VERSION ""

NS_ :

BS_:

BU_: WPC2 RLPSU DPSU APSU PSB SHVU_RR vHS_B2 FCS EMCU SLB ARS RCM CGW_CCU vDummy_HS_B ATS RLHV SGU PFSU ALBCU DSAU SWRC SHVU_FR RCS RRPSU BLTN_CAM SCM DLBCU OHCL RWPC RRHV WPC HOD ASAU

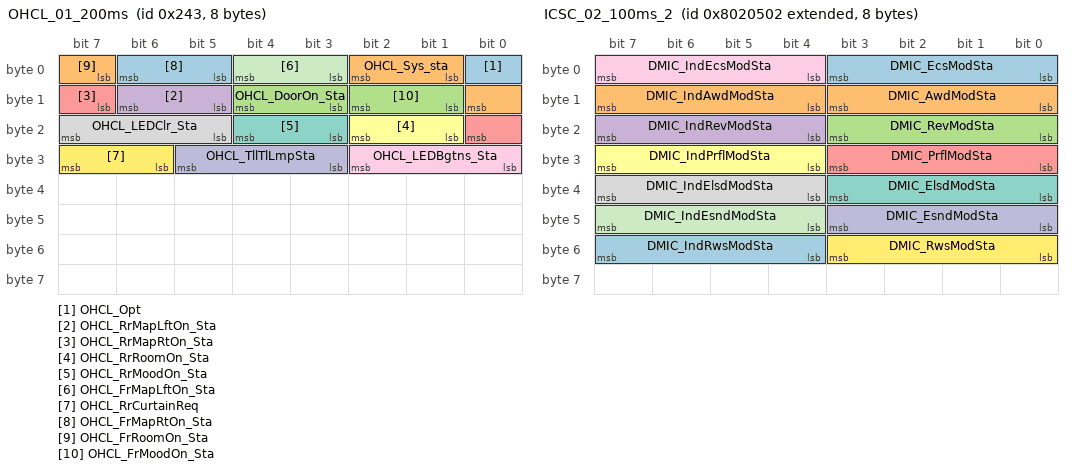
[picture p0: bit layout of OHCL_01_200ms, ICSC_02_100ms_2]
BO_ 579 OHCL_01_200ms: 8 OHCL
 SG_ OHCL_Opt : 0|1@1+ (1,0) [0|0] ""  ATS
 SG_ OHCL_Sys_sta : 1|2@1+ (1,0) [0|0] ""  ATS
 SG_ OHCL_DoorOn_Sta : 11|2@1+ (1,0) [0|0] ""  ATS
 SG_ OHCL_RrMapLftOn_Sta : 13|2@1+ (1,0) [0|0] ""  ATS
 SG_ OHCL_RrMapRtOn_Sta : 15|2@1+ (1,0) [0|0] ""  ATS
 SG_ OHCL_RrRoomOn_Sta : 17|2@1+ (1,0) [0|0] ""  ATS
 SG_ OHCL_RrMoodOn_Sta : 19|2@1+ (1,0) [0|0] ""  ATS
 SG_ OHCL_LEDClr_Sta : 21|3@1+ (1,0) [0|0] ""  ATS
 SG_ OHCL_LEDBgtns_Sta : 24|3@1+ (1,0) [0|0] ""  ATS
 SG_ OHCL_TllTlLmpSta : 27|3@1+ (1,0) [0|0] ""  CGW_CCU
 SG_ OHCL_FrMapLftOn_Sta : 3|2@1+ (1,0) [0|0] ""  ATS
 SG_ OHCL_RrCurtainReq : 30|2@1+ (1,0) [0|0] ""  Vector__XXX
 SG_ OHCL_FrMapRtOn_Sta : 5|2@1+ (1,0) [0|0] ""  ATS
 SG_ OHCL_FrRoomOn_Sta : 7|2@1+ (1,0) [0|0] ""  ATS
 SG_ OHCL_FrMoodOn_Sta : 9|2@1+ (1,0) [0|0] ""  ATS

BO_ 2281833730 ICSC_02_100ms_2: 8 CGW_CCU
 SG_ DMIC_EcsModSta : 0|4@1+ (1,0) [0|0] ""  Vector__XXX
 SG_ DMIC_IndAwdModSta : 12|4@1+ (1,0) [0|0] ""  Vector__XXX
 SG_ DMIC_RevModSta : 16|4@1+ (1,0) [0|0] ""  Vector__XXX
 SG_ DMIC_IndRevModSta : 20|4@1+ (1,0) [0|0] ""  Vector__XXX
 SG_ DMIC_PrflModSta : 24|4@1+ (1,0) [0|0] ""  Vector__XXX
 SG_ DMIC_IndPrflModSta : 28|4@1+ (1,0) [0|0] ""  Vector__XXX
 SG_ DMIC_ElsdModSta : 32|4@1+ (1,0) [0|0] ""  Vector__XXX
 SG_ DMIC_IndElsdModSta : 36|4@1+ (1,0) [0|0] ""  Vector__XXX
 SG_ DMIC_IndEcsModSta : 4|4@1+ (1,0) [0|0] ""  Vector__XXX
 SG_ DMIC_EsndModSta : 40|4@1+ (1,0) [0|0] ""  Vector__XXX
 SG_ DMIC_IndEsndModSta : 44|4@1+ (1,0) [0|0] ""  Vector__XXX
 SG_ DMIC_RwsModSta : 48|4@1+ (1,0) [0|0] ""  Vector__XXX
 SG_ DMIC_IndRwsModSta : 52|4@1+ (1,0) [0|0] ""  Vector__XXX
 SG_ DMIC_AwdModSta : 8|4@1+ (1,0) [0|0] ""  Vector__XXX

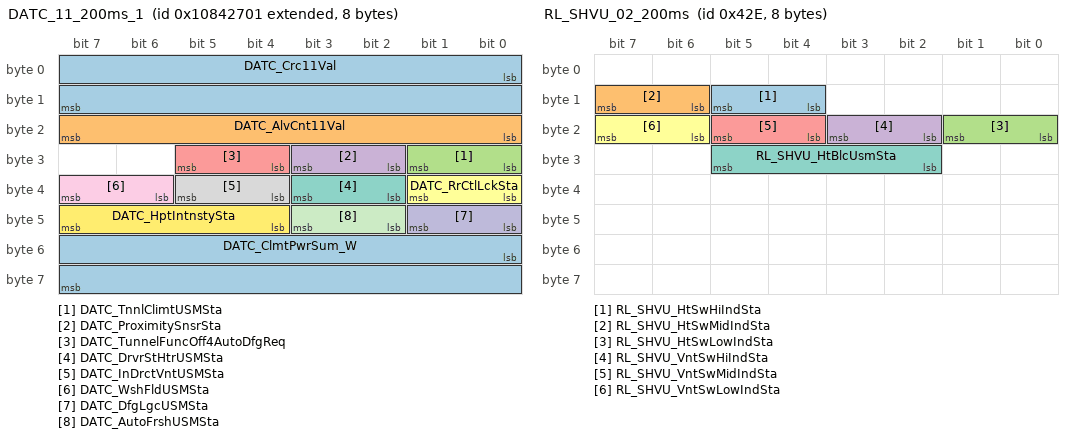
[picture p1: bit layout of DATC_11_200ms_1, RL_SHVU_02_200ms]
BO_ 2424579841 DATC_11_200ms_1: 8 CGW_CCU
 SG_ DATC_Crc11Val : 0|16@1+ (1,0) [0|0] ""  Vector__XXX
 SG_ DATC_AlvCnt11Val : 16|8@1+ (1,0) [0|0] ""  Vector__XXX
 SG_ DATC_TnnlClimtUSMSta : 24|2@1+ (1,0) [0|0] ""  Vector__XXX
 SG_ DATC_ProximitySnsrSta : 26|2@1+ (1,0) [0|0] ""  Vector__XXX
 SG_ DATC_TunnelFuncOff4AutoDfgReq : 28|2@1+ (1,0) [0|0] ""  Vector__XXX
 SG_ DATC_RrCtlLckSta : 32|2@1+ (1,0) [0|0] ""  ATS
 SG_ DATC_DrvrStHtrUSMSta : 34|2@1+ (1,0) [0|0] ""  APSU,DPSU
 SG_ DATC_InDrctVntUSMSta : 36|2@1+ (1,0) [0|0] ""  Vector__XXX
 SG_ DATC_WshFldUSMSta : 38|2@1+ (1,0) [0|0] ""  Vector__XXX
 SG_ DATC_DfgLgcUSMSta : 40|2@1+ (1,0) [0|0] ""  Vector__XXX
 SG_ DATC_AutoFrshUSMSta : 42|2@1+ (1,0) [0|0] ""  Vector__XXX
 SG_ DATC_HptIntnstySta : 44|4@1+ (1,0) [0|0] ""  Vector__XXX
 SG_ DATC_ClmtPwrSum_W : 48|16@1+ (1,0) [0|0] "Wh"  Vector__XXX

BO_ 1070 RL_SHVU_02_200ms: 8 SHVU_RR
 SG_ RL_SHVU_HtSwHiIndSta : 12|2@1+ (1,0) [0|0] ""  ATS,CGW_CCU
 SG_ RL_SHVU_HtSwMidIndSta : 14|2@1+ (1,0) [0|0] ""  ATS,CGW_CCU
 SG_ RL_SHVU_HtSwLowIndSta : 16|2@1+ (1,0) [0|0] ""  ATS,CGW_CCU
 SG_ RL_SHVU_VntSwHiIndSta : 18|2@1+ (1,0) [0|0] ""  ATS,CGW_CCU
 SG_ RL_SHVU_VntSwMidIndSta : 20|2@1+ (1,0) [0|0] ""  ATS,CGW_CCU
 SG_ RL_SHVU_VntSwLowIndSta : 22|2@1+ (1,0) [0|0] ""  ATS,CGW_CCU
 SG_ RL_SHVU_HtBlcUsmSta : 26|4@1+ (1,0) [0|0] ""  ATS,CGW_CCU,CGW_CCU

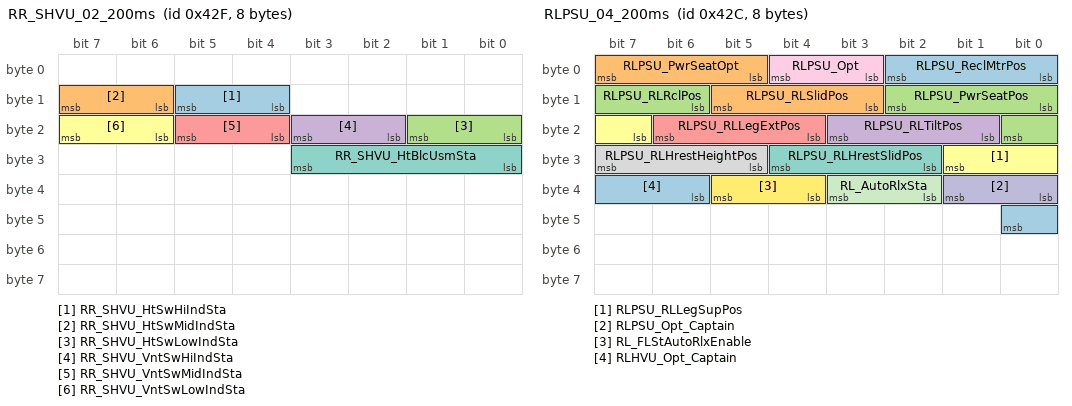
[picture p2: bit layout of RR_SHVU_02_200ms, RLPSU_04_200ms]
BO_ 1071 RR_SHVU_02_200ms: 8 RRPSU
 SG_ RR_SHVU_HtSwHiIndSta : 12|2@1+ (1,0) [0|0] ""  ATS,CGW_CCU
 SG_ RR_SHVU_HtSwMidIndSta : 14|2@1+ (1,0) [0|0] ""  ATS,CGW_CCU
 SG_ RR_SHVU_HtSwLowIndSta : 16|2@1+ (1,0) [0|0] ""  ATS,CGW_CCU
 SG_ RR_SHVU_VntSwHiIndSta : 18|2@1+ (1,0) [0|0] ""  ATS,CGW_CCU
 SG_ RR_SHVU_VntSwMidIndSta : 20|2@1+ (1,0) [0|0] ""  ATS,CGW_CCU
 SG_ RR_SHVU_VntSwLowIndSta : 22|2@1+ (1,0) [0|0] ""  ATS,CGW_CCU
 SG_ RR_SHVU_HtBlcUsmSta : 24|4@1+ (1,0) [0|0] ""  ATS,CGW_CCU,CGW_CCU

BO_ 1068 RLPSU_04_200ms: 8 RRPSU
 SG_ RLPSU_ReclMtrPos : 0|3@1+ (1,0) [0|0] ""  PFSU,CGW_CCU
 SG_ RLPSU_RLSlidPos : 11|3@1+ (1,0) [0|0] ""  CGW_CCU
 SG_ RLPSU_RLRclPos : 14|3@1+ (1,0) [0|0] ""  CGW_CCU
 SG_ RLPSU_RLTiltPos : 17|3@1+ (1,0) [0|0] ""  CGW_CCU
 SG_ RLPSU_RLLegExtPos : 20|3@1+ (1,0) [0|0] ""  CGW_CCU
 SG_ RLPSU_RLLegSupPos : 23|3@1+ (1,0) [0|0] ""  CGW_CCU
 SG_ RLPSU_RLHrestSlidPos : 26|3@1+ (1,0) [0|0] ""  CGW_CCU
 SG_ RLPSU_RLHrestHeightPos : 29|3@1+ (1,0) [0|0] ""  CGW_CCU
 SG_ RLPSU_Opt : 3|2@1+ (1,0) [0|0] ""  CGW_CCU
 SG_ RLPSU_Opt_Captain : 32|2@1+ (1,0) [0|0] ""  CGW_CCU
 SG_ RL_AutoRlxSta : 34|2@1+ (1,0) [0|0] ""  APSU,DPSU
 SG_ RL_FLStAutoRlxEnable : 36|2@1+ (1,0) [0|0] ""  APSU,DPSU
 SG_ RLHVU_Opt_Captain : 38|3@1+ (1,0) [0|0] ""  CGW_CCU
 SG_ RLPSU_PwrSeatOpt : 5|3@1+ (1,0) [0|0] ""  CGW_CCU
 SG_ RLPSU_PwrSeatPos : 8|3@1+ (1,0) [0|0] ""  CGW_CCU

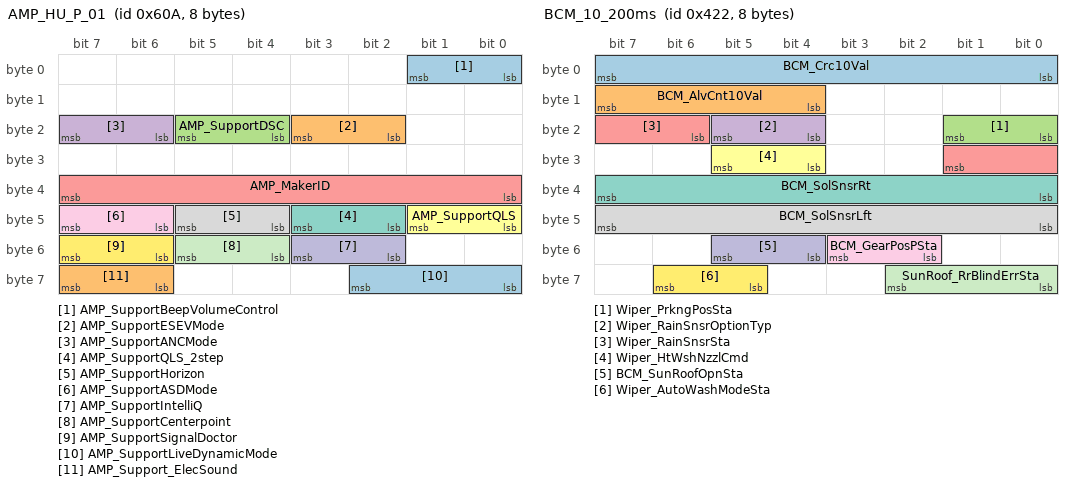
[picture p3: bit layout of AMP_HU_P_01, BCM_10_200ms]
BO_ 1546 AMP_HU_P_01: 8 CGW_CCU
 SG_ AMP_SupportBeepVolumeControl : 0|2@1+ (1,0) [0|0] ""  ATS
 SG_ AMP_SupportESEVMode : 18|2@1+ (1,0) [0|0] ""  Vector__XXX
 SG_ AMP_SupportDSC : 20|2@1+ (1,0) [0|0] ""  Vector__XXX
 SG_ AMP_SupportANCMode : 22|2@1+ (1,0) [0|0] ""  Vector__XXX
 SG_ AMP_MakerID : 32|8@1+ (1,0) [0|0] ""  Vector__XXX
 SG_ AMP_SupportQLS : 40|2@1+ (1,0) [0|0] ""  Vector__XXX
 SG_ AMP_SupportQLS_2step : 42|2@1+ (1,0) [0|0] ""  Vector__XXX
 SG_ AMP_SupportHorizon : 44|2@1+ (1,0) [0|0] ""  Vector__XXX
 SG_ AMP_SupportASDMode : 46|2@1+ (1,0) [0|0] ""  Vector__XXX
 SG_ AMP_SupportIntelliQ : 50|2@1+ (1,0) [0|0] ""  Vector__XXX
 SG_ AMP_SupportCenterpoint : 52|2@1+ (1,0) [0|0] ""  Vector__XXX
 SG_ AMP_SupportSignalDoctor : 54|2@1+ (1,0) [0|0] ""  Vector__XXX
 SG_ AMP_SupportLiveDynamicMode : 56|3@1+ (1,0) [0|0] ""  Vector__XXX
 SG_ AMP_Support_ElecSound : 62|2@1+ (1,0) [0|0] ""  Vector__XXX

BO_ 1069 RRPSU_04_200ms: 8 RRHV
 SG_ RRPSU_ReclMtrPos : 0|3@1+ (1,0) [0|0] ""  PFSU,CGW_CCU
 SG_ RRPSU_PwrSeatOpt : 11|3@1+ (1,0) [0|0] ""  CGW_CCU
 SG_ RRPSU_PwrSeatPos : 14|3@1+ (1,0) [0|0] ""  CGW_CCU
 SG_ RRPSU_RRSlidPos : 17|3@1+ (1,0) [0|0] ""  CGW_CCU
 SG_ RRPSU_RRRclPos : 20|3@1+ (1,0) [0|0] ""  CGW_CCU
 SG_ RRPSU_RRTiltPos : 23|3@1+ (1,0) [0|0] ""  CGW_CCU
 SG_ RRPSU_RRLegExtPos : 26|3@1+ (1,0) [0|0] ""  CGW_CCU
 SG_ RRPSU_RRLegSupPos : 29|3@1+ (1,0) [0|0] ""  CGW_CCU
 SG_ RRPSU_RRStEsyAcsUSMSta : 3|3@1+ (1,0) [0|0] ""  CGW_CCU
 SG_ RRPSU_RRHrestSlidPos : 32|3@1+ (1,0) [0|0] ""  CGW_CCU
 SG_ RRPSU_RRHrestHeightPos : 35|3@1+ (1,0) [0|0] ""  CGW_CCU
 SG_ RRPSU_Opt_Captain : 38|2@1+ (1,0) [0|0] ""  CGW_CCU
 SG_ RR_AutoRlxSta : 40|2@1+ (1,0) [0|0] ""  APSU,DPSU
 SG_ RR_FRStAutoRlxEnable : 42|2@1+ (1,0) [0|0] ""  APSU,DPSU
 SG_ RRHVU_Opt_Captain : 44|3@1+ (1,0) [0|0] ""  CGW_CCU
 SG_ RRPSU_RLStEsyAcsUSMSta : 6|3@1+ (1,0) [0|0] ""  CGW_CCU
 SG_ RRPSU_Opt : 9|2@1+ (1,0) [0|0] ""  CGW_CCU

BO_ 1058 BCM_10_200ms: 8 CGW_CCU
 SG_ BCM_Crc10Val : 0|8@1+ (1,0) [0|0] ""  Vector__XXX
 SG_ BCM_AlvCnt10Val : 12|4@1+ (1,0) [0|0] ""  Vector__XXX
 SG_ Wiper_PrkngPosSta : 16|2@1+ (1,0) [0|0] ""  Vector__XXX
 SG_ Wiper_RainSnsrOptionTyp : 20|2@1+ (1,0) [0|0] ""  Vector__XXX
 SG_ Wiper_RainSnsrSta : 22|4@1+ (1,0) [0|0] ""  Vector__XXX
 SG_ Wiper_HtWshNzzlCmd : 28|2@1+ (1,0) [0|0] ""  Vector__XXX
 SG_ BCM_SolSnsrRt : 32|8@1+ (4.72441,0) [0|0] "W/m2"  Vector__XXX
 SG_ BCM_SolSnsrLft : 40|8@1+ (4.72441,0) [0|0] "W/m2"  Vector__XXX
 SG_ BCM_GearPosPSta : 50|2@1+ (1,0) [0|0] ""  SCM,APSU,RLHV,RRHV,DPSU,PFSU,RRPSU,RLPSU,ATS
 SG_ BCM_SunRoofOpnSta : 52|2@1+ (1,0) [0|0] ""  Vector__XXX
 SG_ SunRoof_RrBlindErrSta : 56|3@1+ (1,0) [0|0] ""  Vector__XXX
 SG_ Wiper_AutoWashModeSta : 61|2@1+ (1,0) [0|0] ""  Vector__XXX

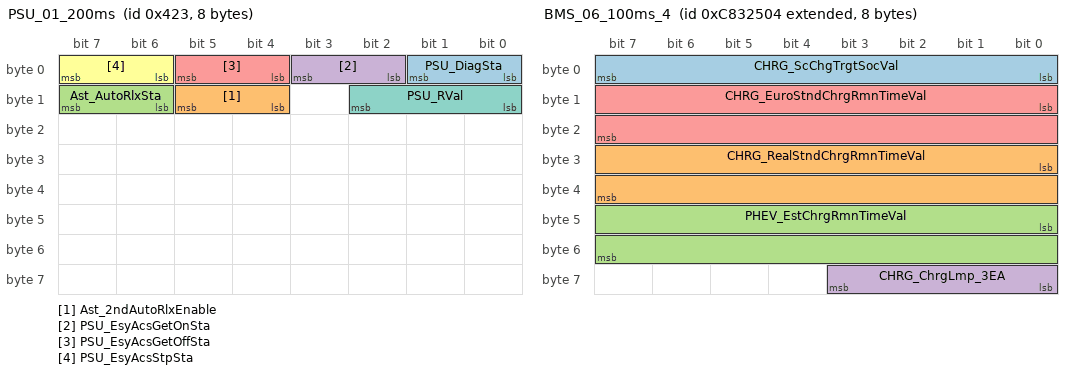
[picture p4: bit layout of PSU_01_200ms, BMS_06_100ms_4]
BO_ 1059 PSU_01_200ms: 8 APSU
 SG_ PSU_DiagSta : 0|2@1+ (1,0) [0|0] ""  Vector__XXX
 SG_ Ast_2ndAutoRlxEnable : 12|2@1+ (1,0) [0|0] ""  RLPSU,RRPSU
 SG_ Ast_AutoRlxSta : 14|2@1+ (1,0) [0|0] ""  RLPSU,RRPSU
 SG_ PSU_EsyAcsGetOnSta : 2|2@1+ (1,0) [0|0] ""  SLB
 SG_ PSU_EsyAcsGetOffSta : 4|2@1+ (1,0) [0|0] ""  SLB
 SG_ PSU_EsyAcsStpSta : 6|2@1+ (1,0) [0|0] ""  SLB
 SG_ PSU_RVal : 8|3@1+ (1,0) [0|0] ""  Vector__XXX

BO_ 2357404932 BMS_06_100ms_4: 8 CGW_CCU
 SG_ CHRG_ScChgTrgtSocVal : 0|8@1+ (0.5,0) [0|0] "%"  Vector__XXX
 SG_ CHRG_RealStndChrgRmnTimeVal : 24|16@1+ (1,0) [0|0] "minute"  Vector__XXX
 SG_ PHEV_EstChrgRmnTimeVal : 40|16@1+ (1,0) [0|0] "min"  Vector__XXX
 SG_ CHRG_ChrgLmp_3EA : 56|4@1+ (1,0) [0|0] "minute"  Vector__XXX
 SG_ CHRG_EuroStndChrgRmnTimeVal : 8|16@1+ (1,0) [0|0] "minute"  Vector__XXX

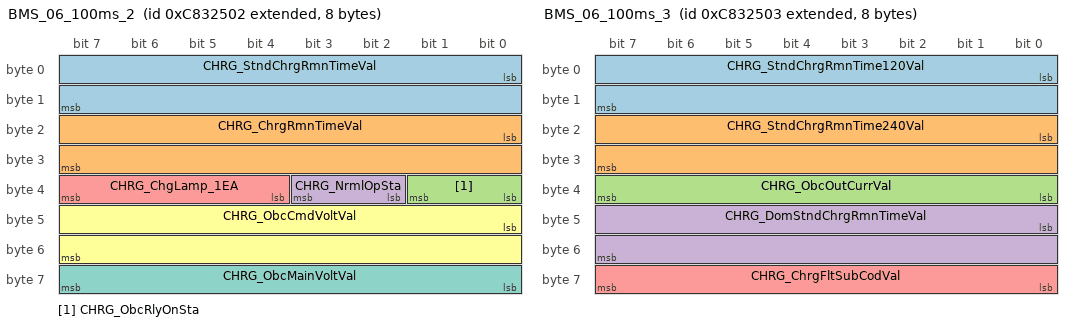
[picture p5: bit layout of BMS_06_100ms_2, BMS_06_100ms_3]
BO_ 2357404930 BMS_06_100ms_2: 8 CGW_CCU
 SG_ CHRG_StndChrgRmnTimeVal : 0|16@1+ (1,0) [0|0] "minute"  Vector__XXX
 SG_ CHRG_ChrgRmnTimeVal : 16|16@1+ (1,0) [0|0] "min"  Vector__XXX
 SG_ CHRG_ObcRlyOnSta : 32|2@1+ (1,0) [0|0] ""  Vector__XXX
 SG_ CHRG_NrmlOpSta : 34|2@1+ (1,0) [0|0] ""  Vector__XXX
 SG_ CHRG_ChgLamp_1EA : 36|4@1+ (1,0) [0|0] ""  Vector__XXX
 SG_ CHRG_ObcCmdVoltVal : 40|16@1+ (0.1,0) [0|0] "V"  Vector__XXX
 SG_ CHRG_ObcMainVoltVal : 56|8@1+ (2,0) [0|0] "V"  Vector__XXX

BO_ 2357404931 BMS_06_100ms_3: 8 CGW_CCU
 SG_ CHRG_StndChrgRmnTime120Val : 0|16@1+ (1,0) [0|0] "minute"  Vector__XXX
 SG_ CHRG_StndChrgRmnTime240Val : 16|16@1+ (1,0) [0|0] "minute"  Vector__XXX
 SG_ CHRG_ObcOutCurrVal : 32|8@1+ (0.1,0) [0|0] "A"  Vector__XXX
 SG_ CHRG_DomStndChrgRmnTimeVal : 40|16@1+ (1,0) [0|0] "minute"  Vector__XXX
 SG_ CHRG_ChrgFltSubCodVal : 56|8@1+ (1,0) [0|0] ""  Vector__XXX

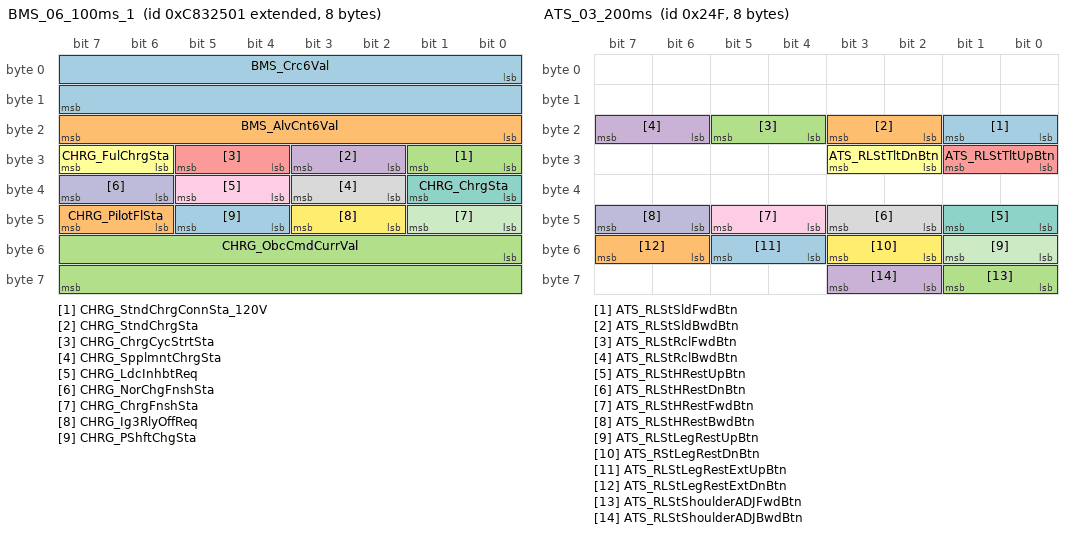
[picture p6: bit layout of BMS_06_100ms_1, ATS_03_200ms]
BO_ 2357404929 BMS_06_100ms_1: 8 CGW_CCU
 SG_ BMS_Crc6Val : 0|16@1+ (1,0) [0|0] ""  Vector__XXX
 SG_ BMS_AlvCnt6Val : 16|8@1+ (1,0) [0|0] ""  Vector__XXX
 SG_ CHRG_StndChrgConnSta_120V : 24|2@1+ (1,0) [0|0] "flag"  Vector__XXX
 SG_ CHRG_StndChrgSta : 26|2@1+ (1,0) [0|0] ""  Vector__XXX
 SG_ CHRG_ChrgCycStrtSta : 28|2@1+ (1,0) [0|0] ""  Vector__XXX
 SG_ CHRG_FulChrgSta : 30|2@1+ (1,0) [0|0] ""  Vector__XXX
 SG_ CHRG_ChrgSta : 32|2@1+ (1,0) [0|0] ""  SWRC
 SG_ CHRG_SpplmntChrgSta : 34|2@1+ (1,0) [0|0] ""  Vector__XXX
 SG_ CHRG_LdcInhbtReq : 36|2@1+ (1,0) [0|0] ""  Vector__XXX
 SG_ CHRG_NorChgFnshSta : 38|2@1+ (1,0) [0|0] ""  Vector__XXX
 SG_ CHRG_ChrgFnshSta : 40|2@1+ (1,0) [0|0] ""  Vector__XXX
 SG_ CHRG_Ig3RlyOffReq : 42|2@1+ (1,0) [0|0] ""  Vector__XXX
 SG_ CHRG_PShftChgSta : 44|2@1+ (1,0) [0|0] "flag"  Vector__XXX
 SG_ CHRG_PilotFlSta : 46|2@1+ (1,0) [0|0] "flag"  Vector__XXX
 SG_ CHRG_ObcCmdCurrVal : 48|16@1+ (0.1,0) [0|0] "A"  Vector__XXX

BO_ 591 ATS_03_200ms: 8 ATS
 SG_ ATS_RLStSldFwdBtn : 16|2@1+ (1,0) [0|0] ""  Vector__XXX
 SG_ ATS_RLStSldBwdBtn : 18|2@1+ (1,0) [0|0] ""  Vector__XXX
 SG_ ATS_RLStRclFwdBtn : 20|2@1+ (1,0) [0|0] ""  Vector__XXX
 SG_ ATS_RLStRclBwdBtn : 22|2@1+ (1,0) [0|0] ""  Vector__XXX
 SG_ ATS_RLStTltUpBtn : 24|2@1+ (1,0) [0|0] ""  Vector__XXX
 SG_ ATS_RLStTltDnBtn : 26|2@1+ (1,0) [0|0] ""  Vector__XXX
 SG_ ATS_RLStHRestUpBtn : 40|2@1+ (1,0) [0|0] ""  Vector__XXX
 SG_ ATS_RLStHRestDnBtn : 42|2@1+ (1,0) [0|0] ""  Vector__XXX
 SG_ ATS_RLStHRestFwdBtn : 44|2@1+ (1,0) [0|0] ""  Vector__XXX
 SG_ ATS_RLStHRestBwdBtn : 46|2@1+ (1,0) [0|0] ""  Vector__XXX
 SG_ ATS_RLStLegRestUpBtn : 48|2@1+ (1,0) [0|0] ""  Vector__XXX
 SG_ ATS_RStLegRestDnBtn : 50|2@1+ (1,0) [0|0] ""  Vector__XXX
 SG_ ATS_RLStLegRestExtUpBtn : 52|2@1+ (1,0) [0|0] ""  Vector__XXX
 SG_ ATS_RLStLegRestExtDnBtn : 54|2@1+ (1,0) [0|0] ""  Vector__XXX
 SG_ ATS_RLStShoulderADJFwdBtn : 56|2@1+ (1,0) [0|0] ""  Vector__XXX
 SG_ ATS_RLStShoulderADJBwdBtn : 58|2@1+ (1,0) [0|0] ""  Vector__XXX

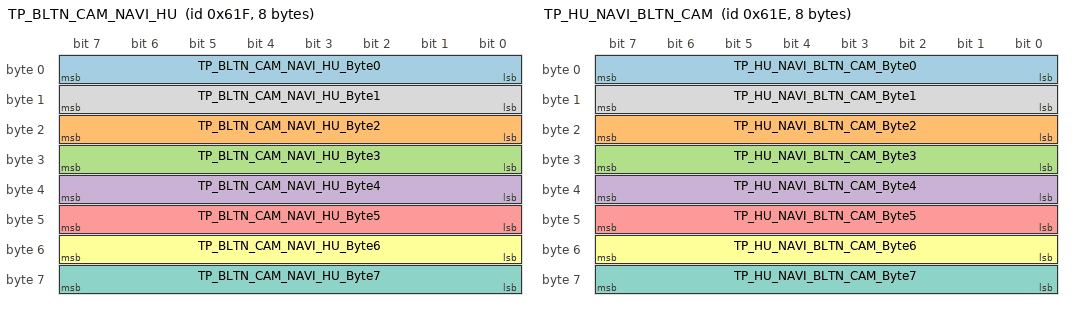
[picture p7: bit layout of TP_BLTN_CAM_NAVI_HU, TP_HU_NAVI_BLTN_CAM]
BO_ 1567 TP_BLTN_CAM_NAVI_HU: 8 BLTN_CAM
 SG_ TP_BLTN_CAM_NAVI_HU_Byte0 : 0|8@1+ (1,0) [0|0] ""  CGW_CCU
 SG_ TP_BLTN_CAM_NAVI_HU_Byte2 : 16|8@1+ (1,0) [0|0] ""  CGW_CCU
 SG_ TP_BLTN_CAM_NAVI_HU_Byte3 : 24|8@1+ (1,0) [0|0] ""  CGW_CCU
 SG_ TP_BLTN_CAM_NAVI_HU_Byte4 : 32|8@1+ (1,0) [0|0] ""  CGW_CCU
 SG_ TP_BLTN_CAM_NAVI_HU_Byte5 : 40|8@1+ (1,0) [0|0] ""  CGW_CCU
 SG_ TP_BLTN_CAM_NAVI_HU_Byte6 : 48|8@1+ (1,0) [0|0] ""  CGW_CCU
 SG_ TP_BLTN_CAM_NAVI_HU_Byte7 : 56|8@1+ (1,0) [0|0] ""  CGW_CCU
 SG_ TP_BLTN_CAM_NAVI_HU_Byte1 : 8|8@1+ (1,0) [0|0] ""  CGW_CCU

BO_ 1566 TP_HU_NAVI_BLTN_CAM: 8 CGW_CCU
 SG_ TP_HU_NAVI_BLTN_CAM_Byte0 : 0|8@1+ (1,0) [0|0] ""  BLTN_CAM
 SG_ TP_HU_NAVI_BLTN_CAM_Byte2 : 16|8@1+ (1,0) [0|0] ""  BLTN_CAM
 SG_ TP_HU_NAVI_BLTN_CAM_Byte3 : 24|8@1+ (1,0) [0|0] ""  BLTN_CAM
 SG_ TP_HU_NAVI_BLTN_CAM_Byte4 : 32|8@1+ (1,0) [0|0] ""  BLTN_CAM
 SG_ TP_HU_NAVI_BLTN_CAM_Byte5 : 40|8@1+ (1,0) [0|0] ""  BLTN_CAM
 SG_ TP_HU_NAVI_BLTN_CAM_Byte6 : 48|8@1+ (1,0) [0|0] ""  BLTN_CAM
 SG_ TP_HU_NAVI_BLTN_CAM_Byte7 : 56|8@1+ (1,0) [0|0] ""  BLTN_CAM
 SG_ TP_HU_NAVI_BLTN_CAM_Byte1 : 8|8@1+ (1,0) [0|0] ""  BLTN_CAM

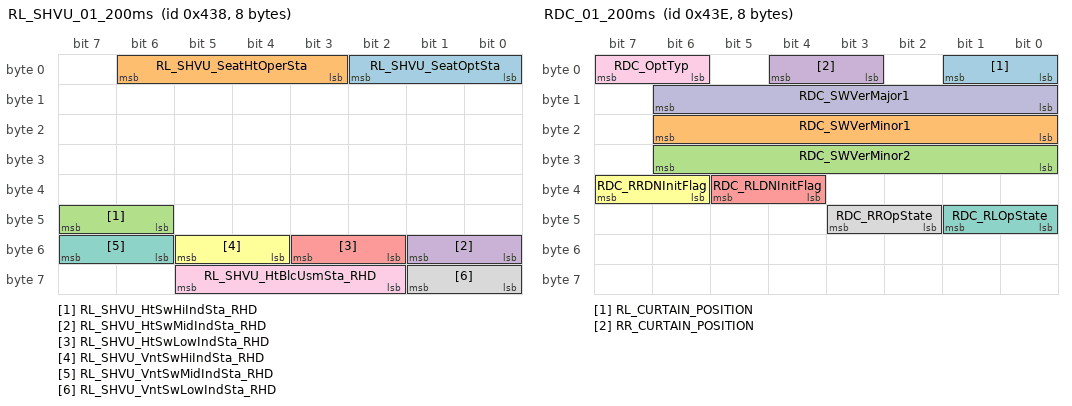
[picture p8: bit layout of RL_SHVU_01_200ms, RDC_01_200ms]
BO_ 1080 RL_SHVU_01_200ms: 8 SHVU_FR
 SG_ RL_SHVU_SeatOptSta : 0|3@1+ (1,0) [0|0] ""  ATS,CGW_CCU
 SG_ RL_SHVU_SeatHtOperSta : 3|4@1+ (1,0) [0|0] ""  ATS,CGW_CCU
 SG_ RL_SHVU_HtSwHiIndSta_RHD : 46|2@1+ (1,0) [0|0] ""  ATS,CGW_CCU,CGW_CCU
 SG_ RL_SHVU_HtSwMidIndSta_RHD : 48|2@1+ (1,0) [0|0] ""  ATS,CGW_CCU
 SG_ RL_SHVU_HtSwLowIndSta_RHD : 50|2@1+ (1,0) [0|0] ""  ATS,CGW_CCU
 SG_ RL_SHVU_VntSwHiIndSta_RHD : 52|2@1+ (1,0) [0|0] ""  ATS,CGW_CCU
 SG_ RL_SHVU_VntSwMidIndSta_RHD : 54|2@1+ (1,0) [0|0] ""  ATS,CGW_CCU
 SG_ RL_SHVU_VntSwLowIndSta_RHD : 56|2@1+ (1,0) [0|0] ""  ATS,CGW_CCU
 SG_ RL_SHVU_HtBlcUsmSta_RHD : 58|4@1+ (1,0) [0|0] ""  ATS,CGW_CCU

BO_ 1086 RDC_01_200ms: 8 CGW_CCU
 SG_ RL_CURTAIN_POSITION : 0|2@1+ (1,0) [0|0] ""  ATS
 SG_ RDC_SWVerMinor1 : 16|7@1+ (1,0) [0|0] ""  Vector__XXX
 SG_ RDC_SWVerMinor2 : 24|7@1+ (1,0) [0|0] ""  Vector__XXX
 SG_ RR_CURTAIN_POSITION : 3|2@1+ (1,0) [0|0] ""  ATS
 SG_ RDC_RLDNInitFlag : 36|2@1+ (1,0) [0|0] ""  Vector__XXX
 SG_ RDC_RRDNInitFlag : 38|2@1+ (1,0) [0|0] ""  Vector__XXX
 SG_ RDC_RLOpState : 40|2@1+ (1,0) [0|0] ""  Vector__XXX
 SG_ RDC_RROpState : 42|2@1+ (1,0) [0|0] ""  Vector__XXX
 SG_ RDC_OptTyp : 6|2@1+ (1,0) [0|0] ""  ATS
 SG_ RDC_SWVerMajor1 : 8|7@1+ (1,0) [0|0] ""  Vector__XXX

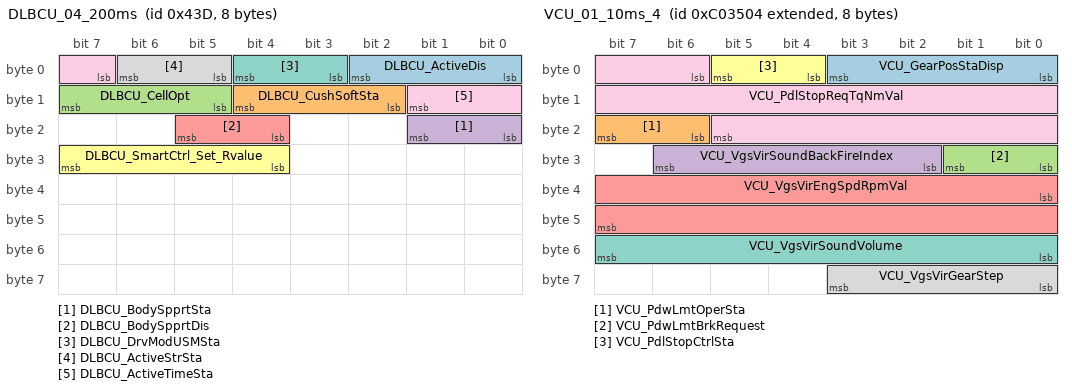
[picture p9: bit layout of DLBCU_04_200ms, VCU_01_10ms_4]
BO_ 1085 DLBCU_04_200ms: 8 DLBCU
 SG_ DLBCU_ActiveDis : 0|3@1+ (1,0) [0|0] ""  CGW_CCU
 SG_ DLBCU_CushSoftSta : 10|3@1+ (1,0) [0|0] ""  CGW_CCU
 SG_ DLBCU_CellOpt : 13|3@1+ (1,0) [0|0] ""  Vector__XXX
 SG_ DLBCU_BodySpprtSta : 16|2@1+ (1,0) [0|0] ""  CGW_CCU
 SG_ DLBCU_BodySpprtDis : 20|2@1+ (1,0) [0|0] ""  CGW_CCU
 SG_ DLBCU_SmartCtrl_Set_Rvalue : 28|4@1+ (1,0) [0|0] ""  CGW_CCU
 SG_ DLBCU_DrvModUSMSta : 3|2@1+ (1,0) [0|0] ""  CGW_CCU
 SG_ DLBCU_ActiveStrSta : 5|2@1+ (1,0) [0|0] ""  CGW_CCU
 SG_ DLBCU_ActiveTimeSta : 7|3@1+ (1,0) [0|0] ""  CGW_CCU

BO_ 2160080132 VCU_01_10ms_4: 8 CGW_CCU
 SG_ VCU_GearPosStaDisp : 0|4@1+ (1,0) [0|0] ""  SWRC,BLTN_CAM
 SG_ VCU_PdwLmtOperSta : 22|2@1+ (1,0) [0|0] ""  Vector__XXX
 SG_ VCU_PdwLmtBrkRequest : 24|2@1+ (1,0) [0|0] ""  Vector__XXX
 SG_ VCU_VgsVirSoundBackFireIndex : 26|5@1+ (1,0) [0|0] ""  Vector__XXX
 SG_ VCU_VgsVirEngSpdRpmVal : 32|16@1- (1,0) [0|0] ""  Vector__XXX
 SG_ VCU_PdlStopCtrlSta : 4|2@1+ (1,0) [0|0] ""  Vector__XXX
 SG_ VCU_VgsVirSoundVolume : 48|8@1+ (0.392156863,0) [0|0] ""  Vector__XXX
 SG_ VCU_VgsVirGearStep : 56|4@1+ (1,0) [0|0] ""  Vector__XXX
 SG_ VCU_PdlStopReqTqNmVal : 6|16@1+ (1,0) [0|0] ""  Vector__XXX

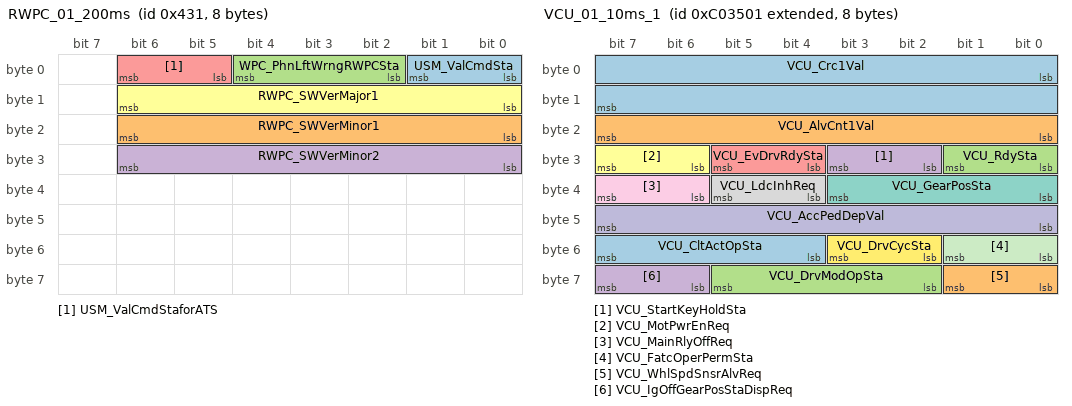
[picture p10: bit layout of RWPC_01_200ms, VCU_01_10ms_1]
BO_ 1073 RWPC_01_200ms: 8 RWPC
 SG_ USM_ValCmdSta : 0|2@1+ (1,0) [0|0] ""  ATS,CGW_CCU
 SG_ RWPC_SWVerMinor1 : 16|7@1+ (1,0) [0|0] ""  CGW_CCU
 SG_ WPC_PhnLftWrngRWPCSta : 2|3@1+ (1,0) [0|0] ""  ATS,CGW_CCU
 SG_ RWPC_SWVerMinor2 : 24|7@1+ (1,0) [0|0] ""  CGW_CCU
 SG_ USM_ValCmdStaforATS : 5|2@1+ (1,0) [0|0] ""  ATS
 SG_ RWPC_SWVerMajor1 : 8|7@1+ (1,0) [0|0] ""  CGW_CCU

BO_ 2160080129 VCU_01_10ms_1: 8 CGW_CCU
 SG_ VCU_Crc1Val : 0|16@1+ (1,0) [0|0] ""  Vector__XXX
 SG_ VCU_AlvCnt1Val : 16|8@1+ (1,0) [0|0] ""  Vector__XXX
 SG_ VCU_RdySta : 24|2@1+ (1,0) [0|3] ""  Vector__XXX
 SG_ VCU_StartKeyHoldSta : 26|2@1+ (1,0) [0|3] ""  Vector__XXX
 SG_ VCU_EvDrvRdySta : 28|2@1+ (1,0) [0|3] ""  WPC,RWPC,SWRC,APSU,RLHV,RRHV,SHVU_FR,SHVU_RR,DPSU,DLBCU,PFSU,RRPSU,RLPSU,HOD,RCM,BLTN_CAM,WPC2
 SG_ VCU_MotPwrEnReq : 30|2@1+ (1,0) [0|3] ""  Vector__XXX
 SG_ VCU_GearPosSta : 32|4@1+ (1,0) [0|15] ""  SWRC,APSU,DPSU,PFSU,RRPSU,RLPSU,BLTN_CAM,WPC2
 SG_ VCU_LdcInhReq : 36|2@1+ (1,0) [0|3] ""  Vector__XXX
 SG_ VCU_MainRlyOffReq : 38|2@1+ (1,0) [0|3] ""  Vector__XXX
 SG_ VCU_AccPedDepVal : 40|8@1+ (0.3921568627,0) [0|100] "%"  BLTN_CAM
 SG_ VCU_FatcOperPermSta : 48|2@1+ (1,0) [0|3] ""  Vector__XXX
 SG_ VCU_DrvCycSta : 50|2@1+ (1,0) [0|3] ""  Vector__XXX
 SG_ VCU_CltActOpSta : 52|4@1+ (1,0) [0|15] ""  Vector__XXX
 SG_ VCU_WhlSpdSnsrAlvReq : 56|2@1+ (1,0) [0|0] "flag"  Vector__XXX
 SG_ VCU_DrvModOpSta : 58|4@1+ (1,0) [0|0] ""  Vector__XXX
 SG_ VCU_IgOffGearPosStaDispReq : 62|2@1+ (1,0) [0|0] "flag"  Vector__XXX

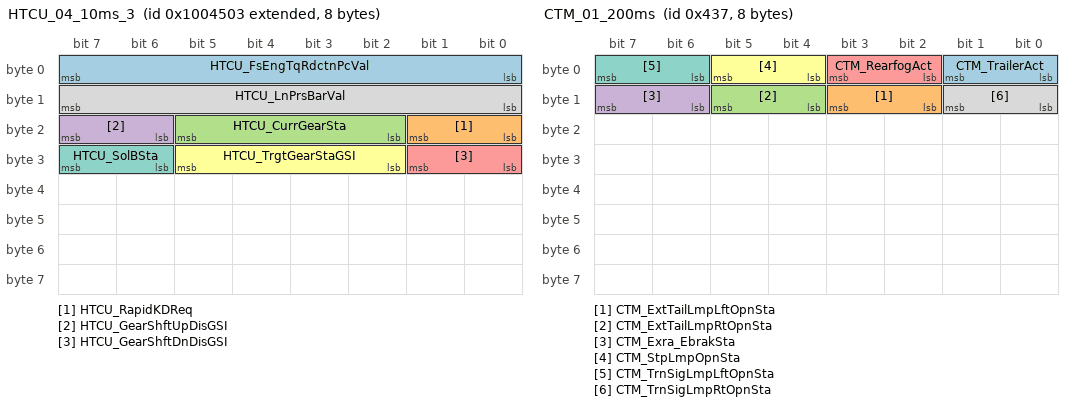
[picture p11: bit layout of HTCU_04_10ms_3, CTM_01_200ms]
BO_ 2164278531 HTCU_04_10ms_3: 8 CGW_CCU
 SG_ HTCU_FsEngTqRdctnPcVal : 0|8@1+ (0.390625,0) [0|0] "%"  Vector__XXX
 SG_ HTCU_RapidKDReq : 16|2@1+ (1,0) [0|0] ""  Vector__XXX
 SG_ HTCU_CurrGearSta : 18|4@1+ (1,0) [0|0] ""  Vector__XXX
 SG_ HTCU_GearShftUpDisGSI : 22|2@1+ (1,0) [0|0] ""  Vector__XXX
 SG_ HTCU_GearShftDnDisGSI : 24|2@1+ (1,0) [0|0] ""  Vector__XXX
 SG_ HTCU_TrgtGearStaGSI : 26|4@1+ (1,0) [0|0] ""  Vector__XXX
 SG_ HTCU_SolBSta : 30|2@1+ (1,0) [0|0] ""  Vector__XXX
 SG_ HTCU_LnPrsBarVal : 8|8@1+ (0.1,0) [0|0] "Bar"  Vector__XXX

BO_ 1079 CTM_01_200ms: 8 CGW_CCU
 SG_ CTM_TrailerAct : 0|2@1+ (1,0) [0|0] ""  BLTN_CAM
 SG_ CTM_ExtTailLmpLftOpnSta : 10|2@1+ (1,0) [0|0] ""  Vector__XXX
 SG_ CTM_ExtTailLmpRtOpnSta : 12|2@1+ (1,0) [0|0] ""  Vector__XXX
 SG_ CTM_Exra_EbrakSta : 14|2@1+ (1,0) [0|0] ""  Vector__XXX
 SG_ CTM_RearfogAct : 2|2@1+ (1,0) [0|0] ""  Vector__XXX
 SG_ CTM_StpLmpOpnSta : 4|2@1+ (1,0) [0|0] ""  Vector__XXX
 SG_ CTM_TrnSigLmpLftOpnSta : 6|2@1+ (1,0) [0|0] ""  Vector__XXX
 SG_ CTM_TrnSigLmpRtOpnSta : 8|2@1+ (1,0) [0|0] ""  Vector__XXX

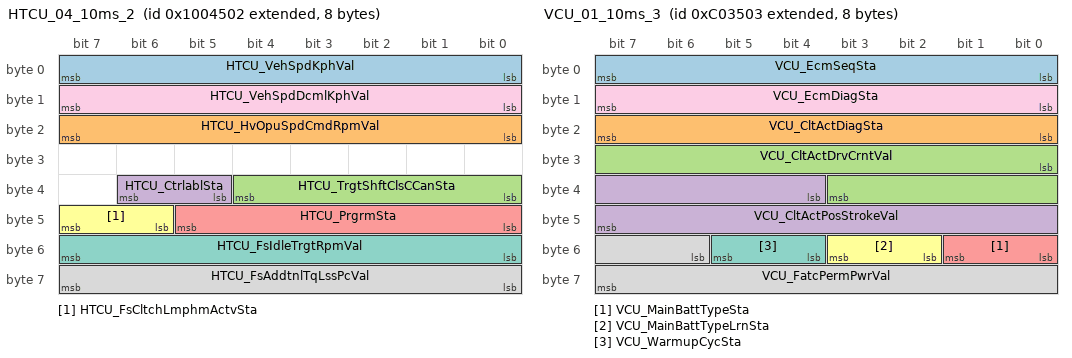
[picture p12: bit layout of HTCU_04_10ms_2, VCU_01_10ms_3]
BO_ 2164278530 HTCU_04_10ms_2: 8 CGW_CCU
 SG_ HTCU_VehSpdKphVal : 0|8@1+ (1,0) [0|0] "kph"  Vector__XXX
 SG_ HTCU_HvOpuSpdCmdRpmVal : 16|8@1+ (20,0) [0|0] "rpm"  Vector__XXX
 SG_ HTCU_TrgtShftClsCCanSta : 32|5@1+ (1,0) [0|0] ""  Vector__XXX
 SG_ HTCU_CtrlablSta : 37|2@1+ (1,0) [0|0] ""  Vector__XXX
 SG_ HTCU_PrgrmSta : 40|6@1+ (1,0) [0|0] ""  Vector__XXX
 SG_ HTCU_FsCltchLmphmActvSta : 46|2@1+ (1,0) [0|0] ""  Vector__XXX
 SG_ HTCU_FsIdleTrgtRpmVal : 48|8@1+ (10,0) [0|0] "rpm"  Vector__XXX
 SG_ HTCU_FsAddtnlTqLssPcVal : 56|8@1+ (0.390625,0) [0|0] "%"  Vector__XXX
 SG_ HTCU_VehSpdDcmlKphVal : 8|8@1+ (0.0078125,0) [0|0] "kph"  Vector__XXX

BO_ 2160080131 VCU_01_10ms_3: 8 CGW_CCU
 SG_ VCU_EcmSeqSta : 0|8@1+ (1,0) [0|255] ""  Vector__XXX
 SG_ VCU_CltActDiagSta : 16|8@1+ (1,0) [0|255] ""  Vector__XXX
 SG_ VCU_CltActDrvCrntVal : 24|12@1- (0.025,0) [-51.2|51.175] "A"  Vector__XXX
 SG_ VCU_CltActPosStrokeVal : 36|12@1- (0.0125,0) [-25.6|25.5875] "mm"  Vector__XXX
 SG_ VCU_MainBattTypeSta : 48|2@1+ (1,0) [0|3] ""  Vector__XXX
 SG_ VCU_MainBattTypeLrnSta : 50|2@1+ (1,0) [0|3] ""  Vector__XXX
 SG_ VCU_WarmupCycSta : 52|2@1+ (1,0) [0|3] ""  Vector__XXX
 SG_ VCU_FatcPermPwrVal : 54|10@1+ (20,0) [0|12700] "W"  Vector__XXX
 SG_ VCU_EcmDiagSta : 8|8@1+ (1,0) [0|255] ""  Vector__XXX

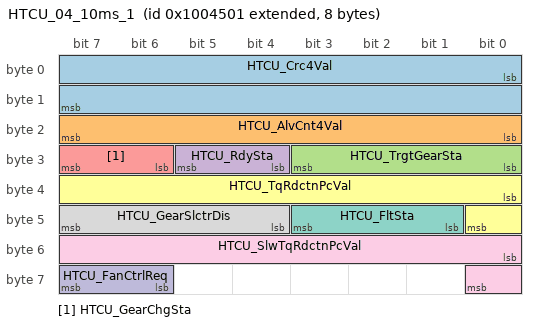
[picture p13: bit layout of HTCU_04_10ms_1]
BO_ 2164278529 HTCU_04_10ms_1: 8 CGW_CCU
 SG_ HTCU_Crc4Val : 0|16@1+ (1,0) [0|0] ""  Vector__XXX
 SG_ HTCU_AlvCnt4Val : 16|8@1+ (1,0) [0|0] ""  Vector__XXX
 SG_ HTCU_TrgtGearSta : 24|4@1+ (1,0) [0|0] ""  Vector__XXX
 SG_ HTCU_RdySta : 28|2@1+ (1,0) [0|0] ""  Vector__XXX
 SG_ HTCU_GearChgSta : 30|2@1+ (1,0) [0|0] ""  Vector__XXX
 SG_ HTCU_TqRdctnPcVal : 32|9@1+ (0.390625,0) [0|0] "%"  Vector__XXX
 SG_ HTCU_FltSta : 41|3@1+ (1,0) [0|0] ""  Vector__XXX
 SG_ HTCU_GearSlctrDis : 44|4@1+ (1,0) [0|0] ""  SWRC,BLTN_CAM
 SG_ HTCU_SlwTqRdctnPcVal : 48|9@1+ (0.390625,0) [0|0] "%"  Vector__XXX
 SG_ HTCU_FanCtrlReq : 62|2@1+ (1,0) [0|0] ""  Vector__XXX

BO_TX_BU_ 1070 : SHVU_RR,RLHV,RLPSU,SHVU_FR;
BO_TX_BU_ 1071 : RRPSU,SHVU_FR,SHVU_RR,RRHV;
BO_TX_BU_ 1068 : RRPSU,RLPSU,RLHV;
BO_TX_BU_ 1069 : RRHV,RRPSU;
BO_TX_BU_ 1080 : SHVU_FR,SHVU_RR,RLHV,RLPSU;
CM_ BO_ 1546 "[P] Periodic";
CM_ SG_ 1546 AMP_SupportBeepVolumeControl "Information for AMPsupport configurable Beep1
send 500msec after Booting up";
CM_ SG_ 1546 AMP_SupportESEVMode "Information for AMP support ESEV(Engine Sound by Engine Vibration).";
CM_ SG_ 1546 AMP_SupportDSC "Does amp support Dynamic Speed Compensation mode?";
CM_ SG_ 1546 AMP_SupportANCMode "Does AMP support ANC?";
CM_ SG_ 1546 AMP_MakerID "Information for AMP Maker
For model afrer 2014, use 0x01~0x03 only.
* Use Only 0x01~0x03 values after 2014 *";
CM_ SG_ 1546 AMP_SupportQLS "Information for amp support Quantum Logic Surround mode
Harman AMP Only";
CM_ SG_ 1546 AMP_SupportQLS_2step "Information for amp support 2 Step Quantum Logic Surround mode Harman AMP Only";
CM_ SG_ 1546 AMP_SupportHorizon "Information for amp support Meridian Horizon mode Meridian AMP Only";
CM_ SG_ 1546 AMP_SupportASDMode "Information for  AMP support ASD (Active Sound Design, Virtual Engine Sound)";
CM_ SG_ 1546 AMP_SupportIntelliQ "Does amp support Meridian Intelli-Q mode?";
CM_ SG_ 1546 AMP_SupportCenterpoint "Does amp support CenterPoint mode?";
CM_ SG_ 1546 AMP_SupportSignalDoctor "Information for amp support SignalDoctor(=Clarifi)
Harman AMP Only";
CM_ SG_ 1546 AMP_SupportLiveDynamicMode "Information for amp
 Support
 LiveDynamic mode";
CM_ SG_ 1546 AMP_Support_ElecSound "inform to H/U & CLU whether amp support premium electric sound or not";
CM_ BO_ 591 "[PE] Periodic and On Event";
CM_ SG_ 591 ATS_RLStSldFwdBtn "Rear Left Power Seat Slide Forward Touch Button";
CM_ SG_ 591 ATS_RLStSldBwdBtn "Rear Left Power Seat Slide Backward Touch Button";
CM_ SG_ 591 ATS_RLStRclFwdBtn "Rear Left Power Seat Recline Forward Touch Button";
CM_ SG_ 591 ATS_RLStRclBwdBtn "Rear Left Power Seat Recline Backward Touch Button";
CM_ SG_ 591 ATS_RLStTltUpBtn "Rear Left Power Seat Tilt Up Touch Button";
CM_ SG_ 591 ATS_RLStTltDnBtn "Rear Left Power Seat Tilt Down Touch Button";
CM_ SG_ 591 ATS_RLStHRestUpBtn "Rear Left Power Seat Head Rest Up Touch Button";
CM_ SG_ 591 ATS_RLStHRestDnBtn "Rear Left Power Seat Head Rest Down Touch Button";
CM_ SG_ 591 ATS_RLStHRestFwdBtn "Rear Left Power Seat Head Rest Forward Touch Button";
CM_ SG_ 591 ATS_RLStHRestBwdBtn "Rear Left Power Seat Head Rest Backward Touch Button";
CM_ SG_ 591 ATS_RLStLegRestUpBtn "Rear Left Power Seat Leg Rest Up Touch Button";
CM_ SG_ 591 ATS_RStLegRestDnBtn "Rear Left Power Seat Leg Rest Down Touch Button";
CM_ SG_ 591 ATS_RLStLegRestExtUpBtn "Rear Left Power Seat Leg Rest Ext. Up Touch Button";
CM_ SG_ 591 ATS_RLStLegRestExtDnBtn "Rear Left Power Seat Leg Rest Ext. Down Touch Button";
CM_ SG_ 591 ATS_RLStShoulderADJFwdBtn "Rear Left Power Seat Shoulder Adjuster Forward Touch Button";
CM_ SG_ 591 ATS_RLStShoulderADJBwdBtn "Rear Left Power Seat Shoulder Adjuster Backward Touch Button";
CM_ BO_ 1058 "[PE] Periodic and On Event";
CM_ SG_ 1058 BCM_Crc10Val "BCM_CyclicRedundancyCheck10Value";
CM_ SG_ 1058 BCM_AlvCnt10Val "BCM_AliveCounter10Value";
CM_ SG_ 1058 Wiper_PrkngPosSta "Wiper_ParkingPositionStatus ##2G##BCM - BCMmsg22 - C_WiperParkPosition";
CM_ SG_ 1058 Wiper_RainSnsrOptionTyp "Wiper_RainSensorOptionType ##2G##BCM - BCMmsg24 - C_RainSnsOption";
CM_ SG_ 1058 Wiper_RainSnsrSta "Wiper_RainSensorStatus ##2G##BCM - BCMmsg24 - C_RainSnsState";
CM_ SG_ 1058 BCM_SolSnsrRt "BCM_SolarSensorRightOutputVoltageValue ##2G##BCM - BCMmsg24 - C_PhotosensorRH";
CM_ SG_ 1058 BCM_SolSnsrLft "BCM_SolarSensorLeftOutputVoltageValue ##2G##BCM - BCMmsg24 - C_PhotosensorLH";
CM_ SG_ 1058 BCM_GearPosPSta "BCM_GearPositionPStatus ##2G##BCM - BCMmsg17 - C_PpositiOn";
CM_ SG_ 1058 BCM_SunRoofOpnSta "BCM_SunRoofOpenStatus ##2G##BCM - BCMmsg20 - C_SunRoofOpenState";
CM_ SG_ 1058 Wiper_AutoWashModeSta "Auto Wash Mode Wiper State";
CM_ BO_ 2357404929 "[P] Periodic";
CM_ SG_ 2357404929 BMS_Crc6Val "BMS_CyclicRedundancyCheck6Value";
CM_ SG_ 2357404929 BMS_AlvCnt6Val "BMS_AliveCounter6Value";
CM_ SG_ 2357404929 CHRG_StndChrgConnSta_120V "CHRG_StandardChargeConnectStatus";
CM_ SG_ 2357404929 CHRG_StndChrgSta "CHRG_StandardChargeStatus";
CM_ SG_ 2357404929 CHRG_ChrgCycStrtSta "CHRG_ChargingCycleStartStatus";
CM_ SG_ 2357404929 CHRG_FulChrgSta "CHRG_FullyChargeStatus";
CM_ SG_ 2357404929 CHRG_ChrgSta "CHRG_ChargeStatus";
CM_ SG_ 2357404929 CHRG_SpplmntChrgSta "CHRG_SupplementaryChargeStatus";
CM_ SG_ 2357404929 CHRG_LdcInhbtReq "CHRG_LdcInhibitRequest";
CM_ SG_ 2357404929 CHRG_NorChgFnshSta "CHRG_ChargeNormalFinishConditionStatus";
CM_ SG_ 2357404929 CHRG_ChrgFnshSta "CHRG_ChargeFinishStatus";
CM_ SG_ 2357404929 CHRG_Ig3RlyOffReq "CHRG_Ig3RelayOffRequest";
CM_ SG_ 2357404929 CHRG_PShftChgSta "CHRG_PShiftChangeStatus";
CM_ SG_ 2357404929 CHRG_PilotFlSta "CHRG_PilotlineFailStatus";
CM_ SG_ 2357404929 CHRG_ObcCmdCurrVal "CHRG_ObcCommandCurrentValue";
CM_ BO_ 2357404930 "[P] Periodic";
CM_ SG_ 2357404930 CHRG_StndChrgRmnTimeVal "CHRG_StandardChargeRemainedTimeValue";
CM_ SG_ 2357404930 CHRG_ChrgRmnTimeVal "CHRG_ChargeRemainedTimeValue";
CM_ SG_ 2357404930 CHRG_ObcRlyOnSta "CHRG_ObcRelayOnStatus";
CM_ SG_ 2357404930 CHRG_NrmlOpSta "CHRG_NormalOperationStatus";
CM_ SG_ 2357404930 CHRG_ChgLamp_1EA "CHRG_ChargeLampRequest (1EA Lamp)";
CM_ SG_ 2357404930 CHRG_ObcCmdVoltVal "CHRG_ObcCommandVoltageValue";
CM_ SG_ 2357404930 CHRG_ObcMainVoltVal "CHRG_ObcMainVoltageValue";
CM_ BO_ 2357404931 "[P] Periodic";
CM_ SG_ 2357404931 CHRG_StndChrgRmnTime120Val "CHRG_StandardChargeRemainedTime120Value";
CM_ SG_ 2357404931 CHRG_StndChrgRmnTime240Val "CHRG_StandardChargeRemainedTime240Value";
CM_ SG_ 2357404931 CHRG_ObcOutCurrVal "CHRG_ObcOutputCurrentValue";
CM_ SG_ 2357404931 CHRG_DomStndChrgRmnTimeVal "CHRG_DomesticStandardChargeRemainedTime";
CM_ SG_ 2357404931 CHRG_ChrgFltSubCodVal "CHRG_ChargeFaultSubCodeValue";
CM_ BO_ 2357404932 "[P] Periodic";
CM_ SG_ 2357404932 CHRG_ScChgTrgtSocVal "CHRG_TargetStateOfScChargeValue";
CM_ SG_ 2357404932 CHRG_RealStndChrgRmnTimeVal "CHRG_RealStandardChargeRemainedTime";
CM_ SG_ 2357404932 PHEV_EstChrgRmnTimeVal "PHEV_EstimatedChargeRemainedTimeValue";
CM_ SG_ 2357404932 CHRG_ChrgLmp_3EA "CHRG_Charge Lamp(3EA Lamp)";
CM_ SG_ 2357404932 CHRG_EuroStndChrgRmnTimeVal "CHRG_EuroStandardChargeRemainedTime";
CM_ BO_ 1079 "[PE] Periodic and On Event";
CM_ SG_ 1079 CTM_TrailerAct "This signal is used for control the Trailer Act function.";
CM_ SG_ 1079 CTM_ExtTailLmpLftOpnSta "Trailer Exterior Tail Lamp Left OpenStatus";
CM_ SG_ 1079 CTM_ExtTailLmpRtOpnSta "Trailer Exterior Tail Lamp Right OpenStatus";
CM_ SG_ 1079 CTM_Exra_EbrakSta "Trailer Exterior Ebrake Out OnOffStatus";
CM_ SG_ 1079 CTM_RearfogAct "This signal is used for display the rear fog lamp mounted on the trailer.";
CM_ SG_ 1079 CTM_StpLmpOpnSta "Trailer Stop Lamp OpenStatus";
CM_ SG_ 1079 CTM_TrnSigLmpLftOpnSta "Trailer T/SIG Lamp Left OpenStatus";
CM_ SG_ 1079 CTM_TrnSigLmpRtOpnSta "Trailer T/SIG Lamp Right OpenStatus";
CM_ BO_ 2424579841 "[PE] Periodic and On Event";
CM_ SG_ 2424579841 DATC_Crc11Val "DATC_CyclicRedundancyCheck11Value";
CM_ SG_ 2424579841 DATC_AlvCnt11Val "DATC_AliveCounter11Value";
CM_ SG_ 2424579841 DATC_TnnlClimtUSMSta "DATC_TunnelCLimateUSMState";
CM_ SG_ 2424579841 DATC_ProximitySnsrSta "DATC_ProximitySensorStatus";
CM_ SG_ 2424579841 DATC_TunnelFuncOff4AutoDfgReq "DATC_TunnelFunctionOffForAutoDefogRequest";
CM_ SG_ 2424579841 DATC_RrCtlLckSta "Datc_RearClimateControlLockStatus";
CM_ SG_ 2424579841 DATC_DrvrStHtrUSMSta "DATC_DriverSeatHeaterUSMStatus";
CM_ SG_ 2424579841 DATC_InDrctVntUSMSta "DATC_InDirectVent_USM_State";
CM_ SG_ 2424579841 DATC_WshFldUSMSta "DATC_WasherFulidUSMState";
CM_ SG_ 2424579841 DATC_DfgLgcUSMSta "DefLogic USM State";
CM_ SG_ 2424579841 DATC_AutoFrshUSMSta "Auto Fresh USM State";
CM_ SG_ 2424579841 DATC_HptIntnstySta "Haptic Intensity State";
CM_ SG_ 2424579841 DATC_ClmtPwrSum_W "accumulated energy consumption while driving(200ms)";
CM_ BO_ 1085 "[PE] Periodic and On Event";
CM_ SG_ 1085 DLBCU_ActiveDis "DLBCU_ActiveModeDisplay";
CM_ SG_ 1085 DLBCU_CushSoftSta "DLBCU_CushionSoftnessStatus";
CM_ SG_ 1085 DLBCU_CellOpt "DLBCU_CellOption Status";
CM_ SG_ 1085 DLBCU_BodySpprtSta "Seat Body Support Function USM R Value";
CM_ SG_ 1085 DLBCU_BodySpprtDis "Seat body Support Function Display Request";
CM_ SG_ 1085 DLBCU_SmartCtrl_Set_Rvalue "ÁÖÇà Áß Çã¸® º¸È£ ±â´É USM µ¿ÀÛ ¼³Á¤ °ª (R Value)";
CM_ SG_ 1085 DLBCU_DrvModUSMSta "DLBCU_DriveModeStatus";
CM_ SG_ 1085 DLBCU_ActiveStrSta "DLBCU_ActiveStrengthStatus";
CM_ SG_ 1085 DLBCU_ActiveTimeSta "DLBCU_ActiveTimeStatus";
CM_ BO_ 2164278529 "[P] Periodic";
CM_ SG_ 2164278529 HTCU_Crc4Val "HTCU_CyclicRedundancyCheck4Value";
CM_ SG_ 2164278529 HTCU_AlvCnt4Val "HTCU_AliveCounter4Value";
CM_ SG_ 2164278529 HTCU_TrgtGearSta "HTCU_TargetGearStatus";
CM_ SG_ 2164278529 HTCU_RdySta "HTCU_ReadyStatus";
CM_ SG_ 2164278529 HTCU_GearChgSta "HTCU_GearChangeStatus";
CM_ SG_ 2164278529 HTCU_TqRdctnPcVal "HTCU_TorqueReductionPcValue";
CM_ SG_ 2164278529 HTCU_FltSta "HTCU_FaultStatus";
CM_ SG_ 2164278529 HTCU_GearSlctrDis "HTCU_GearSelectDisplay";
CM_ SG_ 2164278529 HTCU_SlwTqRdctnPcVal "HTCU_SlowTorqueReductionPcValue";
CM_ SG_ 2164278529 HTCU_FanCtrlReq "Fan control request by OPU";
CM_ BO_ 2164278530 "[P] Periodic";
CM_ SG_ 2164278530 HTCU_VehSpdKphVal "HTCU_VehicleSpeedKphValue";
CM_ SG_ 2164278530 HTCU_HvOpuSpdCmdRpmVal "HTCU_HvOpuSpeedCommandRpmValue";
CM_ SG_ 2164278530 HTCU_TrgtShftClsCCanSta "HTCU_TargetShiftClassCCanStatus";
CM_ SG_ 2164278530 HTCU_PrgrmSta "HTCU_ProgramStatus";
CM_ SG_ 2164278530 HTCU_FsCltchLmphmActvSta "HTCU_FsClutchLimphomeActivationStatus";
CM_ SG_ 2164278530 HTCU_FsIdleTrgtRpmVal "HTCU_FsIdleTargetRpmValue";
CM_ SG_ 2164278530 HTCU_FsAddtnlTqLssPcVal "HTCU_FsAdditionalTorqueLossPcValue";
CM_ SG_ 2164278530 HTCU_VehSpdDcmlKphVal "HTCU_VehicleSpeedDecimalKphValue";
CM_ BO_ 2164278531 "[P] Periodic";
CM_ SG_ 2164278531 HTCU_FsEngTqRdctnPcVal "HTCU_FsEngineTorqueReductionPcValue";
CM_ SG_ 2164278531 HTCU_RapidKDReq "HTCU_RapidKDRequest";
CM_ SG_ 2164278531 HTCU_CurrGearSta "HTCU_CurrentGearStatus";
CM_ SG_ 2164278531 HTCU_GearShftUpDisGSI "HTCU_GearShiftUpDisplayGSI";
CM_ SG_ 2164278531 HTCU_GearShftDnDisGSI "HTCU_GearShiftDownDisplayGSI";
CM_ SG_ 2164278531 HTCU_TrgtGearStaGSI "HTCU_TargetGearStatusGSI";
CM_ SG_ 2164278531 HTCU_SolBSta "HTCU_SolenoidBStatus";
CM_ SG_ 2164278531 HTCU_LnPrsBarVal "HTCU_LinePressureBarValue";
CM_ BO_ 2281833730 "[P] Periodic";
CM_ SG_ 2281833730 DMIC_EcsModSta "DMIC_EcsModeStatus ##2G##ICSC - IVSS11 - MODE_ECS";
CM_ SG_ 2281833730 DMIC_IndAwdModSta "DMIC_IndividualAwdModeStatus ##2G##ICSC - IVSS11 - MODE_4WD_IND";
CM_ SG_ 2281833730 DMIC_RevModSta "DMIC_RevModeStatus ##2G##ICSC - IVSS11 - MODE_REV";
CM_ SG_ 2281833730 DMIC_IndRevModSta "DMIC_IndividualRevModeStatus ##2G##ICSC - IVSS11 - MODE_REV_IND";
CM_ SG_ 2281833730 DMIC_PrflModSta "DMIC_PrflModeStatus ##2G##ICSC - IVSS11 - MODE_PRFL";
CM_ SG_ 2281833730 DMIC_IndPrflModSta "DMIC_IndividualPrflModeStatus ##2G##ICSC - IVSS11 - MODE_PRFL_IND";
CM_ SG_ 2281833730 DMIC_ElsdModSta "DMIC_ElsdModeStatus ##2G##ICSC - IVSS11 - MODE_ELSD";
CM_ SG_ 2281833730 DMIC_IndElsdModSta "DMIC_IndividualElsdModeStatus ##2G##ICSC - IVSS11 - MODE_ELSD_IND";
CM_ SG_ 2281833730 DMIC_IndEcsModSta "DMIC_IndividualEcsModeStatus ##2G##ICSC - IVSS11 - MODE_ECS_IND";
CM_ SG_ 2281833730 DMIC_EsndModSta "DMIC_EsndModeStatus ##2G##ICSC - IVSS11 - MODE_ESND";
CM_ SG_ 2281833730 DMIC_IndEsndModSta "DMIC_IndividualEsndModeStatus ##2G##ICSC - IVSS11 - MODE_ESND_IND";
CM_ SG_ 2281833730 DMIC_RwsModSta "DMIC_RwsModeStatus";
CM_ SG_ 2281833730 DMIC_IndRwsModSta "DMIC_IndividualRwsModeStatus";
CM_ SG_ 2281833730 DMIC_AwdModSta "DMIC_AwdModeStatus ##2G##ICSC - IVSS11 - MODE_4WD";
CM_ BO_ 579 "[PE] Periodic and On Event";
CM_ SG_ 579 OHCL_Opt "OHCL option state";
CM_ SG_ 579 OHCL_Sys_sta "OHCL Status";
CM_ SG_ 579 OHCL_DoorOn_Sta "Door lamp switch On/Off status";
CM_ SG_ 579 OHCL_RrMapLftOn_Sta "Rear left map lamp On/Off status";
CM_ SG_ 579 OHCL_RrMapRtOn_Sta "Rear right map lamp On/Off status";
CM_ SG_ 579 OHCL_RrRoomOn_Sta "Rear room lamp On/Off status";
CM_ SG_ 579 OHCL_RrMoodOn_Sta "Rear mood lamp On/Off status";
CM_ SG_ 579 OHCL_LEDClr_Sta "Interior lamps lighting color status";
CM_ SG_ 579 OHCL_LEDBgtns_Sta "Interior lamps brightness status";
CM_ SG_ 579 OHCL_TllTlLmpSta "PAB tell tale lamp status";
CM_ SG_ 579 OHCL_FrMapLftOn_Sta "Front left map lamp On/Off status";
CM_ SG_ 579 OHCL_RrCurtainReq "Rear Curtain Switch On/Off Signal";
CM_ SG_ 579 OHCL_FrMapRtOn_Sta "Front right map lamp On/Off status";
CM_ SG_ 579 OHCL_FrRoomOn_Sta "Front room lamp On/Off status";
CM_ SG_ 579 OHCL_FrMoodOn_Sta "Front mood lamp On/Off status";
CM_ BO_ 1059 "[PE] Periodic and On Event";
CM_ SG_ 1059 PSU_DiagSta "PSU_DiagnosticStatus";
CM_ SG_ 1059 PSU_EsyAcsGetOnSta "PSU_EasyAccessGetOnStatus";
CM_ SG_ 1059 PSU_EsyAcsGetOffSta "PSU_EasyAccessGetOffStatus";
CM_ SG_ 1059 PSU_EsyAcsStpSta "PSU_EasyAccessStopStatus";
CM_ SG_ 1059 PSU_RVal "PSU_RValue";
CM_ BO_ 1086 "[PE] Periodic and On Event";
CM_ SG_ 1086 RL_CURTAIN_POSITION "Rear Left Curtain Status Position Output";
CM_ SG_ 1086 RDC_SWVerMinor1 "Second Word(ASCII) in RDC S/W Ver";
CM_ SG_ 1086 RDC_SWVerMinor2 "Third Word(ASCII) in RDC S/W Ver";
CM_ SG_ 1086 RR_CURTAIN_POSITION "Rear Right Curtain Status Position Output";
CM_ SG_ 1086 RDC_RLDNInitFlag "Rear Left Door Curtain Down Initialized Finish Flag";
CM_ SG_ 1086 RDC_RRDNInitFlag "Rear Right Door Curtain Down Initialized Finish Flag";
CM_ SG_ 1086 RDC_RLOpState "Rear Left Door Curtain Operating State Feedback";
CM_ SG_ 1086 RDC_RROpState "Rear Right Door Curtain Operating State Feedback";
CM_ SG_ 1086 RDC_OptTyp "OPTION FLAG for RDC";
CM_ SG_ 1086 RDC_SWVerMajor1 "First Word(ASCII) in RDC S/W Ver";
CM_ BO_ 1068 "[PE] Periodic and On Event";
CM_ SG_ 1068 RLPSU_ReclMtrPos "RLPSU Recline Motor Position";
CM_ SG_ 1068 RLPSU_RLSlidPos "2nd Left Seat Slide Position Information for button activatation / unactivation";
CM_ SG_ 1068 RLPSU_RLRclPos "2nd Left Seat Back Reclining Position Information for button activatation / unactivation";
CM_ SG_ 1068 RLPSU_RLTiltPos "2nd Left Seat Cushion Tilt Position Information for button activatation / unactivation";
CM_ SG_ 1068 RLPSU_RLLegExtPos "2nd Left Seat Legsupport Extension Position Information for button activatation / unactivation";
CM_ SG_ 1068 RLPSU_RLLegSupPos "2nd Left Seat Legrest Support Position Information for button activatation / unactivation";
CM_ SG_ 1068 RLPSU_RLHrestSlidPos "2nd Left Seat Head Rest Slide Position Information for button activatation / unactivation";
CM_ SG_ 1068 RLPSU_RLHrestHeightPos "2nd Left Seat HeadRest Height Position Information for button activatation / unactivation";
CM_ SG_ 1068 RLPSU_Opt "PWR_HVU Option";
CM_ SG_ 1068 RLPSU_Opt_Captain "PWR_HVU Option_Captain";
CM_ SG_ 1068 RLHVU_Opt_Captain "MNL_HVU Option_Captain";
CM_ SG_ 1068 RLPSU_PwrSeatOpt "Option Info for 2nd Left Recline Seat";
CM_ SG_ 1068 RLPSU_PwrSeatPos "2nd Left Seat Back Position for button activatation / unactivation";
CM_ BO_ 1080 "[PE] Periodic and On Event";
CM_ SG_ 1080 RL_SHVU_SeatOptSta "Rear LH Seat Heater/Vent option info";
CM_ SG_ 1080 RL_SHVU_SeatHtOperSta "Rear LH Seat Heater/Vent current operation state";
CM_ SG_ 1080 RL_SHVU_HtSwHiIndSta_RHD "Rear Left_Seat Heater Switch High Indicator Status";
CM_ SG_ 1080 RL_SHVU_HtSwMidIndSta_RHD "Rear Left_Seat Heater Switch Mid Indicator Status";
CM_ SG_ 1080 RL_SHVU_HtSwLowIndSta_RHD "Rear Left_Seat Heater Switch Low Indicator Status";
CM_ SG_ 1080 RL_SHVU_VntSwHiIndSta_RHD "Rear Left Seat Vent Switch High Indicator Status";
CM_ SG_ 1080 RL_SHVU_VntSwMidIndSta_RHD "Rear Left Seat Vent Switch Mid Indicator Status";
CM_ SG_ 1080 RL_SHVU_VntSwLowIndSta_RHD "Rear Left Seat Vent Switch Low Indicator Status";
CM_ SG_ 1080 RL_SHVU_HtBlcUsmSta_RHD "RL Seat Heater Balance Status(RHD)";
CM_ BO_ 1070 "[PE] Periodic and On Event";
CM_ SG_ 1070 RL_SHVU_HtSwHiIndSta "Rear Left_Seat Heater Switch High Indicator Status";
CM_ SG_ 1070 RL_SHVU_HtSwMidIndSta "Rear Left_Seat Heater Switch Mid Indicator Status";
CM_ SG_ 1070 RL_SHVU_HtSwLowIndSta "Rear Left_Seat Heater Switch Low Indicator Status";
CM_ SG_ 1070 RL_SHVU_VntSwHiIndSta "Rear Left Seat Vent Switch High Indicator Status";
CM_ SG_ 1070 RL_SHVU_VntSwMidIndSta "Rear Left Seat Vent Switch Mid Indicator Status";
CM_ SG_ 1070 RL_SHVU_VntSwLowIndSta "Rear Left Seat Vent Switch Low Indicator Status";
CM_ SG_ 1070 RL_SHVU_HtBlcUsmSta "RL Seat Heater Balance Status";
CM_ BO_ 1069 "[PE] Periodic and On Event";
CM_ SG_ 1069 RRPSU_ReclMtrPos "RRPSU Recline Motor Position";
CM_ SG_ 1069 RRPSU_PwrSeatOpt "Option Info for 2nd Right Recline Seat";
CM_ SG_ 1069 RRPSU_PwrSeatPos "2nd Right Seat Back Position for button activatation / unactivation";
CM_ SG_ 1069 RRPSU_RRSlidPos "2nd Right Seat Slide Position Information For Button Activation / Deactivation";
CM_ SG_ 1069 RRPSU_RRRclPos "2nd Right Seat Recline Position Information For Button Activation / Deactivation";
CM_ SG_ 1069 RRPSU_RRTiltPos "2nd Right Seat Cushion Tilt Position Information For Button Activation / Deactivation";
CM_ SG_ 1069 RRPSU_RRLegExtPos "2nd Right Seat Legextension (Front / Rear) Position Information For Button Activation / Deactivation";
CM_ SG_ 1069 RRPSU_RRLegSupPos "2nd Right Seat Leg Extension (Upper/Lower) Position Information For Button Activation / Deactivation";
CM_ SG_ 1069 RRPSU_RRStEsyAcsUSMSta "Rear RH Seat EasyAccess USM";
CM_ SG_ 1069 RRPSU_RRHrestSlidPos "2nd Right Seat HeadRest Slide Position Information For Button Activation / Deactivation";
CM_ SG_ 1069 RRPSU_RRHrestHeightPos "2nd Right Seat Headrest Height Position Information For Button Activation / Deactivation";
CM_ SG_ 1069 RRPSU_Opt_Captain "PWR_HVU Option_Captain";
CM_ SG_ 1069 RRHVU_Opt_Captain "MNL_HVU Option_Captain";
CM_ SG_ 1069 RRPSU_RLStEsyAcsUSMSta "Rear LH Seat EasyAccess USM Setting";
CM_ SG_ 1069 RRPSU_Opt "PWR_HVU Option";
CM_ BO_ 1071 "[PE] Periodic and On Event";
CM_ SG_ 1071 RR_SHVU_HtSwHiIndSta "Rear Right_Seat Heater Switch High Indicator Status";
CM_ SG_ 1071 RR_SHVU_HtSwMidIndSta "Rear Left_Seat Heater Switch Mid Indicator Status";
CM_ SG_ 1071 RR_SHVU_HtSwLowIndSta "Rear Right_Seat Heater Switch Low Indicator Status";
CM_ SG_ 1071 RR_SHVU_VntSwHiIndSta "Rear Right Seat Vent Switch High Indicator Status";
CM_ SG_ 1071 RR_SHVU_VntSwMidIndSta "Rear Right Seat Vent Switch Mid Indicator Status";
CM_ SG_ 1071 RR_SHVU_VntSwLowIndSta "Rear Right Seat Vent Switch Low Indicator Status";
CM_ SG_ 1071 RR_SHVU_HtBlcUsmSta "RR Seat Heater Balance Status";
CM_ BO_ 1073 "[PE] Periodic and On Event";
CM_ SG_ 1073 USM_ValCmdSta "USM_ValueCommandStatus";
CM_ SG_ 1073 RWPC_SWVerMinor1 "Second Word(ASCII) in RWPC S/W Ver";
CM_ SG_ 1073 WPC_PhnLftWrngRWPCSta "WPC_PhoneLeftWaringRWPCStatus";
CM_ SG_ 1073 RWPC_SWVerMinor2 "Third Word(ASCII) in RWPC S/W Ver";
CM_ SG_ 1073 USM_ValCmdStaforATS "USM_ValueCommandStatus";
CM_ SG_ 1073 RWPC_SWVerMajor1 "First Word(ASCII) in RWPC S/W Ver";
CM_ BO_ 1567 "[TP] Transport Protocol";
CM_ BO_ 1566 "[TP] Transport Protocol";
CM_ BO_ 2160080129 "[P] Periodic";
CM_ SG_ 2160080129 VCU_Crc1Val "VCU_CyclicRedundancyCheck1Value";
CM_ SG_ 2160080129 VCU_AlvCnt1Val "VCU_AliveCounter1Value";
CM_ SG_ 2160080129 VCU_RdySta "VCU_ReadyStatus ##2G##VCU - VCU1 - CF_Vcu_Rdy";
CM_ SG_ 2160080129 VCU_StartKeyHoldSta "VCU_StartKeyHoldStatus ##2G##VCU - VCU1 - CF_Vcu_Key_ST";
CM_ SG_ 2160080129 VCU_EvDrvRdySta "VCU_EvDriveReadyStatus ##2G##VCU - VCU1 - CF_Vcu_EvRdy";
CM_ SG_ 2160080129 VCU_MotPwrEnReq "VCU_MotorPowerEnableRequest ##2G##VCU - VCU3 - CF_Vcu_MotPwrEna";
CM_ SG_ 2160080129 VCU_GearPosSta "VCU_GearPositionStatus ##2G##VCU - VCU1 - CF_Vcu_GarSelDisp";
CM_ SG_ 2160080129 VCU_LdcInhReq "VCU_LdcInhibitRequest ##2G##VCU - VCU5 - CF_Vcu_LdcInh";
CM_ SG_ 2160080129 VCU_MainRlyOffReq "VCU_MainRelayCutOffRequest ##2G##VCU - VCU1 - CF_Vcu_RelayOffReq";
CM_ SG_ 2160080129 VCU_AccPedDepVal "VCU_AcceleratorPedalDepthValue ##2G##VCU - VCU1 - CR_Vcu_AccPedDep_Pc";
CM_ SG_ 2160080129 VCU_FatcOperPermSta "VCU_FatcOperatingPermissionStatus ##2G##VCU - VCU20 - CF_Vcu_ClimateOperPerm";
CM_ SG_ 2160080129 VCU_DrvCycSta "VCU_DrivingCycleStatus ##2G##VCU - VCU1 - CF_Vcu_Veh_DC";
CM_ SG_ 2160080129 VCU_CltActOpSta "VCU_ClutchActuatorOperatingStatus";
CM_ SG_ 2160080129 VCU_WhlSpdSnsrAlvReq "VCU_WheelSpeedSensorAliveRequest";
CM_ SG_ 2160080129 VCU_DrvModOpSta "VCU's operating drive mode according to CLU and DMIC signals";
CM_ SG_ 2160080129 VCU_IgOffGearPosStaDispReq "VCU_IgOffGearPositionStatusDispayRequest";
CM_ BO_ 2160080131 "[P] Periodic";
CM_ SG_ 2160080131 VCU_EcmSeqSta "VCU_EcmSequenceStatus ##2G##VCU - VCU1 - CF_Vcu_IGONStatus";
CM_ SG_ 2160080131 VCU_CltActDiagSta "VCU_ClutchActuatorDiagnosisStatus";
CM_ SG_ 2160080131 VCU_CltActDrvCrntVal "VCU_ClutchActuatorDriveCurrentValue";
CM_ SG_ 2160080131 VCU_CltActPosStrokeVal "VCU_ClutchActuatorPositionStrokeValue";
CM_ SG_ 2160080131 VCU_MainBattTypeSta "VCU_MainBatteryTypeStatus ##2G##VCU - VCU18 - CF_Vcu_MainBattType";
CM_ SG_ 2160080131 VCU_MainBattTypeLrnSta "VCU_MainBatteryTypeLearnStatus ##2G##VCU - VCU18 - CF_Vcu_MainBattTypeLrnSts";
CM_ SG_ 2160080131 VCU_WarmupCycSta "VCU_WarmupCycleStatus ##2G##VCU - VCU1 - CF_Vcu_WarmupCyc";
CM_ SG_ 2160080131 VCU_FatcPermPwrVal "VCU_FatcPermissionPowerValue ##2G##VCU - VCU5 - CR_Vcu_ClimatePerm_W";
CM_ SG_ 2160080131 VCU_EcmDiagSta "VCU_EcmDiagnosisStatus";
CM_ BO_ 2160080132 "[P] Periodic";
CM_ SG_ 2160080132 VCU_GearPosStaDisp "VCU_GearPositionStatusDisp";
CM_ SG_ 2160080132 VCU_PdwLmtOperSta "Status of PDW Torque Limit";
CM_ SG_ 2160080132 VCU_PdwLmtBrkRequest "Request brake torque for PDW Torque Limit";
CM_ SG_ 2160080132 VCU_VgsVirSoundBackFireIndex "Virtual sound back fire noise index for VGS mode";
CM_ SG_ 2160080132 VCU_VgsVirEngSpdRpmVal "Virtual engine speed for VGS mode";
CM_ SG_ 2160080132 VCU_PdlStopCtrlSta "Cooperative control state of VCU for stop assist control with IEB";
CM_ SG_ 2160080132 VCU_VgsVirSoundVolume "Virtual engine sound volume for VGS mode[%]";
CM_ SG_ 2160080132 VCU_VgsVirGearStep "Shift gear when entering VGS mode";
CM_ SG_ 2160080132 VCU_PdlStopReqTqNmVal "Requested brake torque for cooperative stop assist control";
BA_DEF_ BO_ "DiagState" ENUM "No","Yes" ;
BA_DEF_ BO_ "DiagResponse" ENUM "No","Yes" ;
BA_DEF_ BO_ "DiagRequest" ENUM "No","Yes" ;
BA_DEF_ BO_ "TpMessage" ENUM "No","Yes" ;
BA_DEF_ BO_ "UsrMsgIDSforwardDeviation" INT 0 100 ;
BA_DEF_ BO_ "UsrMsgIDSbackwardDeviation" INT 50 1000 ;
BA_DEF_ BO_ "GenMsgCycleTime" INT 0 2000 ;
BA_DEF_ BO_ "GenMsgStartDelayTime" INT 0 2000 ;
BA_DEF_ BO_ "GenMsgSendType" ENUM "Cyclic","NoMsgSendType" ;
BA_DEF_ BO_ "GenMsgCycleTimeFast" INT 0 500 ;
BA_DEF_ BO_ "GenMsgDelayTime" INT 0 20 ;
BA_DEF_ BO_ "GenMsgILSupport" ENUM "No","Yes" ;
BA_DEF_ BO_ "GenMsgNrOfRepetition" INT 0 3 ;
BA_DEF_ BO_ "NmMessage" ENUM "No","Yes" ;
BA_DEF_ BO_ "NWM-Botschaft" ENUM "No","Yes" ;
BA_DEF_ BO_ "TpTxIndex" INT 0 255 ;
BA_DEF_ BO_ "VFrameFormat" ENUM "StandardCAN","ExtendedCAN","reserved","reserved","reserved","reserved","reserved","reserved","reserved","reserved","reserved","reserved","reserved","reserved","StandardCAN_FD","ExtendedCAN_FD" ;
BA_DEF_ SG_ "UserSigValidity" ENUM "B+","ACC","IG","IG1","IG2","IG3","IG1 or IG2","IG1 or IG3","Undef" ;
BA_DEF_ SG_ "TimeoutValue" STRING ;
BA_DEF_ SG_ "UsrSigPurpose" ENUM "Undef","FN","DIAG","DIAG(Req)","DIAG(Res)","DIAG(Phy)","DEV","CCP(Req)","CCP(Res)","NM","TP" ;
BA_DEF_ SG_ "GenSigStartValue" INT 0 1215752192 ;
BA_DEF_ SG_ "NetworkRequest" ENUM "Yes","No" ;
BA_DEF_ SG_ "NetworkRequestHoldingTime" INT 0 65535 ;
BA_DEF_ SG_ "Description" STRING ;
BA_DEF_ SG_ "Version" STRING ;
BA_DEF_ SG_ "GenSigEnvVarType" ENUM "Int","Float","Undef" ;
BA_DEF_ SG_ "GenSigSendType" ENUM "Cyclic","OnWrite","OnWriteWithRepetition","OnChange","OnChangeWithRepetition","IfActive","IfActiveWithRepetition","NoSigSendType","OnChangeAndIfActive","OnChangeAndIfActiveWithRepetition" ;
BA_DEF_ SG_ "GwSigLatencyTime" INT 0 65536 ;
BA_DEF_ SG_ "GwSigMissingSourceType" ENUM "Undef","OldValue","DefaultValue","InitialValue" ;
BA_DEF_ SG_ "NWM-WakeupAllowed" ENUM "<n.a.>" ;
BA_DEF_ SG_ "RoutingFactor" INT 1 1215752192 ;
BA_DEF_REL_ BU_SG_REL_ "GenSigTimeoutTime" INT 0 7000 ;
BA_DEF_DEF_ "DiagState" "No" ;
BA_DEF_DEF_ "DiagResponse" "No" ;
BA_DEF_DEF_ "DiagRequest" "No" ;
BA_DEF_DEF_ "TpMessage" "No" ;
BA_DEF_DEF_ "UsrMsgIDSforwardDeviation" 10 ;
BA_DEF_DEF_ "UsrMsgIDSbackwardDeviation" 100 ;
BA_DEF_DEF_ "GenMsgCycleTime" 200 ;
BA_DEF_DEF_ "GenMsgStartDelayTime" 0 ;
BA_DEF_DEF_ "GenMsgSendType" "NoMsgSendType" ;
BA_DEF_DEF_ "GenMsgCycleTimeFast" 40 ;
BA_DEF_DEF_ "GenMsgDelayTime" 20 ;
BA_DEF_DEF_ "GenMsgILSupport" "Yes" ;
BA_DEF_DEF_ "GenMsgNrOfRepetition" 3 ;
BA_DEF_DEF_ "NmMessage" "No" ;
BA_DEF_DEF_ "NWM-Botschaft" "No" ;
BA_DEF_DEF_ "TpTxIndex" 0 ;
BA_DEF_DEF_ "VFrameFormat" "StandardCAN" ;
BA_DEF_DEF_ "UserSigValidity" "IG" ;
BA_DEF_DEF_ "TimeoutValue" "" ;
BA_DEF_DEF_ "UsrSigPurpose" "FN" ;
BA_DEF_DEF_ "GenSigStartValue" 0 ;
BA_DEF_DEF_ "NetworkRequest" "No" ;
BA_DEF_DEF_ "NetworkRequestHoldingTime" 0 ;
BA_DEF_DEF_ "Description" "" ;
BA_DEF_DEF_ "Version" "" ;
BA_DEF_DEF_ "GenSigEnvVarType" "Undef" ;
BA_DEF_DEF_ "GenSigSendType" "NoSigSendType" ;
BA_DEF_DEF_ "GwSigLatencyTime" 40 ;
BA_DEF_DEF_ "GwSigMissingSourceType" "Undef" ;
BA_DEF_DEF_ "NWM-WakeupAllowed" "<n.a.>" ;
BA_DEF_DEF_ "RoutingFactor" 1 ;
BA_DEF_DEF_REL_ "GenSigTimeoutTime" 500 ;
BA_ "GenMsgSendType" BO_ 1546 0;
BA_ "GenMsgCycleTimeFast" BO_ 1546 0;
BA_ "GenMsgNrOfRepetition" BO_ 1546 0;
BA_ "Description" SG_ 1546 AMP_SupportBeepVolumeControl "18.02.01_";
BA_ "GenSigStartValue" SG_ 1546 AMP_SupportBeepVolumeControl 3;
BA_ "UserSigValidity" SG_ 1546 AMP_SupportBeepVolumeControl 1;
BA_REL_ "GenSigTimeoutTime" BU_SG_REL_ ATS SG_ 1546 AMP_SupportBeepVolumeControl 1500;
BA_ "Version" SG_ 1546 AMP_SupportBeepVolumeControl "18.12.06";
BA_ "Description" SG_ 1546 AMP_SupportESEVMode "Dose amp support CenterPoint mode?";
BA_ "GenSigStartValue" SG_ 1546 AMP_SupportESEVMode 3;
BA_ "UserSigValidity" SG_ 1546 AMP_SupportESEVMode 1;
BA_ "NetworkRequest" SG_ 1546 AMP_SupportESEVMode 0;
BA_ "Version" SG_ 1546 AMP_SupportESEVMode "20.03.06";
BA_ "Description" SG_ 1546 AMP_SupportDSC "18.04.00_Does amp support Dynamic Speed Compensation mode?";
BA_ "GenSigStartValue" SG_ 1546 AMP_SupportDSC 3;
BA_ "UserSigValidity" SG_ 1546 AMP_SupportDSC 1;
BA_ "Version" SG_ 1546 AMP_SupportDSC "18.12.06";
BA_ "Description" SG_ 1546 AMP_SupportANCMode "18.03.08_";
BA_ "GenSigStartValue" SG_ 1546 AMP_SupportANCMode 3;
BA_ "UserSigValidity" SG_ 1546 AMP_SupportANCMode 1;
BA_ "Version" SG_ 1546 AMP_SupportANCMode "18.12.06";
BA_ "GenSigStartValue" SG_ 1546 AMP_MakerID 255;
BA_ "UserSigValidity" SG_ 1546 AMP_MakerID 1;
BA_ "Version" SG_ 1546 AMP_MakerID "19.12.00";
BA_ "Description" SG_ 1546 AMP_SupportQLS "16.03.03_";
BA_ "GenSigStartValue" SG_ 1546 AMP_SupportQLS 3;
BA_ "UserSigValidity" SG_ 1546 AMP_SupportQLS 1;
BA_ "Version" SG_ 1546 AMP_SupportQLS "18.12.06";
BA_ "Description" SG_ 1546 AMP_SupportQLS_2step "Information for 2 Step QLS mode (Harman AMP only)";
BA_ "GenSigStartValue" SG_ 1546 AMP_SupportQLS_2step 3;
BA_ "UserSigValidity" SG_ 1546 AMP_SupportQLS_2step 1;
BA_ "Version" SG_ 1546 AMP_SupportQLS_2step "21.09.10";
BA_ "GenSigStartValue" SG_ 1546 AMP_SupportHorizon 3;
BA_ "UserSigValidity" SG_ 1546 AMP_SupportHorizon 1;
BA_ "NetworkRequest" SG_ 1546 AMP_SupportHorizon 0;
BA_ "Version" SG_ 1546 AMP_SupportHorizon "20.05.00";
BA_ "Description" SG_ 1546 AMP_SupportASDMode "16.03.03_";
BA_ "GenSigStartValue" SG_ 1546 AMP_SupportASDMode 3;
BA_ "UserSigValidity" SG_ 1546 AMP_SupportASDMode 1;
BA_ "Version" SG_ 1546 AMP_SupportASDMode "18.12.06";
BA_ "GenSigStartValue" SG_ 1546 AMP_SupportIntelliQ 3;
BA_ "UserSigValidity" SG_ 1546 AMP_SupportIntelliQ 1;
BA_ "NetworkRequest" SG_ 1546 AMP_SupportIntelliQ 0;
BA_ "Version" SG_ 1546 AMP_SupportIntelliQ "20.05.00";
BA_ "Description" SG_ 1546 AMP_SupportCenterpoint "18.04.00_Does amp support CenterPoint mode?";
BA_ "GenSigStartValue" SG_ 1546 AMP_SupportCenterpoint 3;
BA_ "UserSigValidity" SG_ 1546 AMP_SupportCenterpoint 1;
BA_ "Version" SG_ 1546 AMP_SupportCenterpoint "18.12.06";
BA_ "Description" SG_ 1546 AMP_SupportSignalDoctor "16.03.03_";
BA_ "GenSigStartValue" SG_ 1546 AMP_SupportSignalDoctor 3;
BA_ "UserSigValidity" SG_ 1546 AMP_SupportSignalDoctor 1;
BA_ "Version" SG_ 1546 AMP_SupportSignalDoctor "18.12.06";
BA_ "Description" SG_ 1546 AMP_SupportLiveDynamicMode "16.03.04_";
BA_ "GenSigStartValue" SG_ 1546 AMP_SupportLiveDynamicMode 7;
BA_ "UserSigValidity" SG_ 1546 AMP_SupportLiveDynamicMode 1;
BA_ "Version" SG_ 1546 AMP_SupportLiveDynamicMode "18.12.06";
BA_ "Description" SG_ 1546 AMP_Support_ElecSound "16.07.03_";
BA_ "GenSigStartValue" SG_ 1546 AMP_Support_ElecSound 3;
BA_ "UserSigValidity" SG_ 1546 AMP_Support_ElecSound 1;
BA_ "NetworkRequest" SG_ 1546 AMP_Support_ElecSound 0;
BA_ "Version" SG_ 1546 AMP_Support_ElecSound "18.12.06";
BA_ "GenMsgSendType" BO_ 591 0;
BA_ "Description" SG_ 591 ATS_RLStSldFwdBtn "ÈÄ¼® LH ½½¶óÀÌµù Àü¹æ ÀÌµ¿";
BA_ "GenSigSendType" SG_ 591 ATS_RLStSldFwdBtn 4;
BA_ "UserSigValidity" SG_ 591 ATS_RLStSldFwdBtn 3;
BA_ "NetworkRequest" SG_ 591 ATS_RLStSldFwdBtn 0;
BA_ "NetworkRequestHoldingTime" SG_ 591 ATS_RLStSldFwdBtn 5000;
BA_ "Version" SG_ 591 ATS_RLStSldFwdBtn "19.09.02";
BA_ "Description" SG_ 591 ATS_RLStSldBwdBtn "ÈÄ¼® LH ½½¶óÀÌµù ÈÄ¹æ ÀÌµ¿";
BA_ "GenSigSendType" SG_ 591 ATS_RLStSldBwdBtn 4;
BA_ "UserSigValidity" SG_ 591 ATS_RLStSldBwdBtn 3;
BA_ "NetworkRequest" SG_ 591 ATS_RLStSldBwdBtn 0;
BA_ "NetworkRequestHoldingTime" SG_ 591 ATS_RLStSldBwdBtn 5000;
BA_ "Version" SG_ 591 ATS_RLStSldBwdBtn "19.09.02";
BA_ "Description" SG_ 591 ATS_RLStRclFwdBtn "ÈÄ¼® LH ¸®Å¬¶óÀÌ´× Àü¹æ ÀÌµ¿";
BA_ "GenSigSendType" SG_ 591 ATS_RLStRclFwdBtn 4;
BA_ "UserSigValidity" SG_ 591 ATS_RLStRclFwdBtn 3;
BA_ "NetworkRequest" SG_ 591 ATS_RLStRclFwdBtn 0;
BA_ "NetworkRequestHoldingTime" SG_ 591 ATS_RLStRclFwdBtn 5000;
BA_ "Version" SG_ 591 ATS_RLStRclFwdBtn "19.09.02";
BA_ "Description" SG_ 591 ATS_RLStRclBwdBtn "ÈÄ¼® LH ¸®Å¬¶óÀÌ´× ÈÄ¹æ ÀÌµ¿";
BA_ "GenSigSendType" SG_ 591 ATS_RLStRclBwdBtn 4;
BA_ "UserSigValidity" SG_ 591 ATS_RLStRclBwdBtn 3;
BA_ "NetworkRequest" SG_ 591 ATS_RLStRclBwdBtn 0;
BA_ "NetworkRequestHoldingTime" SG_ 591 ATS_RLStRclBwdBtn 5000;
BA_ "Version" SG_ 591 ATS_RLStRclBwdBtn "19.09.02";
BA_ "Description" SG_ 591 ATS_RLStTltUpBtn "ÈÄ¼® LH Æ¿Æ® ¾÷ ÀÌµ¿";
BA_ "GenSigSendType" SG_ 591 ATS_RLStTltUpBtn 4;
BA_ "UserSigValidity" SG_ 591 ATS_RLStTltUpBtn 3;
BA_ "NetworkRequest" SG_ 591 ATS_RLStTltUpBtn 0;
BA_ "NetworkRequestHoldingTime" SG_ 591 ATS_RLStTltUpBtn 5000;
BA_ "Version" SG_ 591 ATS_RLStTltUpBtn "19.09.02";
BA_ "Description" SG_ 591 ATS_RLStTltDnBtn "ÈÄ¼® LH Æ¿Æ® ´Ù¿î ÀÌµ¿";
BA_ "GenSigSendType" SG_ 591 ATS_RLStTltDnBtn 4;
BA_ "UserSigValidity" SG_ 591 ATS_RLStTltDnBtn 3;
BA_ "NetworkRequest" SG_ 591 ATS_RLStTltDnBtn 0;
BA_ "NetworkRequestHoldingTime" SG_ 591 ATS_RLStTltDnBtn 5000;
BA_ "Version" SG_ 591 ATS_RLStTltDnBtn "19.09.02";
BA_ "Description" SG_ 591 ATS_RLStHRestUpBtn "ÈÄ¼® LH Çìµå·¹½ºÆ® ¾÷ ÀÌµ¿";
BA_ "GenSigSendType" SG_ 591 ATS_RLStHRestUpBtn 4;
BA_ "UserSigValidity" SG_ 591 ATS_RLStHRestUpBtn 3;
BA_ "NetworkRequest" SG_ 591 ATS_RLStHRestUpBtn 0;
BA_ "NetworkRequestHoldingTime" SG_ 591 ATS_RLStHRestUpBtn 5000;
BA_ "Version" SG_ 591 ATS_RLStHRestUpBtn "19.09.02";
BA_ "Description" SG_ 591 ATS_RLStHRestDnBtn "ÈÄ¼® LH Çìµå·¹½ºÆ® ´Ù¿î ÀÌµ¿";
BA_ "GenSigSendType" SG_ 591 ATS_RLStHRestDnBtn 4;
BA_ "UserSigValidity" SG_ 591 ATS_RLStHRestDnBtn 3;
BA_ "NetworkRequest" SG_ 591 ATS_RLStHRestDnBtn 0;
BA_ "NetworkRequestHoldingTime" SG_ 591 ATS_RLStHRestDnBtn 5000;
BA_ "Version" SG_ 591 ATS_RLStHRestDnBtn "19.09.02";
BA_ "Description" SG_ 591 ATS_RLStHRestFwdBtn "ÈÄ¼® LH Çìµå·¹½ºÆ® Àü¹æ ÀÌµ¿";
BA_ "GenSigSendType" SG_ 591 ATS_RLStHRestFwdBtn 4;
BA_ "UserSigValidity" SG_ 591 ATS_RLStHRestFwdBtn 3;
BA_ "NetworkRequest" SG_ 591 ATS_RLStHRestFwdBtn 0;
BA_ "NetworkRequestHoldingTime" SG_ 591 ATS_RLStHRestFwdBtn 5000;
BA_ "Version" SG_ 591 ATS_RLStHRestFwdBtn "19.09.02";
BA_ "Description" SG_ 591 ATS_RLStHRestBwdBtn "ÈÄ¼® LH Çìµå·¹½ºÆ® ÈÄ¹æ ÀÌµ¿";
BA_ "GenSigSendType" SG_ 591 ATS_RLStHRestBwdBtn 4;
BA_ "UserSigValidity" SG_ 591 ATS_RLStHRestBwdBtn 3;
BA_ "NetworkRequest" SG_ 591 ATS_RLStHRestBwdBtn 0;
BA_ "NetworkRequestHoldingTime" SG_ 591 ATS_RLStHRestBwdBtn 5000;
BA_ "Version" SG_ 591 ATS_RLStHRestBwdBtn "19.09.02";
BA_ "Description" SG_ 591 ATS_RLStLegRestUpBtn "ÈÄ¼® LH ·¹±×·¹½ºÆ® UP";
BA_ "GenSigSendType" SG_ 591 ATS_RLStLegRestUpBtn 4;
BA_ "UserSigValidity" SG_ 591 ATS_RLStLegRestUpBtn 3;
BA_ "NetworkRequest" SG_ 591 ATS_RLStLegRestUpBtn 0;
BA_ "NetworkRequestHoldingTime" SG_ 591 ATS_RLStLegRestUpBtn 5000;
BA_ "Version" SG_ 591 ATS_RLStLegRestUpBtn "19.11.09";
BA_ "Description" SG_ 591 ATS_RStLegRestDnBtn "ÈÄ¼® LH ·¹±×·¹½ºÆ® DOWN";
BA_ "GenSigSendType" SG_ 591 ATS_RStLegRestDnBtn 4;
BA_ "UserSigValidity" SG_ 591 ATS_RStLegRestDnBtn 3;
BA_ "NetworkRequest" SG_ 591 ATS_RStLegRestDnBtn 0;
BA_ "NetworkRequestHoldingTime" SG_ 591 ATS_RStLegRestDnBtn 5000;
BA_ "Version" SG_ 591 ATS_RStLegRestDnBtn "19.11.09";
BA_ "Description" SG_ 591 ATS_RLStLegRestExtUpBtn "ÈÄ¼® LH ·¹±×·¹½ºÆ® EXT";
BA_ "GenSigSendType" SG_ 591 ATS_RLStLegRestExtUpBtn 4;
BA_ "UserSigValidity" SG_ 591 ATS_RLStLegRestExtUpBtn 3;
BA_ "NetworkRequest" SG_ 591 ATS_RLStLegRestExtUpBtn 0;
BA_ "NetworkRequestHoldingTime" SG_ 591 ATS_RLStLegRestExtUpBtn 5000;
BA_ "Version" SG_ 591 ATS_RLStLegRestExtUpBtn "19.11.09";
BA_ "Description" SG_ 591 ATS_RLStLegRestExtDnBtn "ÈÄ¼® LH ·¹±×·¹½ºÆ® EXT BWD";
BA_ "GenSigSendType" SG_ 591 ATS_RLStLegRestExtDnBtn 4;
BA_ "UserSigValidity" SG_ 591 ATS_RLStLegRestExtDnBtn 3;
BA_ "NetworkRequest" SG_ 591 ATS_RLStLegRestExtDnBtn 0;
BA_ "NetworkRequestHoldingTime" SG_ 591 ATS_RLStLegRestExtDnBtn 5000;
BA_ "Version" SG_ 591 ATS_RLStLegRestExtDnBtn "19.11.09";
BA_ "Description" SG_ 591 ATS_RLStShoulderADJFwdBtn "ÈÄ¼® LH ¼ñ´õ¾îÁ®½ºÅÍ FWD";
BA_ "GenSigSendType" SG_ 591 ATS_RLStShoulderADJFwdBtn 4;
BA_ "UserSigValidity" SG_ 591 ATS_RLStShoulderADJFwdBtn 3;
BA_ "NetworkRequest" SG_ 591 ATS_RLStShoulderADJFwdBtn 0;
BA_ "NetworkRequestHoldingTime" SG_ 591 ATS_RLStShoulderADJFwdBtn 5000;
BA_ "Version" SG_ 591 ATS_RLStShoulderADJFwdBtn "20.03.02";
BA_ "Description" SG_ 591 ATS_RLStShoulderADJBwdBtn "ÈÄ¼® LH ¼ñ´õ¾îÁ®½ºÅÍ BWD";
BA_ "GenSigSendType" SG_ 591 ATS_RLStShoulderADJBwdBtn 4;
BA_ "UserSigValidity" SG_ 591 ATS_RLStShoulderADJBwdBtn 3;
BA_ "NetworkRequest" SG_ 591 ATS_RLStShoulderADJBwdBtn 0;
BA_ "NetworkRequestHoldingTime" SG_ 591 ATS_RLStShoulderADJBwdBtn 5000;
BA_ "Version" SG_ 591 ATS_RLStShoulderADJBwdBtn "20.03.02";
BA_ "GenMsgSendType" BO_ 1058 0;
BA_ "Description" SG_ 1058 BCM_Crc10Val "The data area for CRC calculation is based on the data length (DLC) of the message DB.

The CRC shall be calculated over the entire data block (excluding the CRC bytes) including the user data, alive counter and Data ID 

 

- CRC Polynomial (0x1D) , Initial Value : 0x00, XOR value : 0xFF, Data ID Mode : Both, Data ID : Message ID + 0xF800 

- The initial value is for CRC calculation and the message should be sent with the calculated result value. 

The mathematical expression to 8 bit CRC polynomial is given here. G(x) = x8 + x4 + x3 + x2 + 1";
BA_ "GenSigSendType" SG_ 1058 BCM_Crc10Val 4;
BA_ "GenSigStartValue" SG_ 1058 BCM_Crc10Val 255;
BA_ "UserSigValidity" SG_ 1058 BCM_Crc10Val 0;
BA_ "Version" SG_ 1058 BCM_Crc10Val "18.11.08";
BA_ "Description" SG_ 1058 BCM_AlvCnt10Val "For the first transmission request for a data element the counter shall be initialized with 0 and shall be incremented by 1

for every subsequent send request. When the counter reaches the maximum value(0xE), then it shall restart with 0 for the next send request";
BA_ "GenSigSendType" SG_ 1058 BCM_AlvCnt10Val 4;
BA_ "UserSigValidity" SG_ 1058 BCM_AlvCnt10Val 0;
BA_ "Version" SG_ 1058 BCM_AlvCnt10Val "18.11.08";
BA_ "GenSigSendType" SG_ 1058 Wiper_PrkngPosSta 4;
BA_ "UserSigValidity" SG_ 1058 Wiper_PrkngPosSta 0;
BA_ "NetworkRequest" SG_ 1058 Wiper_PrkngPosSta 0;
BA_ "NetworkRequestHoldingTime" SG_ 1058 Wiper_PrkngPosSta 5000;
BA_ "Version" SG_ 1058 Wiper_PrkngPosSta "17.12.00";
BA_ "Description" SG_ 1058 Wiper_RainSnsrOptionTyp "Rain Sensor Option Information";
BA_ "GenSigSendType" SG_ 1058 Wiper_RainSnsrOptionTyp 4;
BA_ "UserSigValidity" SG_ 1058 Wiper_RainSnsrOptionTyp 0;
BA_ "NetworkRequest" SG_ 1058 Wiper_RainSnsrOptionTyp 0;
BA_ "NetworkRequestHoldingTime" SG_ 1058 Wiper_RainSnsrOptionTyp 5000;
BA_ "Version" SG_ 1058 Wiper_RainSnsrOptionTyp "17.12.00";
BA_ "Description" SG_ 1058 Wiper_RainSnsrSta "This signal represents the status of Rain Sensor signal state. 

- '20. 8/3 : Changed value table (0x5, 0x6 : Fault2/3 ¡æ Reserved)";
BA_ "GenSigSendType" SG_ 1058 Wiper_RainSnsrSta 4;
BA_ "UserSigValidity" SG_ 1058 Wiper_RainSnsrSta 0;
BA_ "NetworkRequest" SG_ 1058 Wiper_RainSnsrSta 0;
BA_ "NetworkRequestHoldingTime" SG_ 1058 Wiper_RainSnsrSta 5000;
BA_ "Version" SG_ 1058 Wiper_RainSnsrSta "20.08.00";
BA_ "Description" SG_ 1058 Wiper_HtWshNzzlCmd "Heated Washer Nozzle Command";
BA_ "GenSigSendType" SG_ 1058 Wiper_HtWshNzzlCmd 4;
BA_ "UserSigValidity" SG_ 1058 Wiper_HtWshNzzlCmd 0;
BA_ "NetworkRequest" SG_ 1058 Wiper_HtWshNzzlCmd 0;
BA_ "NetworkRequestHoldingTime" SG_ 1058 Wiper_HtWshNzzlCmd 5000;
BA_ "Version" SG_ 1058 Wiper_HtWshNzzlCmd "20.08.07";
BA_ "Description" SG_ 1058 BCM_SolSnsrRt "This signal indicates solar sensor output W/m^2 - RH";
BA_ "GenSigSendType" SG_ 1058 BCM_SolSnsrRt 4;
BA_ "UserSigValidity" SG_ 1058 BCM_SolSnsrRt 0;
BA_ "NetworkRequest" SG_ 1058 BCM_SolSnsrRt 0;
BA_ "NetworkRequestHoldingTime" SG_ 1058 BCM_SolSnsrRt 5000;
BA_ "Version" SG_ 1058 BCM_SolSnsrRt "21.11.04";
BA_ "Description" SG_ 1058 BCM_SolSnsrLft "This signal indicates solar sensor output W/m^2 - LH";
BA_ "GenSigSendType" SG_ 1058 BCM_SolSnsrLft 4;
BA_ "UserSigValidity" SG_ 1058 BCM_SolSnsrLft 0;
BA_ "NetworkRequest" SG_ 1058 BCM_SolSnsrLft 0;
BA_ "NetworkRequestHoldingTime" SG_ 1058 BCM_SolSnsrLft 5000;
BA_ "Version" SG_ 1058 BCM_SolSnsrLft "21.11.04";
BA_ "Description" SG_ 1058 BCM_GearPosPSta "This signal is valid only when connected to Key Interlock SW or P Position SW as a circuit";
BA_ "GenSigSendType" SG_ 1058 BCM_GearPosPSta 4;
BA_ "UserSigValidity" SG_ 1058 BCM_GearPosPSta 0;
BA_REL_ "GenSigTimeoutTime" BU_SG_REL_ SCM SG_ 1058 BCM_GearPosPSta 1500;
BA_REL_ "GenSigTimeoutTime" BU_SG_REL_ APSU SG_ 1058 BCM_GearPosPSta 1500;
BA_REL_ "GenSigTimeoutTime" BU_SG_REL_ RLHV SG_ 1058 BCM_GearPosPSta 1500;
BA_REL_ "GenSigTimeoutTime" BU_SG_REL_ RRHV SG_ 1058 BCM_GearPosPSta 1500;
BA_REL_ "GenSigTimeoutTime" BU_SG_REL_ DPSU SG_ 1058 BCM_GearPosPSta 1500;
BA_REL_ "GenSigTimeoutTime" BU_SG_REL_ PFSU SG_ 1058 BCM_GearPosPSta 1500;
BA_REL_ "GenSigTimeoutTime" BU_SG_REL_ RRPSU SG_ 1058 BCM_GearPosPSta 1500;
BA_REL_ "GenSigTimeoutTime" BU_SG_REL_ RLPSU SG_ 1058 BCM_GearPosPSta 1500;
BA_REL_ "GenSigTimeoutTime" BU_SG_REL_ ATS SG_ 1058 BCM_GearPosPSta 1500;
BA_ "NetworkRequest" SG_ 1058 BCM_GearPosPSta 0;
BA_ "NetworkRequestHoldingTime" SG_ 1058 BCM_GearPosPSta 5000;
BA_ "Version" SG_ 1058 BCM_GearPosPSta "21.07.04";
BA_ "Description" SG_ 1058 BCM_SunRoofOpnSta "-Sunroof open/close state";
BA_ "GenSigSendType" SG_ 1058 BCM_SunRoofOpnSta 4;
BA_ "UserSigValidity" SG_ 1058 BCM_SunRoofOpnSta 0;
BA_ "NetworkRequest" SG_ 1058 BCM_SunRoofOpnSta 0;
BA_ "NetworkRequestHoldingTime" SG_ 1058 BCM_SunRoofOpnSta 5000;
BA_ "Version" SG_ 1058 BCM_SunRoofOpnSta "17.12.00";
BA_ "Description" SG_ 1058 SunRoof_RrBlindErrSta "Rear Sunroof Blind error Status (LIN to CAN signal)

-LIN Signal Name : SunBlind_Rear_Error";
BA_ "GenSigSendType" SG_ 1058 SunRoof_RrBlindErrSta 4;
BA_ "UserSigValidity" SG_ 1058 SunRoof_RrBlindErrSta 0;
BA_ "Version" SG_ 1058 SunRoof_RrBlindErrSta "20.07.00";
BA_ "Description" SG_ 1058 Wiper_AutoWashModeSta "Auto Wash Mode Wiper State";
BA_ "GenSigSendType" SG_ 1058 Wiper_AutoWashModeSta 4;
BA_ "UserSigValidity" SG_ 1058 Wiper_AutoWashModeSta 0;
BA_ "NetworkRequest" SG_ 1058 Wiper_AutoWashModeSta 0;
BA_ "NetworkRequestHoldingTime" SG_ 1058 Wiper_AutoWashModeSta 5000;
BA_ "Version" SG_ 1058 Wiper_AutoWashModeSta "21.12.00";
BA_ "GenMsgSendType" BO_ 2357404929 0;
BA_ "GenMsgCycleTimeFast" BO_ 2357404929 0;
BA_ "GenMsgNrOfRepetition" BO_ 2357404929 0;
BA_ "VFrameFormat" BO_ 2357404929 1;
BA_ "Description" SG_ 2357404929 BMS_Crc6Val "The data area for CRC calculation is based on the data length (DLC) of the message DB.

The CRC shall be calculated over the entire data block (excluding the CRC bytes) including the user data, alive counter and Data ID

 

- CRC Polynomial (0x1021) , Initial Value : 0xFFFF, XOR value : 0x0000, Data ID : Message ID + 0xF800 

- The initial value is for CRC calculation and the message should be sent with the calculated result value. 

- The mathematical expression to 16 bit CRC polynomial is given here. G(x) = x16 + x12 + x5 + 1";
BA_ "GenSigStartValue" SG_ 2357404929 BMS_Crc6Val 65535;
BA_ "UserSigValidity" SG_ 2357404929 BMS_Crc6Val 3;
BA_ "RoutingFactor" SG_ 2357404929 BMS_Crc6Val 2;
BA_ "Version" SG_ 2357404929 BMS_Crc6Val "18.11.08";
BA_ "Description" SG_ 2357404929 BMS_AlvCnt6Val "For the first transmission request for a data element the counter shall be initialized with 0 and shall be incremented by 1 for every subsequent send request. 

When the counter reaches the maximum value(0xFF), then it shall restart with 0 for the next send request";
BA_ "UserSigValidity" SG_ 2357404929 BMS_AlvCnt6Val 5;
BA_ "RoutingFactor" SG_ 2357404929 BMS_AlvCnt6Val 2;
BA_ "Version" SG_ 2357404929 BMS_AlvCnt6Val "18.11.08";
BA_ "Description" SG_ 2357404929 CHRG_StndChrgConnSta_120V "Standard Charging(120V) Connector Status  (CF_Bms_StdCha_120V)";
BA_ "UserSigValidity" SG_ 2357404929 CHRG_StndChrgConnSta_120V 7;
BA_ "RoutingFactor" SG_ 2357404929 CHRG_StndChrgConnSta_120V 2;
BA_ "Version" SG_ 2357404929 CHRG_StndChrgConnSta_120V "18.08.07";
BA_ "Description" SG_ 2357404929 CHRG_StndChrgSta "BMS sets this Flag when Battery is standard mode charging (CF_Bms_StdCha)";
BA_ "UserSigValidity" SG_ 2357404929 CHRG_StndChrgSta 7;
BA_ "RoutingFactor" SG_ 2357404929 CHRG_StndChrgSta 2;
BA_ "Version" SG_ 2357404929 CHRG_StndChrgSta "18.08.07";
BA_ "Description" SG_ 2357404929 CHRG_ChrgCycStrtSta "Charging Cycle Start (CF_Bms_Charging_ST)";
BA_ "UserSigValidity" SG_ 2357404929 CHRG_ChrgCycStrtSta 7;
BA_ "RoutingFactor" SG_ 2357404929 CHRG_ChrgCycStrtSta 2;
BA_ "Version" SG_ 2357404929 CHRG_ChrgCycStrtSta "18.08.07";
BA_ "Description" SG_ 2357404929 CHRG_FulChrgSta "0:None, 1:Fully Charged";
BA_ "UserSigValidity" SG_ 2357404929 CHRG_FulChrgSta 7;
BA_ "RoutingFactor" SG_ 2357404929 CHRG_FulChrgSta 2;
BA_ "Version" SG_ 2357404929 CHRG_FulChrgSta "18.08.07";
BA_ "Description" SG_ 2357404929 CHRG_ChrgSta "0:None, 1:Charging";
BA_ "UserSigValidity" SG_ 2357404929 CHRG_ChrgSta 7;
BA_REL_ "GenSigTimeoutTime" BU_SG_REL_ SWRC SG_ 2357404929 CHRG_ChrgSta 1500;
BA_ "RoutingFactor" SG_ 2357404929 CHRG_ChrgSta 2;
BA_ "Version" SG_ 2357404929 CHRG_ChrgSta "18.08.07";
BA_ "Description" SG_ 2357404929 CHRG_SpplmntChrgSta "Supplementary Charge Status (CF_Bms_SupplyChgStat)";
BA_ "UserSigValidity" SG_ 2357404929 CHRG_SpplmntChrgSta 7;
BA_ "RoutingFactor" SG_ 2357404929 CHRG_SpplmntChrgSta 2;
BA_ "Version" SG_ 2357404929 CHRG_SpplmntChrgSta "18.08.07";
BA_ "Description" SG_ 2357404929 CHRG_LdcInhbtReq "LDC Output Inhibit request";
BA_ "UserSigValidity" SG_ 2357404929 CHRG_LdcInhbtReq 7;
BA_ "RoutingFactor" SG_ 2357404929 CHRG_LdcInhbtReq 2;
BA_ "Version" SG_ 2357404929 CHRG_LdcInhbtReq "18.08.07";
BA_ "Description" SG_ 2357404929 CHRG_NorChgFnshSta "CHRG_ChargeNormalFinishConditionStatus (CF_BMS_ChgFinished)";
BA_ "UserSigValidity" SG_ 2357404929 CHRG_NorChgFnshSta 7;
BA_ "RoutingFactor" SG_ 2357404929 CHRG_NorChgFnshSta 2;
BA_ "Version" SG_ 2357404929 CHRG_NorChgFnshSta "18.08.07";
BA_ "Description" SG_ 2357404929 CHRG_ChrgFnshSta "Standard Charge finish flag (CF_BMS_ChgFinished)";
BA_ "UserSigValidity" SG_ 2357404929 CHRG_ChrgFnshSta 7;
BA_ "RoutingFactor" SG_ 2357404929 CHRG_ChrgFnshSta 2;
BA_ "Version" SG_ 2357404929 CHRG_ChrgFnshSta "18.08.07";
BA_ "Description" SG_ 2357404929 CHRG_Ig3RlyOffReq "IG3 Rly Off Requset";
BA_ "UserSigValidity" SG_ 2357404929 CHRG_Ig3RlyOffReq 7;
BA_ "RoutingFactor" SG_ 2357404929 CHRG_Ig3RlyOffReq 2;
BA_ "Version" SG_ 2357404929 CHRG_Ig3RlyOffReq "17.11.00";
BA_ "Description" SG_ 2357404929 CHRG_PShftChgSta "The Flag To Change P Shift";
BA_ "UserSigValidity" SG_ 2357404929 CHRG_PShftChgSta 7;
BA_ "RoutingFactor" SG_ 2357404929 CHRG_PShftChgSta 2;
BA_ "Version" SG_ 2357404929 CHRG_PShftChgSta "17.11.00";
BA_ "Description" SG_ 2357404929 CHRG_PilotFlSta "Notify Pilotline Fail To Cluster (CF_Bms_Notify_Pilotfail)";
BA_ "UserSigValidity" SG_ 2357404929 CHRG_PilotFlSta 7;
BA_ "RoutingFactor" SG_ 2357404929 CHRG_PilotFlSta 2;
BA_ "Version" SG_ 2357404929 CHRG_PilotFlSta "18.08.07";
BA_ "Description" SG_ 2357404929 CHRG_ObcCmdCurrVal "CC target current command (CR_Bms_ObcCmdCurrt_A)";
BA_ "UserSigValidity" SG_ 2357404929 CHRG_ObcCmdCurrVal 7;
BA_ "RoutingFactor" SG_ 2357404929 CHRG_ObcCmdCurrVal 2;
BA_ "Version" SG_ 2357404929 CHRG_ObcCmdCurrVal "18.08.07";
BA_ "GenMsgSendType" BO_ 2357404930 0;
BA_ "GenMsgCycleTimeFast" BO_ 2357404930 0;
BA_ "GenMsgNrOfRepetition" BO_ 2357404930 0;
BA_ "VFrameFormat" BO_ 2357404930 1;
BA_ "Description" SG_ 2357404930 CHRG_StndChrgRmnTimeVal "Standard Charging remained time (CR_Bms_ScChgRemainedTime_min)";
BA_ "UserSigValidity" SG_ 2357404930 CHRG_StndChrgRmnTimeVal 7;
BA_ "RoutingFactor" SG_ 2357404930 CHRG_StndChrgRmnTimeVal 2;
BA_ "Version" SG_ 2357404930 CHRG_StndChrgRmnTimeVal "18.08.07";
BA_ "Description" SG_ 2357404930 CHRG_ChrgRmnTimeVal "Charging remained time (CR_Bms_ChgRemainedTime_min)";
BA_ "UserSigValidity" SG_ 2357404930 CHRG_ChrgRmnTimeVal 7;
BA_ "RoutingFactor" SG_ 2357404930 CHRG_ChrgRmnTimeVal 2;
BA_ "Version" SG_ 2357404930 CHRG_ChrgRmnTimeVal "18.08.07";
BA_ "Description" SG_ 2357404930 CHRG_ObcRlyOnSta "OBC Relay ON status :0x0:Off, 0x1:On";
BA_ "UserSigValidity" SG_ 2357404930 CHRG_ObcRlyOnSta 7;
BA_ "RoutingFactor" SG_ 2357404930 CHRG_ObcRlyOnSta 2;
BA_ "Version" SG_ 2357404930 CHRG_ObcRlyOnSta "18.08.07";
BA_ "Description" SG_ 2357404930 CHRG_NrmlOpSta "BMS Normal Operation Flag

 <Signal Value Table>

 * Normal operation: 0¡æ1¡æ0¡æ1¡æ... (repetitive change 0¡ê1)

 * Abnormal operation: 0 or 1 fixed";
BA_ "UserSigValidity" SG_ 2357404930 CHRG_NrmlOpSta 7;
BA_ "RoutingFactor" SG_ 2357404930 CHRG_NrmlOpSta 2;
BA_ "Version" SG_ 2357404930 CHRG_NrmlOpSta "17.11.00";
BA_ "Description" SG_ 2357404930 CHRG_ChgLamp_1EA "Charging Lamp Request (1EA Lamp)";
BA_ "UserSigValidity" SG_ 2357404930 CHRG_ChgLamp_1EA 7;
BA_ "RoutingFactor" SG_ 2357404930 CHRG_ChgLamp_1EA 2;
BA_ "Version" SG_ 2357404930 CHRG_ChgLamp_1EA "18.08.07";
BA_ "Description" SG_ 2357404930 CHRG_ObcCmdVoltVal "CV target voltage command (CR_Bms_ObcCmdVolt_V)";
BA_ "UserSigValidity" SG_ 2357404930 CHRG_ObcCmdVoltVal 7;
BA_ "RoutingFactor" SG_ 2357404930 CHRG_ObcCmdVoltVal 2;
BA_ "Version" SG_ 2357404930 CHRG_ObcCmdVoltVal "18.08.07";
BA_ "Description" SG_ 2357404930 CHRG_ObcMainVoltVal "The Mains Voltage of OBC



¡Ø Start Value : Physical value";
BA_ "UserSigValidity" SG_ 2357404930 CHRG_ObcMainVoltVal 7;
BA_ "RoutingFactor" SG_ 2357404930 CHRG_ObcMainVoltVal 2;
BA_ "Version" SG_ 2357404930 CHRG_ObcMainVoltVal "17.11.00";
BA_ "GenMsgSendType" BO_ 2357404931 0;
BA_ "GenMsgCycleTimeFast" BO_ 2357404931 0;
BA_ "GenMsgNrOfRepetition" BO_ 2357404931 0;
BA_ "VFrameFormat" BO_ 2357404931 1;
BA_ "Description" SG_ 2357404931 CHRG_StndChrgRmnTime120Val "Standard Charging(120V) Remained Time (CR_Bms_ScChgRemainedTime_120V)";
BA_ "UserSigValidity" SG_ 2357404931 CHRG_StndChrgRmnTime120Val 7;
BA_ "RoutingFactor" SG_ 2357404931 CHRG_StndChrgRmnTime120Val 2;
BA_ "Version" SG_ 2357404931 CHRG_StndChrgRmnTime120Val "18.08.07";
BA_ "Description" SG_ 2357404931 CHRG_StndChrgRmnTime240Val "Standard Charging(240V) Remained Time";
BA_ "UserSigValidity" SG_ 2357404931 CHRG_StndChrgRmnTime240Val 7;
BA_ "RoutingFactor" SG_ 2357404931 CHRG_StndChrgRmnTime240Val 2;
BA_ "Version" SG_ 2357404931 CHRG_StndChrgRmnTime240Val "17.11.00";
BA_ "Description" SG_ 2357404931 CHRG_ObcOutCurrVal "The OutCurrent Of Obc 



¡Ø Start Value : Physical value";
BA_ "UserSigValidity" SG_ 2357404931 CHRG_ObcOutCurrVal 7;
BA_ "RoutingFactor" SG_ 2357404931 CHRG_ObcOutCurrVal 2;
BA_ "Version" SG_ 2357404931 CHRG_ObcOutCurrVal "17.11.00";
BA_ "Description" SG_ 2357404931 CHRG_DomStndChrgRmnTimeVal "Standard Charging Remained Time-ICCB Domestic";
BA_ "UserSigValidity" SG_ 2357404931 CHRG_DomStndChrgRmnTimeVal 7;
BA_ "RoutingFactor" SG_ 2357404931 CHRG_DomStndChrgRmnTimeVal 2;
BA_ "Version" SG_ 2357404931 CHRG_DomStndChrgRmnTimeVal "17.11.00";
BA_ "Description" SG_ 2357404931 CHRG_ChrgFltSubCodVal "Charging Diagnosis Sub Code";
BA_ "UserSigValidity" SG_ 2357404931 CHRG_ChrgFltSubCodVal 7;
BA_ "RoutingFactor" SG_ 2357404931 CHRG_ChrgFltSubCodVal 2;
BA_ "Version" SG_ 2357404931 CHRG_ChrgFltSubCodVal "17.11.00";
BA_ "GenMsgSendType" BO_ 2357404932 0;
BA_ "GenMsgCycleTimeFast" BO_ 2357404932 0;
BA_ "GenMsgNrOfRepetition" BO_ 2357404932 0;
BA_ "VFrameFormat" BO_ 2357404932 1;
BA_ "Description" SG_ 2357404932 CHRG_ScChgTrgtSocVal "CHRG_Target State Of ScChargeValue (CR_Bms_ScChgTagetSoc)";
BA_ "UserSigValidity" SG_ 2357404932 CHRG_ScChgTrgtSocVal 7;
BA_ "RoutingFactor" SG_ 2357404932 CHRG_ScChgTrgtSocVal 2;
BA_ "Version" SG_ 2357404932 CHRG_ScChgTrgtSocVal "19.01.00";
BA_ "Description" SG_ 2357404932 CHRG_RealStndChrgRmnTimeVal "Standard Charging Remained Time - Real Calculation Time";
BA_ "UserSigValidity" SG_ 2357404932 CHRG_RealStndChrgRmnTimeVal 7;
BA_ "RoutingFactor" SG_ 2357404932 CHRG_RealStndChrgRmnTimeVal 2;
BA_ "Version" SG_ 2357404932 CHRG_RealStndChrgRmnTimeVal "17.11.00";
BA_ "Description" SG_ 2357404932 PHEV_EstChrgRmnTimeVal "Remained Charging Estmate Time for Low Cost Charging";
BA_ "UserSigValidity" SG_ 2357404932 PHEV_EstChrgRmnTimeVal 7;
BA_ "RoutingFactor" SG_ 2357404932 PHEV_EstChrgRmnTimeVal 2;
BA_ "Version" SG_ 2357404932 PHEV_EstChrgRmnTimeVal "17.11.00";
BA_ "Description" SG_ 2357404932 CHRG_ChrgLmp_3EA "CHRG_Charge Lamp(3EA Lamp)";
BA_ "UserSigValidity" SG_ 2357404932 CHRG_ChrgLmp_3EA 7;
BA_ "RoutingFactor" SG_ 2357404932 CHRG_ChrgLmp_3EA 2;
BA_ "Version" SG_ 2357404932 CHRG_ChrgLmp_3EA "18.08.07";
BA_ "Description" SG_ 2357404932 CHRG_EuroStndChrgRmnTimeVal "Standard Charging Remained Time-ICCB Europe";
BA_ "UserSigValidity" SG_ 2357404932 CHRG_EuroStndChrgRmnTimeVal 7;
BA_ "RoutingFactor" SG_ 2357404932 CHRG_EuroStndChrgRmnTimeVal 2;
BA_ "Version" SG_ 2357404932 CHRG_EuroStndChrgRmnTimeVal "17.11.00";
BA_ "GenMsgSendType" BO_ 1079 0;
BA_ "Description" SG_ 1079 CTM_TrailerAct "This signal is used for control the Trailer Act function.";
BA_ "GenSigSendType" SG_ 1079 CTM_TrailerAct 4;
BA_ "UserSigValidity" SG_ 1079 CTM_TrailerAct 3;
BA_REL_ "GenSigTimeoutTime" BU_SG_REL_ BLTN_CAM SG_ 1079 CTM_TrailerAct 1500;
BA_ "NetworkRequest" SG_ 1079 CTM_TrailerAct 0;
BA_ "Version" SG_ 1079 CTM_TrailerAct "18.04.01";
BA_ "Description" SG_ 1079 CTM_ExtTailLmpLftOpnSta "Trailer Exterior Tail Lamp Left OpenStatus";
BA_ "GenSigSendType" SG_ 1079 CTM_ExtTailLmpLftOpnSta 4;
BA_ "UserSigValidity" SG_ 1079 CTM_ExtTailLmpLftOpnSta 3;
BA_ "NetworkRequest" SG_ 1079 CTM_ExtTailLmpLftOpnSta 0;
BA_ "Version" SG_ 1079 CTM_ExtTailLmpLftOpnSta "18.10.07";
BA_ "Description" SG_ 1079 CTM_ExtTailLmpRtOpnSta "Trailer Exterior Tail Lamp Right OpenStatus";
BA_ "GenSigSendType" SG_ 1079 CTM_ExtTailLmpRtOpnSta 4;
BA_ "UserSigValidity" SG_ 1079 CTM_ExtTailLmpRtOpnSta 3;
BA_ "NetworkRequest" SG_ 1079 CTM_ExtTailLmpRtOpnSta 0;
BA_ "Version" SG_ 1079 CTM_ExtTailLmpRtOpnSta "18.10.07";
BA_ "Description" SG_ 1079 CTM_Exra_EbrakSta "Trailer Ebrake Controller ActiveStatus";
BA_ "GenSigSendType" SG_ 1079 CTM_Exra_EbrakSta 4;
BA_ "UserSigValidity" SG_ 1079 CTM_Exra_EbrakSta 0;
BA_ "Version" SG_ 1079 CTM_Exra_EbrakSta "21.06.10";
BA_ "Description" SG_ 1079 CTM_RearfogAct "This signal is used for display the rear fog lamp mounted on the trailer.";
BA_ "GenSigSendType" SG_ 1079 CTM_RearfogAct 4;
BA_ "UserSigValidity" SG_ 1079 CTM_RearfogAct 3;
BA_ "NetworkRequest" SG_ 1079 CTM_RearfogAct 0;
BA_ "Version" SG_ 1079 CTM_RearfogAct "18.10.07";
BA_ "Description" SG_ 1079 CTM_StpLmpOpnSta "Trailer Stop Lamp OpenStatus";
BA_ "GenSigSendType" SG_ 1079 CTM_StpLmpOpnSta 4;
BA_ "UserSigValidity" SG_ 1079 CTM_StpLmpOpnSta 3;
BA_ "NetworkRequest" SG_ 1079 CTM_StpLmpOpnSta 0;
BA_ "Version" SG_ 1079 CTM_StpLmpOpnSta "18.10.07";
BA_ "Description" SG_ 1079 CTM_TrnSigLmpLftOpnSta "Trailer T/SIG Lamp Left OpenStatus";
BA_ "GenSigSendType" SG_ 1079 CTM_TrnSigLmpLftOpnSta 4;
BA_ "UserSigValidity" SG_ 1079 CTM_TrnSigLmpLftOpnSta 3;
BA_ "NetworkRequest" SG_ 1079 CTM_TrnSigLmpLftOpnSta 0;
BA_ "Version" SG_ 1079 CTM_TrnSigLmpLftOpnSta "18.10.07";
BA_ "Description" SG_ 1079 CTM_TrnSigLmpRtOpnSta "Trailer T/SIG Lamp Right OpenStatus";
BA_ "GenSigSendType" SG_ 1079 CTM_TrnSigLmpRtOpnSta 4;
BA_ "UserSigValidity" SG_ 1079 CTM_TrnSigLmpRtOpnSta 3;
BA_ "NetworkRequest" SG_ 1079 CTM_TrnSigLmpRtOpnSta 0;
BA_ "Version" SG_ 1079 CTM_TrnSigLmpRtOpnSta "18.10.07";
BA_ "GenMsgSendType" BO_ 2424579841 0;
BA_ "VFrameFormat" BO_ 2424579841 1;
BA_ "Description" SG_ 2424579841 DATC_Crc11Val "The data area for CRC calculation is based on the data length (DLC) of the message DB.

The CRC shall be calculated over the entire data block (excluding the CRC bytes) including the user data, alive counter and Data ID

 

- CRC Polynomial (0x1021) , Initial Value : 0xFFFF, XOR value : 0x0000, Data ID : Message ID + 0xF800 

- The initial value is for CRC calculation and the message should be sent with the calculated result value. 

- The mathematical expression to 16 bit CRC polynomial is given here. G(x) = x16 + x12 + x5 + 1";
BA_ "GenSigSendType" SG_ 2424579841 DATC_Crc11Val 4;
BA_ "GenSigStartValue" SG_ 2424579841 DATC_Crc11Val 65535;
BA_ "UserSigValidity" SG_ 2424579841 DATC_Crc11Val 3;
BA_ "Version" SG_ 2424579841 DATC_Crc11Val "18.11.08";
BA_ "Description" SG_ 2424579841 DATC_AlvCnt11Val "For the first transmission request for a data element the counter shall be initialized with 0 and shall be incremented by 1 for every subsequent send request. 

When the counter reaches the maximum value(0xFF), then it shall restart with 0 for the next send request";
BA_ "GenSigSendType" SG_ 2424579841 DATC_AlvCnt11Val 4;
BA_ "UserSigValidity" SG_ 2424579841 DATC_AlvCnt11Val 3;
BA_ "Version" SG_ 2424579841 DATC_AlvCnt11Val "18.11.08";
BA_ "Description" SG_ 2424579841 DATC_TnnlClimtUSMSta "Tunnel Mode USM State";
BA_ "GenSigSendType" SG_ 2424579841 DATC_TnnlClimtUSMSta 4;
BA_ "UserSigValidity" SG_ 2424579841 DATC_TnnlClimtUSMSta 7;
BA_ "Version" SG_ 2424579841 DATC_TnnlClimtUSMSta "17.11.00";
BA_ "Description" SG_ 2424579841 DATC_ProximitySnsrSta "HTR CONTROL light near button ON/OFF USM f/back signal";
BA_ "GenSigSendType" SG_ 2424579841 DATC_ProximitySnsrSta 4;
BA_ "UserSigValidity" SG_ 2424579841 DATC_ProximitySnsrSta 7;
BA_ "Version" SG_ 2424579841 DATC_ProximitySnsrSta "17.11.00";
BA_ "Description" SG_ 2424579841 DATC_TunnelFuncOff4AutoDfgReq "DATC Turn off Tunnel Function for ADS";
BA_ "GenSigSendType" SG_ 2424579841 DATC_TunnelFuncOff4AutoDfgReq 4;
BA_ "UserSigValidity" SG_ 2424579841 DATC_TunnelFuncOff4AutoDfgReq 7;
BA_ "Version" SG_ 2424579841 DATC_TunnelFuncOff4AutoDfgReq "17.11.00";
BA_ "Description" SG_ 2424579841 DATC_RrCtlLckSta "Rear Lock Status Informed  DATC  to AVN";
BA_ "GenSigSendType" SG_ 2424579841 DATC_RrCtlLckSta 4;
BA_ "UserSigValidity" SG_ 2424579841 DATC_RrCtlLckSta 7;
BA_REL_ "GenSigTimeoutTime" BU_SG_REL_ ATS SG_ 2424579841 DATC_RrCtlLckSta 1500;
BA_ "Version" SG_ 2424579841 DATC_RrCtlLckSta "17.11.00";
BA_ "Description" SG_ 2424579841 DATC_DrvrStHtrUSMSta "If the 'Auto Comfort Control' function is applied separately to the Seat and Steering Wheel, 

this signal is used.";
BA_ "GenSigSendType" SG_ 2424579841 DATC_DrvrStHtrUSMSta 4;
BA_ "UserSigValidity" SG_ 2424579841 DATC_DrvrStHtrUSMSta 7;
BA_REL_ "GenSigTimeoutTime" BU_SG_REL_ APSU SG_ 2424579841 DATC_DrvrStHtrUSMSta 1500;
BA_REL_ "GenSigTimeoutTime" BU_SG_REL_ DPSU SG_ 2424579841 DATC_DrvrStHtrUSMSta 1500;
BA_ "Version" SG_ 2424579841 DATC_DrvrStHtrUSMSta "17.11.00";
BA_ "Description" SG_ 2424579841 DATC_InDrctVntUSMSta "This signal indicate Indirect Vent USM State.";
BA_ "GenSigSendType" SG_ 2424579841 DATC_InDrctVntUSMSta 4;
BA_ "UserSigValidity" SG_ 2424579841 DATC_InDrctVntUSMSta 3;
BA_ "Version" SG_ 2424579841 DATC_InDrctVntUSMSta "18.05.00";
BA_ "Description" SG_ 2424579841 DATC_WshFldUSMSta "This signal indicate Washer Fulid USM State.";
BA_ "GenSigSendType" SG_ 2424579841 DATC_WshFldUSMSta 4;
BA_ "UserSigValidity" SG_ 2424579841 DATC_WshFldUSMSta 7;
BA_ "Version" SG_ 2424579841 DATC_WshFldUSMSta "18.06.00";
BA_ "Description" SG_ 2424579841 DATC_DfgLgcUSMSta "This signal indicates USM States of DefLogic

(DEF ÇØÁ¦º¹±Í ·ÎÁ÷ USM ¼³Á¤°ª ¼Û½Å ½ÅÈ£)";
BA_ "GenSigSendType" SG_ 2424579841 DATC_DfgLgcUSMSta 4;
BA_ "GenSigStartValue" SG_ 2424579841 DATC_DfgLgcUSMSta 3;
BA_ "UserSigValidity" SG_ 2424579841 DATC_DfgLgcUSMSta 3;
BA_ "Version" SG_ 2424579841 DATC_DfgLgcUSMSta "18.07.03";
BA_ "Description" SG_ 2424579841 DATC_AutoFrshUSMSta "This signal indicates USM States of Auto Fresh

(°á·Î¹æÁö ÇØÁ¦ º¹±Í USM ¼³Á¤ »óÅÂ ¼Û½Å ½ÅÈ£)";
BA_ "GenSigSendType" SG_ 2424579841 DATC_AutoFrshUSMSta 4;
BA_ "GenSigStartValue" SG_ 2424579841 DATC_AutoFrshUSMSta 3;
BA_ "UserSigValidity" SG_ 2424579841 DATC_AutoFrshUSMSta 3;
BA_ "Version" SG_ 2424579841 DATC_AutoFrshUSMSta "18.07.03";
BA_ "Description" SG_ 2424579841 DATC_HptIntnstySta "This signal indicate the Haptic Intensity of Touch Button in the Heater Control.";
BA_ "GenSigSendType" SG_ 2424579841 DATC_HptIntnstySta 4;
BA_ "UserSigValidity" SG_ 2424579841 DATC_HptIntnstySta 7;
BA_ "Version" SG_ 2424579841 DATC_HptIntnstySta "18.11.01";
BA_ "Description" SG_ 2424579841 DATC_ClmtPwrSum_W "accumulated energy consumption while driving(200ms)";
BA_ "GenSigSendType" SG_ 2424579841 DATC_ClmtPwrSum_W 4;
BA_ "UserSigValidity" SG_ 2424579841 DATC_ClmtPwrSum_W 4;
BA_ "Version" SG_ 2424579841 DATC_ClmtPwrSum_W "18.09.00";
BA_ "GenMsgSendType" BO_ 1085 0;
BA_ "Description" SG_ 1085 DLBCU_ActiveDis "¿¡¾î¼­Æ÷Æ®¸ðµå AVN Ç¥½Ã";
BA_ "GenSigSendType" SG_ 1085 DLBCU_ActiveDis 4;
BA_ "UserSigValidity" SG_ 1085 DLBCU_ActiveDis 1;
BA_REL_ "GenSigTimeoutTime" BU_SG_REL_ CGW_CCU SG_ 1085 DLBCU_ActiveDis 1500;
BA_ "NetworkRequest" SG_ 1085 DLBCU_ActiveDis 0;
BA_ "NetworkRequestHoldingTime" SG_ 1085 DLBCU_ActiveDis 5000;
BA_ "Version" SG_ 1085 DLBCU_ActiveDis "18.09.01";
BA_ "Description" SG_ 1085 DLBCU_CushSoftSta "Äí¼Ç ¼ÒÇÁÆ®´Ï½º Signal ÇÇµå¹é to AVN";
BA_ "GenSigSendType" SG_ 1085 DLBCU_CushSoftSta 4;
BA_ "UserSigValidity" SG_ 1085 DLBCU_CushSoftSta 1;
BA_REL_ "GenSigTimeoutTime" BU_SG_REL_ CGW_CCU SG_ 1085 DLBCU_CushSoftSta 1500;
BA_ "NetworkRequest" SG_ 1085 DLBCU_CushSoftSta 0;
BA_ "NetworkRequestHoldingTime" SG_ 1085 DLBCU_CushSoftSta 5000;
BA_ "Version" SG_ 1085 DLBCU_CushSoftSta "18.10.11";
BA_ "Description" SG_ 1085 DLBCU_CellOpt "½ÃÆ® °ø¾Ð ½Ã½ºÅÛ »ç¾ç Á¤º¸ ½ÅÈ£(3Cell:·´¸Ó¼­Æ÷Æ®/5Cell:·³¹öº¼½ºÅÍ/7Cell:·³¹öº¼½ºÅÍÄí¼Ç)";
BA_ "GenSigSendType" SG_ 1085 DLBCU_CellOpt 4;
BA_ "UserSigValidity" SG_ 1085 DLBCU_CellOpt 0;
BA_ "NetworkRequest" SG_ 1085 DLBCU_CellOpt 0;
BA_ "NetworkRequestHoldingTime" SG_ 1085 DLBCU_CellOpt 5000;
BA_ "Version" SG_ 1085 DLBCU_CellOpt "18.09.01";
BA_ "Description" SG_ 1085 DLBCU_BodySpprtSta "Seat Body Support Function USM R Value";
BA_ "GenSigSendType" SG_ 1085 DLBCU_BodySpprtSta 4;
BA_ "UserSigValidity" SG_ 1085 DLBCU_BodySpprtSta 1;
BA_REL_ "GenSigTimeoutTime" BU_SG_REL_ CGW_CCU SG_ 1085 DLBCU_BodySpprtSta 1500;
BA_ "Version" SG_ 1085 DLBCU_BodySpprtSta "18.10.09";
BA_ "Description" SG_ 1085 DLBCU_BodySpprtDis "Seat Body Support Function Display Request";
BA_ "GenSigSendType" SG_ 1085 DLBCU_BodySpprtDis 4;
BA_ "UserSigValidity" SG_ 1085 DLBCU_BodySpprtDis 1;
BA_REL_ "GenSigTimeoutTime" BU_SG_REL_ CGW_CCU SG_ 1085 DLBCU_BodySpprtDis 1500;
BA_ "Version" SG_ 1085 DLBCU_BodySpprtDis "18.10.09";
BA_ "Description" SG_ 1085 DLBCU_SmartCtrl_Set_Rvalue "ÁÖÇà Áß Çã¸® º¸È£ ±â´É USM µ¿ÀÛ ¼³Á¤ °ª (R Value)";
BA_ "GenSigSendType" SG_ 1085 DLBCU_SmartCtrl_Set_Rvalue 4;
BA_ "UserSigValidity" SG_ 1085 DLBCU_SmartCtrl_Set_Rvalue 0;
BA_REL_ "GenSigTimeoutTime" BU_SG_REL_ CGW_CCU SG_ 1085 DLBCU_SmartCtrl_Set_Rvalue 1500;
BA_ "Version" SG_ 1085 DLBCU_SmartCtrl_Set_Rvalue "20.09.00";
BA_ "Description" SG_ 1085 DLBCU_DrvModUSMSta "µå¶óÀÌºê ¸ðµå ¿¬µ¿ Signal ÇÇµå¹é to AVN";
BA_ "GenSigSendType" SG_ 1085 DLBCU_DrvModUSMSta 4;
BA_ "UserSigValidity" SG_ 1085 DLBCU_DrvModUSMSta 1;
BA_REL_ "GenSigTimeoutTime" BU_SG_REL_ CGW_CCU SG_ 1085 DLBCU_DrvModUSMSta 1500;
BA_ "NetworkRequest" SG_ 1085 DLBCU_DrvModUSMSta 0;
BA_ "NetworkRequestHoldingTime" SG_ 1085 DLBCU_DrvModUSMSta 5000;
BA_ "Version" SG_ 1085 DLBCU_DrvModUSMSta "18.03.07";
BA_ "Description" SG_ 1085 DLBCU_ActiveStrSta "¿¡¾î¼­Æ÷Æ® ¸ðµå °­µµ Signal ÇÇµå¹é to AVN";
BA_ "GenSigSendType" SG_ 1085 DLBCU_ActiveStrSta 4;
BA_ "UserSigValidity" SG_ 1085 DLBCU_ActiveStrSta 1;
BA_REL_ "GenSigTimeoutTime" BU_SG_REL_ CGW_CCU SG_ 1085 DLBCU_ActiveStrSta 1500;
BA_ "NetworkRequest" SG_ 1085 DLBCU_ActiveStrSta 0;
BA_ "NetworkRequestHoldingTime" SG_ 1085 DLBCU_ActiveStrSta 5000;
BA_ "Version" SG_ 1085 DLBCU_ActiveStrSta "18.03.07";
BA_ "Description" SG_ 1085 DLBCU_ActiveTimeSta "¿¡¾î¼­Æ÷Æ® Àç»ý½Ã°£ Signal ÇÇµå¹é to AVN";
BA_ "GenSigSendType" SG_ 1085 DLBCU_ActiveTimeSta 4;
BA_ "UserSigValidity" SG_ 1085 DLBCU_ActiveTimeSta 1;
BA_REL_ "GenSigTimeoutTime" BU_SG_REL_ CGW_CCU SG_ 1085 DLBCU_ActiveTimeSta 1500;
BA_ "NetworkRequest" SG_ 1085 DLBCU_ActiveTimeSta 0;
BA_ "NetworkRequestHoldingTime" SG_ 1085 DLBCU_ActiveTimeSta 5000;
BA_ "Version" SG_ 1085 DLBCU_ActiveTimeSta "18.03.07";
BA_ "GenMsgSendType" BO_ 2164278529 0;
BA_ "GenMsgCycleTime" BO_ 2164278529 50;
BA_ "GenMsgCycleTimeFast" BO_ 2164278529 0;
BA_ "GenMsgNrOfRepetition" BO_ 2164278529 0;
BA_ "VFrameFormat" BO_ 2164278529 1;
BA_ "Description" SG_ 2164278529 HTCU_Crc4Val "The data area for CRC calculation is based on the data length (DLC) of the message DB.

The CRC shall be calculated over the entire data block (excluding the CRC bytes) including the user data, alive counter and Data ID

 

- CRC Polynomial (0x1021) , Initial Value : 0xFFFF, XOR value : 0x0000, Data ID : Message ID + 0xF800 

- The initial value is for CRC calculation and the message should be sent with the calculated result value. 

- The mathematical expression to 16 bit CRC polynomial is given here. G(x) = x16 + x12 + x5 + 1";
BA_ "GenSigStartValue" SG_ 2164278529 HTCU_Crc4Val 65535;
BA_ "UserSigValidity" SG_ 2164278529 HTCU_Crc4Val 3;
BA_ "RoutingFactor" SG_ 2164278529 HTCU_Crc4Val 5;
BA_ "Version" SG_ 2164278529 HTCU_Crc4Val "18.11.08";
BA_ "Description" SG_ 2164278529 HTCU_AlvCnt4Val "For the first transmission request for a data element the counter shall be initialized with 0 and shall be incremented by 1 for every subsequent send request. 

When the counter reaches the maximum value(0xFF), then it shall restart with 0 for the next send request";
BA_ "UserSigValidity" SG_ 2164278529 HTCU_AlvCnt4Val 3;
BA_ "RoutingFactor" SG_ 2164278529 HTCU_AlvCnt4Val 5;
BA_ "Version" SG_ 2164278529 HTCU_AlvCnt4Val "18.11.08";
BA_ "Description" SG_ 2164278529 HTCU_TrgtGearSta "HTCU_TrgtGearSta informs about the speed, which is currently engaged in the gearbox, or, in case of a gear change (HTCU_GearChgSta), which speed is reached.

Note: Gear changes covering more than one speed are also possible.

In the P and N positions, the frictional connection is interrupted hydraulically.

Depending on the type of error, the 3rd or 4th (forward) speed, and the R (reverse) speed are engaged in the limp home program.";
BA_ "UserSigValidity" SG_ 2164278529 HTCU_TrgtGearSta 3;
BA_ "RoutingFactor" SG_ 2164278529 HTCU_TrgtGearSta 5;
BA_ "Version" SG_ 2164278529 HTCU_TrgtGearSta "18.12.07";
BA_ "Description" SG_ 2164278529 HTCU_RdySta "Flag that the HTCU is ready to work. (In fact, this flag is true from the moment that CAN is working. So, normally no ¡°false¡± will be sent on CAN.) This flag does not show that everything is alright in the HTCU. This information is given in the warning and fault flags.";
BA_ "UserSigValidity" SG_ 2164278529 HTCU_RdySta 3;
BA_ "RoutingFactor" SG_ 2164278529 HTCU_RdySta 5;
BA_ "Version" SG_ 2164278529 HTCU_RdySta "18.08.02";
BA_ "Description" SG_ 2164278529 HTCU_GearChgSta "HTCU_GearChgSta indicates whether a gear change is being executed in the gearbox.

Note : Gear change means a gear shift at D-range and Garage shift(PRND).";
BA_ "UserSigValidity" SG_ 2164278529 HTCU_GearChgSta 3;
BA_ "RoutingFactor" SG_ 2164278529 HTCU_GearChgSta 5;
BA_ "Version" SG_ 2164278529 HTCU_GearChgSta "18.08.02";
BA_ "Description" SG_ 2164278529 HTCU_TqRdctnPcVal "The HTCU requests a torque reduction via the signal CR_Tcu_TqInt_Pc to the ECU and MCU.

The requested torque HTCU_TqRdctnPcVal refers to a maximum torque CR_Ems_TqStd_Nm. This conversion into a physical quantity provides a range of CR_Ems_TqStd_Nm of 0 ..199.61%.

There is no specific phase relationship between the output and any other signal.

Conversion : (PH) = 0.390625 * (HEX) [%]";
BA_ "GenSigStartValue" SG_ 2164278529 HTCU_TqRdctnPcVal 511;
BA_ "UserSigValidity" SG_ 2164278529 HTCU_TqRdctnPcVal 3;
BA_ "RoutingFactor" SG_ 2164278529 HTCU_TqRdctnPcVal 5;
BA_ "Version" SG_ 2164278529 HTCU_TqRdctnPcVal "18.08.02";
BA_ "Description" SG_ 2164278529 HTCU_FltSta "HTCU_FltSta informs about status of transmission control.



<Value Description>

Bit 0: HTCU Diagnostic failure

Bit 1: HTCU Diagnostic failure ? Limphome activated

Bit 2: OPU/EOP Diagnostic failure";
BA_ "UserSigValidity" SG_ 2164278529 HTCU_FltSta 3;
BA_ "RoutingFactor" SG_ 2164278529 HTCU_FltSta 5;
BA_ "Version" SG_ 2164278529 HTCU_FltSta "18.08.02";
BA_ "Description" SG_ 2164278529 HTCU_GearSlctrDis "Position (P, R, N..), which was identified by the gear selector.

In case the gear selector is in a intermediate position, the last clear recognized position is used.

There is no specific phase relationship between the output and any other signal.";
BA_ "GenSigStartValue" SG_ 2164278529 HTCU_GearSlctrDis 9;
BA_ "UserSigValidity" SG_ 2164278529 HTCU_GearSlctrDis 3;
BA_ "RoutingFactor" SG_ 2164278529 HTCU_GearSlctrDis 5;
BA_ "Version" SG_ 2164278529 HTCU_GearSlctrDis "18.08.02";
BA_ "Description" SG_ 2164278529 HTCU_SlwTqRdctnPcVal "The HTCU requests a slow torque reduction via the signal HTCU_TqRdctnPcVal to the ECU and MCU.";
BA_ "GenSigStartValue" SG_ 2164278529 HTCU_SlwTqRdctnPcVal 511;
BA_ "UserSigValidity" SG_ 2164278529 HTCU_SlwTqRdctnPcVal 3;
BA_ "RoutingFactor" SG_ 2164278529 HTCU_SlwTqRdctnPcVal 5;
BA_ "Version" SG_ 2164278529 HTCU_SlwTqRdctnPcVal "18.08.02";
BA_ "Description" SG_ 2164278529 HTCU_FanCtrlReq "Fan control request by OPU";
BA_ "TimeoutValue" SG_ 2164278529 HTCU_FanCtrlReq "0x0";
BA_ "UserSigValidity" SG_ 2164278529 HTCU_FanCtrlReq 3;
BA_ "RoutingFactor" SG_ 2164278529 HTCU_FanCtrlReq 5;
BA_ "Version" SG_ 2164278529 HTCU_FanCtrlReq "21.07.00";
BA_ "GenMsgSendType" BO_ 2164278530 0;
BA_ "GenMsgCycleTime" BO_ 2164278530 50;
BA_ "GenMsgCycleTimeFast" BO_ 2164278530 0;
BA_ "GenMsgNrOfRepetition" BO_ 2164278530 0;
BA_ "VFrameFormat" BO_ 2164278530 1;
BA_ "Description" SG_ 2164278530 HTCU_VehSpdKphVal "The vehicle speed calculated by HTCU is transferred.

If a vehicle has no vehicle speed sensor, no wheel speed sensor and no ABS(ESC) then it is impossible for an EMS to calculate veficle speed. In this case a HTCU should calculate vehicle speed and send to other ECUs.

The calculation can be done with output speed of gearbox, final gear ratio and fixed actual radius of a tire.";
BA_ "UserSigValidity" SG_ 2164278530 HTCU_VehSpdKphVal 3;
BA_ "RoutingFactor" SG_ 2164278530 HTCU_VehSpdKphVal 5;
BA_ "Version" SG_ 2164278530 HTCU_VehSpdKphVal "18.08.02";
BA_ "Description" SG_ 2164278530 HTCU_HvOpuSpdCmdRpmVal "CR_Tcu_OpuSpdCmd_Rpm informs about the external oil pump speed.";
BA_ "UserSigValidity" SG_ 2164278530 HTCU_HvOpuSpdCmdRpmVal 3;
BA_ "RoutingFactor" SG_ 2164278530 HTCU_HvOpuSpdCmdRpmVal 5;
BA_ "Version" SG_ 2164278530 HTCU_HvOpuSpdCmdRpmVal "17.11.00";
BA_ "UserSigValidity" SG_ 2164278530 HTCU_TrgtShftClsCCanSta 3;
BA_ "RoutingFactor" SG_ 2164278530 HTCU_TrgtShftClsCCanSta 5;
BA_ "Version" SG_ 2164278530 HTCU_TrgtShftClsCCanSta "17.11.00";
BA_ "Description" SG_ 2164278530 HTCU_CtrlablSta "This signal indicates the status of the TCU control which normally works by hydraulic pressure in the T/M";
BA_ "UserSigValidity" SG_ 2164278530 HTCU_CtrlablSta 3;
BA_ "RoutingFactor" SG_ 2164278530 HTCU_CtrlablSta 5;
BA_ "Version" SG_ 2164278530 HTCU_CtrlablSta "20.10.02";
BA_ "Description" SG_ 2164278530 HTCU_PrgrmSta "This signal informs about current program status in HTCU";
BA_ "UserSigValidity" SG_ 2164278530 HTCU_PrgrmSta 3;
BA_ "RoutingFactor" SG_ 2164278530 HTCU_PrgrmSta 5;
BA_ "Version" SG_ 2164278530 HTCU_PrgrmSta "17.11.00";
BA_ "Description" SG_ 2164278530 HTCU_FsCltchLmphmActvSta "This signal informs about engine clutch limp-home control activation";
BA_ "UserSigValidity" SG_ 2164278530 HTCU_FsCltchLmphmActvSta 3;
BA_ "RoutingFactor" SG_ 2164278530 HTCU_FsCltchLmphmActvSta 5;
BA_ "Version" SG_ 2164278530 HTCU_FsCltchLmphmActvSta "17.11.00";
BA_ "Description" SG_ 2164278530 HTCU_FsIdleTrgtRpmVal "Request idle target rpm for engine clutch limp-home control";
BA_ "UserSigValidity" SG_ 2164278530 HTCU_FsIdleTrgtRpmVal 3;
BA_ "RoutingFactor" SG_ 2164278530 HTCU_FsIdleTrgtRpmVal 5;
BA_ "Version" SG_ 2164278530 HTCU_FsIdleTrgtRpmVal "17.11.00";
BA_ "Description" SG_ 2164278530 HTCU_FsAddtnlTqLssPcVal "Additional torque loss for engine clutch limp-home control";
BA_ "UserSigValidity" SG_ 2164278530 HTCU_FsAddtnlTqLssPcVal 3;
BA_ "RoutingFactor" SG_ 2164278530 HTCU_FsAddtnlTqLssPcVal 5;
BA_ "Version" SG_ 2164278530 HTCU_FsAddtnlTqLssPcVal "17.11.00";
BA_ "Description" SG_ 2164278530 HTCU_VehSpdDcmlKphVal "The signal HTCU_VehSpdDcmlKphVal means the value which is below decimal point of the vehicle speed.

For instance, if a vehicle speed is 13.75Km/h, HTCU_VehSpdKphVal means 13Km/h and HTCU_VehSpdDcmlKphVal means 0.75Km/h.

(Min ~ Max: 0.00 ~ 0.99)";
BA_ "UserSigValidity" SG_ 2164278530 HTCU_VehSpdDcmlKphVal 3;
BA_ "RoutingFactor" SG_ 2164278530 HTCU_VehSpdDcmlKphVal 5;
BA_ "Version" SG_ 2164278530 HTCU_VehSpdDcmlKphVal "18.12.07";
BA_ "GenMsgSendType" BO_ 2164278531 0;
BA_ "GenMsgCycleTime" BO_ 2164278531 50;
BA_ "GenMsgCycleTimeFast" BO_ 2164278531 0;
BA_ "GenMsgNrOfRepetition" BO_ 2164278531 0;
BA_ "VFrameFormat" BO_ 2164278531 1;
BA_ "Description" SG_ 2164278531 HTCU_FsEngTqRdctnPcVal "This signal informs about engine torque reduction request for engine clutch limp-home control";
BA_ "GenSigStartValue" SG_ 2164278531 HTCU_FsEngTqRdctnPcVal 255;
BA_ "UserSigValidity" SG_ 2164278531 HTCU_FsEngTqRdctnPcVal 3;
BA_ "RoutingFactor" SG_ 2164278531 HTCU_FsEngTqRdctnPcVal 5;
BA_ "Version" SG_ 2164278531 HTCU_FsEngTqRdctnPcVal "19.02.06";
BA_ "Description" SG_ 2164278531 HTCU_RapidKDReq "Rapid K/D Shift Request";
BA_ "UserSigValidity" SG_ 2164278531 HTCU_RapidKDReq 3;
BA_ "RoutingFactor" SG_ 2164278531 HTCU_RapidKDReq 5;
BA_ "Version" SG_ 2164278531 HTCU_RapidKDReq "17.11.00";
BA_ "UserSigValidity" SG_ 2164278531 HTCU_CurrGearSta 3;
BA_ "RoutingFactor" SG_ 2164278531 HTCU_CurrGearSta 5;
BA_ "Version" SG_ 2164278531 HTCU_CurrGearSta "18.12.07";
BA_ "Description" SG_ 2164278531 HTCU_GearShftUpDisGSI "Gear Shift-up display status for Gear shift indicator (EU Regulations)";
BA_ "UserSigValidity" SG_ 2164278531 HTCU_GearShftUpDisGSI 3;
BA_ "RoutingFactor" SG_ 2164278531 HTCU_GearShftUpDisGSI 5;
BA_ "Version" SG_ 2164278531 HTCU_GearShftUpDisGSI "18.08.01";
BA_ "Description" SG_ 2164278531 HTCU_GearShftDnDisGSI "Gear Shift-down display status for Gear shift indicator (EU Regulations)";
BA_ "UserSigValidity" SG_ 2164278531 HTCU_GearShftDnDisGSI 3;
BA_ "RoutingFactor" SG_ 2164278531 HTCU_GearShftDnDisGSI 5;
BA_ "Version" SG_ 2164278531 HTCU_GearShftDnDisGSI "18.08.01";
BA_ "Description" SG_ 2164278531 HTCU_TrgtGearStaGSI "Target Gear for Gear shift indicator (EU Regulations)";
BA_ "UserSigValidity" SG_ 2164278531 HTCU_TrgtGearStaGSI 3;
BA_ "RoutingFactor" SG_ 2164278531 HTCU_TrgtGearStaGSI 5;
BA_ "Version" SG_ 2164278531 HTCU_TrgtGearStaGSI "19.02.06";
BA_ "Description" SG_ 2164278531 HTCU_SolBSta "Status of On/Off Solenoid B";
BA_ "UserSigValidity" SG_ 2164278531 HTCU_SolBSta 3;
BA_ "RoutingFactor" SG_ 2164278531 HTCU_SolBSta 5;
BA_ "Version" SG_ 2164278531 HTCU_SolBSta "18.08.01";
BA_ "Description" SG_ 2164278531 HTCU_LnPrsBarVal "This signal informs about the Transmission valve body line pressure command from HTCU";
BA_ "UserSigValidity" SG_ 2164278531 HTCU_LnPrsBarVal 3;
BA_ "RoutingFactor" SG_ 2164278531 HTCU_LnPrsBarVal 5;
BA_ "Version" SG_ 2164278531 HTCU_LnPrsBarVal "17.11.00";
BA_ "GenMsgSendType" BO_ 2281833730 0;
BA_ "GenMsgCycleTimeFast" BO_ 2281833730 0;
BA_ "GenMsgNrOfRepetition" BO_ 2281833730 0;
BA_ "VFrameFormat" BO_ 2281833730 1;
BA_ "Description" SG_ 2281833730 DMIC_EcsModSta "This Signal is the request on mode transition for Controlling the Driving Mode.";
BA_ "UserSigValidity" SG_ 2281833730 DMIC_EcsModSta 3;
BA_ "RoutingFactor" SG_ 2281833730 DMIC_EcsModSta 2;
BA_ "Version" SG_ 2281833730 DMIC_EcsModSta "20.05.02";
BA_ "Description" SG_ 2281833730 DMIC_IndAwdModSta "This signal is for feedback about individual mode setting on AVN.";
BA_ "UserSigValidity" SG_ 2281833730 DMIC_IndAwdModSta 3;
BA_ "RoutingFactor" SG_ 2281833730 DMIC_IndAwdModSta 2;
BA_ "Version" SG_ 2281833730 DMIC_IndAwdModSta "17.12.00";
BA_ "Description" SG_ 2281833730 DMIC_RevModSta "This Signal is the request on mode transition for Controlling the Driving Mode.";
BA_ "UserSigValidity" SG_ 2281833730 DMIC_RevModSta 3;
BA_ "RoutingFactor" SG_ 2281833730 DMIC_RevModSta 2;
BA_ "Version" SG_ 2281833730 DMIC_RevModSta "20.05.02";
BA_ "Description" SG_ 2281833730 DMIC_IndRevModSta "This signal is for feedback about individual mode setting on AVN.";
BA_ "UserSigValidity" SG_ 2281833730 DMIC_IndRevModSta 3;
BA_ "RoutingFactor" SG_ 2281833730 DMIC_IndRevModSta 2;
BA_ "Version" SG_ 2281833730 DMIC_IndRevModSta "17.12.00";
BA_ "Description" SG_ 2281833730 DMIC_PrflModSta "This Signal is the request on mode transition for Controlling the Driving Mode.";
BA_ "UserSigValidity" SG_ 2281833730 DMIC_PrflModSta 3;
BA_ "RoutingFactor" SG_ 2281833730 DMIC_PrflModSta 2;
BA_ "Version" SG_ 2281833730 DMIC_PrflModSta "17.12.00";
BA_ "Description" SG_ 2281833730 DMIC_IndPrflModSta "This signal is for feedback about individual mode setting on AVN.";
BA_ "UserSigValidity" SG_ 2281833730 DMIC_IndPrflModSta 3;
BA_ "RoutingFactor" SG_ 2281833730 DMIC_IndPrflModSta 2;
BA_ "Version" SG_ 2281833730 DMIC_IndPrflModSta "17.12.00";
BA_ "Description" SG_ 2281833730 DMIC_ElsdModSta "This Signal is the request on mode transition for Controlling the Driving Mode.";
BA_ "UserSigValidity" SG_ 2281833730 DMIC_ElsdModSta 3;
BA_ "RoutingFactor" SG_ 2281833730 DMIC_ElsdModSta 2;
BA_ "Version" SG_ 2281833730 DMIC_ElsdModSta "20.05.02";
BA_ "Description" SG_ 2281833730 DMIC_IndElsdModSta "This signal is for feedback about individual mode setting on AVN.";
BA_ "UserSigValidity" SG_ 2281833730 DMIC_IndElsdModSta 3;
BA_ "RoutingFactor" SG_ 2281833730 DMIC_IndElsdModSta 2;
BA_ "Version" SG_ 2281833730 DMIC_IndElsdModSta "17.12.00";
BA_ "Description" SG_ 2281833730 DMIC_IndEcsModSta "This signal is for feedback about individual mode setting on AVN.";
BA_ "UserSigValidity" SG_ 2281833730 DMIC_IndEcsModSta 3;
BA_ "RoutingFactor" SG_ 2281833730 DMIC_IndEcsModSta 2;
BA_ "Version" SG_ 2281833730 DMIC_IndEcsModSta "19.09.00";
BA_ "Description" SG_ 2281833730 DMIC_EsndModSta "This Signal is the request on mode transition for Controlling the Driving Mode.";
BA_ "UserSigValidity" SG_ 2281833730 DMIC_EsndModSta 3;
BA_ "RoutingFactor" SG_ 2281833730 DMIC_EsndModSta 2;
BA_ "Version" SG_ 2281833730 DMIC_EsndModSta "20.05.02";
BA_ "Description" SG_ 2281833730 DMIC_IndEsndModSta "This signal is for feedback about individual mode setting on AVN.";
BA_ "UserSigValidity" SG_ 2281833730 DMIC_IndEsndModSta 3;
BA_ "RoutingFactor" SG_ 2281833730 DMIC_IndEsndModSta 2;
BA_ "Version" SG_ 2281833730 DMIC_IndEsndModSta "17.12.00";
BA_ "Description" SG_ 2281833730 DMIC_RwsModSta "This Signal is the request on mode transition for Controlling the Driving Mode.";
BA_ "UserSigValidity" SG_ 2281833730 DMIC_RwsModSta 3;
BA_ "RoutingFactor" SG_ 2281833730 DMIC_RwsModSta 2;
BA_ "Version" SG_ 2281833730 DMIC_RwsModSta "20.05.02";
BA_ "Description" SG_ 2281833730 DMIC_IndRwsModSta "This signal is for feedback about individual mode setting on AVN.";
BA_ "UserSigValidity" SG_ 2281833730 DMIC_IndRwsModSta 3;
BA_ "RoutingFactor" SG_ 2281833730 DMIC_IndRwsModSta 2;
BA_ "Version" SG_ 2281833730 DMIC_IndRwsModSta "17.11.00";
BA_ "Description" SG_ 2281833730 DMIC_AwdModSta "This Signal is the request on mode transition for Controlling the Driving Mode.";
BA_ "UserSigValidity" SG_ 2281833730 DMIC_AwdModSta 3;
BA_ "RoutingFactor" SG_ 2281833730 DMIC_AwdModSta 2;
BA_ "Version" SG_ 2281833730 DMIC_AwdModSta "20.05.02";
BA_ "GenMsgSendType" BO_ 579 0;
BA_ "Description" SG_ 579 OHCL_Opt "This signal is OHCL(OverHead Console Lamp)  ECU Option state";
BA_ "GenSigSendType" SG_ 579 OHCL_Opt 4;
BA_ "TimeoutValue" SG_ 579 OHCL_Opt "Old Value";
BA_ "UserSigValidity" SG_ 579 OHCL_Opt 3;
BA_REL_ "GenSigTimeoutTime" BU_SG_REL_ ATS SG_ 579 OHCL_Opt 1000;
BA_ "Version" SG_ 579 OHCL_Opt "19.12.01";
BA_ "Description" SG_ 579 OHCL_Sys_sta "This signal is OHCL (OverHead Console Lamp) system state";
BA_ "GenSigSendType" SG_ 579 OHCL_Sys_sta 4;
BA_ "TimeoutValue" SG_ 579 OHCL_Sys_sta "0x3";
BA_ "UserSigValidity" SG_ 579 OHCL_Sys_sta 3;
BA_REL_ "GenSigTimeoutTime" BU_SG_REL_ ATS SG_ 579 OHCL_Sys_sta 1000;
BA_ "Version" SG_ 579 OHCL_Sys_sta "19.12.01";
BA_ "Description" SG_ 579 OHCL_DoorOn_Sta "This signal is door lamp switch On/Off status";
BA_ "GenSigSendType" SG_ 579 OHCL_DoorOn_Sta 4;
BA_ "TimeoutValue" SG_ 579 OHCL_DoorOn_Sta "Old Value";
BA_ "UserSigValidity" SG_ 579 OHCL_DoorOn_Sta 3;
BA_REL_ "GenSigTimeoutTime" BU_SG_REL_ ATS SG_ 579 OHCL_DoorOn_Sta 1000;
BA_ "Version" SG_ 579 OHCL_DoorOn_Sta "19.12.01";
BA_ "Description" SG_ 579 OHCL_RrMapLftOn_Sta "This signal is rear left map lamp On/Off status";
BA_ "GenSigSendType" SG_ 579 OHCL_RrMapLftOn_Sta 4;
BA_ "TimeoutValue" SG_ 579 OHCL_RrMapLftOn_Sta "Old Value";
BA_ "UserSigValidity" SG_ 579 OHCL_RrMapLftOn_Sta 3;
BA_REL_ "GenSigTimeoutTime" BU_SG_REL_ ATS SG_ 579 OHCL_RrMapLftOn_Sta 1000;
BA_ "Version" SG_ 579 OHCL_RrMapLftOn_Sta "19.12.01";
BA_ "Description" SG_ 579 OHCL_RrMapRtOn_Sta "This signal is rear right map lamp On/Off status";
BA_ "GenSigSendType" SG_ 579 OHCL_RrMapRtOn_Sta 4;
BA_ "TimeoutValue" SG_ 579 OHCL_RrMapRtOn_Sta "Old Value";
BA_ "UserSigValidity" SG_ 579 OHCL_RrMapRtOn_Sta 3;
BA_REL_ "GenSigTimeoutTime" BU_SG_REL_ ATS SG_ 579 OHCL_RrMapRtOn_Sta 1000;
BA_ "Version" SG_ 579 OHCL_RrMapRtOn_Sta "19.12.01";
BA_ "Description" SG_ 579 OHCL_RrRoomOn_Sta "This signal is rear room map lamp On/Off status ( all )";
BA_ "GenSigSendType" SG_ 579 OHCL_RrRoomOn_Sta 4;
BA_ "TimeoutValue" SG_ 579 OHCL_RrRoomOn_Sta "Old Value";
BA_ "UserSigValidity" SG_ 579 OHCL_RrRoomOn_Sta 3;
BA_REL_ "GenSigTimeoutTime" BU_SG_REL_ ATS SG_ 579 OHCL_RrRoomOn_Sta 1000;
BA_ "Version" SG_ 579 OHCL_RrRoomOn_Sta "19.12.01";
BA_ "Description" SG_ 579 OHCL_RrMoodOn_Sta "This signal is rear mood map lamp On/Off status";
BA_ "GenSigSendType" SG_ 579 OHCL_RrMoodOn_Sta 4;
BA_ "TimeoutValue" SG_ 579 OHCL_RrMoodOn_Sta "Old Value";
BA_ "UserSigValidity" SG_ 579 OHCL_RrMoodOn_Sta 3;
BA_REL_ "GenSigTimeoutTime" BU_SG_REL_ ATS SG_ 579 OHCL_RrMoodOn_Sta 1000;
BA_ "Version" SG_ 579 OHCL_RrMoodOn_Sta "19.12.01";
BA_ "Description" SG_ 579 OHCL_LEDClr_Sta "This signal is interior lamps lighting color status";
BA_ "GenSigSendType" SG_ 579 OHCL_LEDClr_Sta 4;
BA_ "TimeoutValue" SG_ 579 OHCL_LEDClr_Sta "Old Value";
BA_ "UserSigValidity" SG_ 579 OHCL_LEDClr_Sta 3;
BA_REL_ "GenSigTimeoutTime" BU_SG_REL_ ATS SG_ 579 OHCL_LEDClr_Sta 1000;
BA_ "Version" SG_ 579 OHCL_LEDClr_Sta "19.12.01";
BA_ "Description" SG_ 579 OHCL_LEDBgtns_Sta "This signal is interior lamps brightness status";
BA_ "GenSigSendType" SG_ 579 OHCL_LEDBgtns_Sta 4;
BA_ "TimeoutValue" SG_ 579 OHCL_LEDBgtns_Sta "Old Value";
BA_ "UserSigValidity" SG_ 579 OHCL_LEDBgtns_Sta 3;
BA_REL_ "GenSigTimeoutTime" BU_SG_REL_ ATS SG_ 579 OHCL_LEDBgtns_Sta 1000;
BA_ "Version" SG_ 579 OHCL_LEDBgtns_Sta "19.12.01";
BA_ "Description" SG_ 579 OHCL_TllTlLmpSta "This signal is PAB tell tale lamp status signal

( ACU_TllTlLmpDis feedback signal )";
BA_ "GenSigSendType" SG_ 579 OHCL_TllTlLmpSta 4;
BA_ "GenSigStartValue" SG_ 579 OHCL_TllTlLmpSta 3;
BA_ "UserSigValidity" SG_ 579 OHCL_TllTlLmpSta 3;
BA_REL_ "GenSigTimeoutTime" BU_SG_REL_ CGW_CCU SG_ 579 OHCL_TllTlLmpSta 1000;
BA_ "Version" SG_ 579 OHCL_TllTlLmpSta "20.10.00";
BA_ "Description" SG_ 579 OHCL_FrMapLftOn_Sta "This signal is front left map lamp On/Off status";
BA_ "GenSigSendType" SG_ 579 OHCL_FrMapLftOn_Sta 4;
BA_ "TimeoutValue" SG_ 579 OHCL_FrMapLftOn_Sta "0x0";
BA_ "UserSigValidity" SG_ 579 OHCL_FrMapLftOn_Sta 3;
BA_REL_ "GenSigTimeoutTime" BU_SG_REL_ ATS SG_ 579 OHCL_FrMapLftOn_Sta 1000;
BA_ "Version" SG_ 579 OHCL_FrMapLftOn_Sta "19.12.01";
BA_ "Description" SG_ 579 OHCL_RrCurtainReq "This signal is Rear curtain switch On/Off signal

( The signal send 'On' during push switch only )";
BA_ "GenSigSendType" SG_ 579 OHCL_RrCurtainReq 4;
BA_ "UserSigValidity" SG_ 579 OHCL_RrCurtainReq 3;
BA_ "Version" SG_ 579 OHCL_RrCurtainReq "20.01.01";
BA_ "Description" SG_ 579 OHCL_FrMapRtOn_Sta "This signal is front right map lamp On/Off status";
BA_ "GenSigSendType" SG_ 579 OHCL_FrMapRtOn_Sta 4;
BA_ "TimeoutValue" SG_ 579 OHCL_FrMapRtOn_Sta "Old Value";
BA_ "UserSigValidity" SG_ 579 OHCL_FrMapRtOn_Sta 3;
BA_REL_ "GenSigTimeoutTime" BU_SG_REL_ ATS SG_ 579 OHCL_FrMapRtOn_Sta 1000;
BA_ "Version" SG_ 579 OHCL_FrMapRtOn_Sta "19.12.01";
BA_ "Description" SG_ 579 OHCL_FrRoomOn_Sta "This signal is front room lamp On/Off status ( all )";
BA_ "GenSigSendType" SG_ 579 OHCL_FrRoomOn_Sta 4;
BA_ "TimeoutValue" SG_ 579 OHCL_FrRoomOn_Sta "Old Value";
BA_ "UserSigValidity" SG_ 579 OHCL_FrRoomOn_Sta 3;
BA_REL_ "GenSigTimeoutTime" BU_SG_REL_ ATS SG_ 579 OHCL_FrRoomOn_Sta 1000;
BA_ "Version" SG_ 579 OHCL_FrRoomOn_Sta "19.12.01";
BA_ "Description" SG_ 579 OHCL_FrMoodOn_Sta "This signal is front mood map lamp On/Off status";
BA_ "GenSigSendType" SG_ 579 OHCL_FrMoodOn_Sta 4;
BA_ "UserSigValidity" SG_ 579 OHCL_FrMoodOn_Sta 3;
BA_REL_ "GenSigTimeoutTime" BU_SG_REL_ ATS SG_ 579 OHCL_FrMoodOn_Sta 1000;
BA_ "Version" SG_ 579 OHCL_FrMoodOn_Sta "19.12.01";
BA_ "GenMsgSendType" BO_ 1059 0;
BA_ "Description" SG_ 1059 PSU_DiagSta "(Old)C_PSU_DiagState";
BA_ "GenSigSendType" SG_ 1059 PSU_DiagSta 4;
BA_ "UserSigValidity" SG_ 1059 PSU_DiagSta 0;
BA_ "NetworkRequest" SG_ 1059 PSU_DiagSta 0;
BA_ "NetworkRequestHoldingTime" SG_ 1059 PSU_DiagSta 5000;
BA_ "Version" SG_ 1059 PSU_DiagSta "21.07.06";
BA_ "Description" SG_ 1059 Ast_2ndAutoRlxEnable "µ¿½Â¼® ½ÃÆ® À§Ä¡¿¡ µû¸¥ 2¿­ ¸±·º¼Ç µ¿ÀÛ °¡´É¿©ºÎ ÆÇ´Ü ½ÅÈ£";
BA_ "GenSigSendType" SG_ 1059 Ast_2ndAutoRlxEnable 4;
BA_ "UserSigValidity" SG_ 1059 Ast_2ndAutoRlxEnable 0;
BA_REL_ "GenSigTimeoutTime" BU_SG_REL_ RLPSU SG_ 1059 Ast_2ndAutoRlxEnable 1500;
BA_REL_ "GenSigTimeoutTime" BU_SG_REL_ RRPSU SG_ 1059 Ast_2ndAutoRlxEnable 1500;
BA_ "NetworkRequest" SG_ 1059 Ast_2ndAutoRlxEnable 0;
BA_ "NetworkRequestHoldingTime" SG_ 1059 Ast_2ndAutoRlxEnable 5000;
BA_ "Version" SG_ 1059 Ast_2ndAutoRlxEnable "21.06.10";
BA_ "Description" SG_ 1059 Ast_AutoRlxSta "µ¿½Â¼® ½ÃÆ® ¿ÀÅä ¸±·º¼Ç µ¿ÀÛ »óÅÂ Á¤º¸";
BA_ "GenSigSendType" SG_ 1059 Ast_AutoRlxSta 4;
BA_ "UserSigValidity" SG_ 1059 Ast_AutoRlxSta 0;
BA_REL_ "GenSigTimeoutTime" BU_SG_REL_ RLPSU SG_ 1059 Ast_AutoRlxSta 1500;
BA_REL_ "GenSigTimeoutTime" BU_SG_REL_ RRPSU SG_ 1059 Ast_AutoRlxSta 1500;
BA_ "NetworkRequest" SG_ 1059 Ast_AutoRlxSta 0;
BA_ "NetworkRequestHoldingTime" SG_ 1059 Ast_AutoRlxSta 5000;
BA_ "Version" SG_ 1059 Ast_AutoRlxSta "21.07.06";
BA_ "Description" SG_ 1059 PSU_EsyAcsGetOnSta "Easy Access Get On Information";
BA_ "GenSigSendType" SG_ 1059 PSU_EsyAcsGetOnSta 4;
BA_ "UserSigValidity" SG_ 1059 PSU_EsyAcsGetOnSta 0;
BA_REL_ "GenSigTimeoutTime" BU_SG_REL_ SLB SG_ 1059 PSU_EsyAcsGetOnSta 1500;
BA_ "NetworkRequest" SG_ 1059 PSU_EsyAcsGetOnSta 0;
BA_ "NetworkRequestHoldingTime" SG_ 1059 PSU_EsyAcsGetOnSta 5000;
BA_ "Version" SG_ 1059 PSU_EsyAcsGetOnSta "21.07.06";
BA_ "Description" SG_ 1059 PSU_EsyAcsGetOffSta "Easy Access Get Off Information";
BA_ "GenSigSendType" SG_ 1059 PSU_EsyAcsGetOffSta 4;
BA_ "UserSigValidity" SG_ 1059 PSU_EsyAcsGetOffSta 0;
BA_REL_ "GenSigTimeoutTime" BU_SG_REL_ SLB SG_ 1059 PSU_EsyAcsGetOffSta 1500;
BA_ "NetworkRequest" SG_ 1059 PSU_EsyAcsGetOffSta 0;
BA_ "NetworkRequestHoldingTime" SG_ 1059 PSU_EsyAcsGetOffSta 5000;
BA_ "Version" SG_ 1059 PSU_EsyAcsGetOffSta "21.07.06";
BA_ "Description" SG_ 1059 PSU_EsyAcsStpSta "Easy Access Stop Information";
BA_ "GenSigSendType" SG_ 1059 PSU_EsyAcsStpSta 4;
BA_ "UserSigValidity" SG_ 1059 PSU_EsyAcsStpSta 0;
BA_REL_ "GenSigTimeoutTime" BU_SG_REL_ SLB SG_ 1059 PSU_EsyAcsStpSta 1500;
BA_ "NetworkRequest" SG_ 1059 PSU_EsyAcsStpSta 0;
BA_ "NetworkRequestHoldingTime" SG_ 1059 PSU_EsyAcsStpSta 5000;
BA_ "Version" SG_ 1059 PSU_EsyAcsStpSta "21.07.06";
BA_ "GenSigSendType" SG_ 1059 PSU_RVal 4;
BA_ "UserSigValidity" SG_ 1059 PSU_RVal 0;
BA_ "NetworkRequest" SG_ 1059 PSU_RVal 0;
BA_ "NetworkRequestHoldingTime" SG_ 1059 PSU_RVal 5000;
BA_ "Version" SG_ 1059 PSU_RVal "21.07.06";
BA_ "GenMsgSendType" BO_ 1086 0;
BA_ "Description" SG_ 1086 RL_CURTAIN_POSITION "2¿­ ÁÂÃø À©µµ¿ì ±Û¶ó½º Ä¿Æ° À§Ä¡ Á¤º¸";
BA_ "GenSigSendType" SG_ 1086 RL_CURTAIN_POSITION 4;
BA_ "UserSigValidity" SG_ 1086 RL_CURTAIN_POSITION 0;
BA_REL_ "GenSigTimeoutTime" BU_SG_REL_ ATS SG_ 1086 RL_CURTAIN_POSITION 1500;
BA_ "NetworkRequest" SG_ 1086 RL_CURTAIN_POSITION 0;
BA_ "NetworkRequestHoldingTime" SG_ 1086 RL_CURTAIN_POSITION 5000;
BA_ "Version" SG_ 1086 RL_CURTAIN_POSITION "18.03.07";
BA_ "Description" SG_ 1086 RDC_SWVerMinor1 "Indicate the RDC software version as follows:

- The software version is displayed in three digits.

- The Major and Minor digits are separated by '.'

- Signal values are transmitted to ASCII codes.



¡Ø Example

RDC_SWVerMajor1 : 0x41 (HEX) -> ASCII CODE : 'A' 

RDC_SWVerMinor1 : 0x30 (HEX) -> ASCII CODE : '0'

RDC_SWVerMinor2 : 0x33 (HEX) -> ASCII CODE : '3'

=> RDC S/W Ver is displayed 'A.03'";
BA_ "GenSigSendType" SG_ 1086 RDC_SWVerMinor1 4;
BA_ "UserSigValidity" SG_ 1086 RDC_SWVerMinor1 0;
BA_ "Version" SG_ 1086 RDC_SWVerMinor1 "18.10.06";
BA_ "Description" SG_ 1086 RDC_SWVerMinor2 "Indicate the RDC software version as follows:

- The software version is displayed in three digits.

- The Major and Minor digits are separated by '.'

- Signal values are transmitted to ASCII codes.



¡Ø Example

RDC_SWVerMajor1 : 0x41 (HEX) -> ASCII CODE : 'A' 

RDC_SWVerMinor1 : 0x30 (HEX) -> ASCII CODE : '0'

RDC_SWVerMinor2 : 0x33 (HEX) -> ASCII CODE : '3'

=> RDC S/W Ver is displayed 'A.03'";
BA_ "GenSigSendType" SG_ 1086 RDC_SWVerMinor2 4;
BA_ "UserSigValidity" SG_ 1086 RDC_SWVerMinor2 0;
BA_ "Version" SG_ 1086 RDC_SWVerMinor2 "18.10.06";
BA_ "Description" SG_ 1086 RR_CURTAIN_POSITION "2¿­ ¿ìÃø À©µµ¿ì ±Û¶ó½º Ä¿Æ° À§Ä¡ Á¤º¸";
BA_ "GenSigSendType" SG_ 1086 RR_CURTAIN_POSITION 4;
BA_ "UserSigValidity" SG_ 1086 RR_CURTAIN_POSITION 0;
BA_REL_ "GenSigTimeoutTime" BU_SG_REL_ ATS SG_ 1086 RR_CURTAIN_POSITION 1500;
BA_ "NetworkRequest" SG_ 1086 RR_CURTAIN_POSITION 0;
BA_ "NetworkRequestHoldingTime" SG_ 1086 RR_CURTAIN_POSITION 5000;
BA_ "Version" SG_ 1086 RR_CURTAIN_POSITION "18.03.07";
BA_ "Description" SG_ 1086 RDC_RLDNInitFlag "Rear Left Door Curtain Down Initialized Finish Flag";
BA_ "GenSigSendType" SG_ 1086 RDC_RLDNInitFlag 4;
BA_ "UserSigValidity" SG_ 1086 RDC_RLDNInitFlag 0;
BA_ "NetworkRequest" SG_ 1086 RDC_RLDNInitFlag 0;
BA_ "NetworkRequestHoldingTime" SG_ 1086 RDC_RLDNInitFlag 5000;
BA_ "Version" SG_ 1086 RDC_RLDNInitFlag "21.01.08";
BA_ "Description" SG_ 1086 RDC_RRDNInitFlag "Rear Right Door Curtain Down Initialized Finish Flag";
BA_ "GenSigSendType" SG_ 1086 RDC_RRDNInitFlag 4;
BA_ "UserSigValidity" SG_ 1086 RDC_RRDNInitFlag 0;
BA_ "NetworkRequest" SG_ 1086 RDC_RRDNInitFlag 0;
BA_ "NetworkRequestHoldingTime" SG_ 1086 RDC_RRDNInitFlag 5000;
BA_ "Version" SG_ 1086 RDC_RRDNInitFlag "21.01.08";
BA_ "Description" SG_ 1086 RDC_RLOpState "Rear Left Door Curtain Operating State Feedback";
BA_ "GenSigSendType" SG_ 1086 RDC_RLOpState 4;
BA_ "UserSigValidity" SG_ 1086 RDC_RLOpState 0;
BA_ "NetworkRequest" SG_ 1086 RDC_RLOpState 0;
BA_ "NetworkRequestHoldingTime" SG_ 1086 RDC_RLOpState 5000;
BA_ "Version" SG_ 1086 RDC_RLOpState "21.01.08";
BA_ "Description" SG_ 1086 RDC_RROpState "Rear Right Door Curtain Operating State Feedback";
BA_ "GenSigSendType" SG_ 1086 RDC_RROpState 4;
BA_ "UserSigValidity" SG_ 1086 RDC_RROpState 0;
BA_ "NetworkRequest" SG_ 1086 RDC_RROpState 0;
BA_ "NetworkRequestHoldingTime" SG_ 1086 RDC_RROpState 5000;
BA_ "Version" SG_ 1086 RDC_RROpState "21.01.08";
BA_ "Description" SG_ 1086 RDC_OptTyp "RDC OPTION SIGNAL";
BA_ "GenSigSendType" SG_ 1086 RDC_OptTyp 4;
BA_ "UserSigValidity" SG_ 1086 RDC_OptTyp 0;
BA_REL_ "GenSigTimeoutTime" BU_SG_REL_ ATS SG_ 1086 RDC_OptTyp 1500;
BA_ "NetworkRequest" SG_ 1086 RDC_OptTyp 0;
BA_ "NetworkRequestHoldingTime" SG_ 1086 RDC_OptTyp 5000;
BA_ "Version" SG_ 1086 RDC_OptTyp "20.01.01";
BA_ "Description" SG_ 1086 RDC_SWVerMajor1 "Indicate the RDC software version as follows:

- The software version is displayed in three digits.

- The Major and Minor digits are separated by '.'

- Signal values are transmitted to ASCII codes.



¡Ø Example

RDC_SWVerMajor1 : 0x41 (HEX) -> ASCII CODE : 'A' 

RDC_SWVerMinor1 : 0x30 (HEX) -> ASCII CODE : '0'

RDC_SWVerMinor2 : 0x33 (HEX) -> ASCII CODE : '3'

=> RDC S/W Ver is displayed 'A.03'";
BA_ "GenSigSendType" SG_ 1086 RDC_SWVerMajor1 4;
BA_ "UserSigValidity" SG_ 1086 RDC_SWVerMajor1 0;
BA_ "Version" SG_ 1086 RDC_SWVerMajor1 "18.10.06";
BA_ "GenMsgSendType" BO_ 1068 0;
BA_ "Description" SG_ 1068 RLPSU_ReclMtrPos "2¿­ LH ½ÃÆ® Recline ¸ðÅÍ À§Ä¡°ª ¼Û½Å

 - Seat Recline Position Information signal for 2nd LH seat";
BA_ "GenSigSendType" SG_ 1068 RLPSU_ReclMtrPos 4;
BA_ "UserSigValidity" SG_ 1068 RLPSU_ReclMtrPos 0;
BA_REL_ "GenSigTimeoutTime" BU_SG_REL_ PFSU SG_ 1068 RLPSU_ReclMtrPos 1500;
BA_REL_ "GenSigTimeoutTime" BU_SG_REL_ CGW_CCU SG_ 1068 RLPSU_ReclMtrPos 1500;
BA_ "NetworkRequest" SG_ 1068 RLPSU_ReclMtrPos 0;
BA_ "NetworkRequestHoldingTime" SG_ 1068 RLPSU_ReclMtrPos 5000;
BA_ "Version" SG_ 1068 RLPSU_ReclMtrPos "21.07.06";
BA_ "Description" SG_ 1068 RLPSU_RLSlidPos "2nd Left Seat Slide Position Information for button activatation / unactivation";
BA_ "GenSigSendType" SG_ 1068 RLPSU_RLSlidPos 4;
BA_ "UserSigValidity" SG_ 1068 RLPSU_RLSlidPos 0;
BA_REL_ "GenSigTimeoutTime" BU_SG_REL_ CGW_CCU SG_ 1068 RLPSU_RLSlidPos 1500;
BA_ "Version" SG_ 1068 RLPSU_RLSlidPos "21.07.06";
BA_ "Description" SG_ 1068 RLPSU_RLRclPos "2¿­ ÁÂÃø ½ÃÆ® ¹é ¸®Å¬¶óÀÌ´× À§Ä¡¿¡ µû¸¥ ¹öÆ° È°¼ºÈ­ / ºñÈ°¼ºÈ­";
BA_ "GenSigSendType" SG_ 1068 RLPSU_RLRclPos 4;
BA_ "UserSigValidity" SG_ 1068 RLPSU_RLRclPos 0;
BA_REL_ "GenSigTimeoutTime" BU_SG_REL_ CGW_CCU SG_ 1068 RLPSU_RLRclPos 1500;
BA_ "Version" SG_ 1068 RLPSU_RLRclPos "21.07.06";
BA_ "Description" SG_ 1068 RLPSU_RLTiltPos "2¿­ ÁÂÃø ½ÃÆ® Äí¼Ç Æ¿Æ® À§Ä¡¿¡ µû¸¥ ¹öÆ° È°¼ºÈ­ / ºñÈ°¼ºÈ­";
BA_ "GenSigSendType" SG_ 1068 RLPSU_RLTiltPos 4;
BA_ "UserSigValidity" SG_ 1068 RLPSU_RLTiltPos 0;
BA_REL_ "GenSigTimeoutTime" BU_SG_REL_ CGW_CCU SG_ 1068 RLPSU_RLTiltPos 1500;
BA_ "Version" SG_ 1068 RLPSU_RLTiltPos "21.07.06";
BA_ "Description" SG_ 1068 RLPSU_RLLegExtPos "2¿­ ÁÂÃø ½ÃÆ® ·¹±×·¹½ºÆ® ÀÍ½ºÅÙ¼Ç À§Ä¡¿¡ µû¸¥ ¹öÆ° È°¼ºÈ­ / ºñÈ°¼ºÈ­";
BA_ "GenSigSendType" SG_ 1068 RLPSU_RLLegExtPos 4;
BA_ "UserSigValidity" SG_ 1068 RLPSU_RLLegExtPos 0;
BA_REL_ "GenSigTimeoutTime" BU_SG_REL_ CGW_CCU SG_ 1068 RLPSU_RLLegExtPos 1500;
BA_ "Version" SG_ 1068 RLPSU_RLLegExtPos "21.07.06";
BA_ "Description" SG_ 1068 RLPSU_RLLegSupPos "2¿­ ÁÂÃø ½ÃÆ® ·¹±×¼­Æ÷Æ® À§Ä¡¿¡ µû¸¥ ¹öÆ° È°¼ºÈ­ / ºñÈ°¼ºÈ­";
BA_ "GenSigSendType" SG_ 1068 RLPSU_RLLegSupPos 4;
BA_ "UserSigValidity" SG_ 1068 RLPSU_RLLegSupPos 0;
BA_REL_ "GenSigTimeoutTime" BU_SG_REL_ CGW_CCU SG_ 1068 RLPSU_RLLegSupPos 1500;
BA_ "Version" SG_ 1068 RLPSU_RLLegSupPos "21.07.06";
BA_ "Description" SG_ 1068 RLPSU_RLHrestSlidPos "2nd Left Seat Head Rest Slide Position Information for button activatation / unactivation";
BA_ "GenSigSendType" SG_ 1068 RLPSU_RLHrestSlidPos 4;
BA_ "UserSigValidity" SG_ 1068 RLPSU_RLHrestSlidPos 0;
BA_REL_ "GenSigTimeoutTime" BU_SG_REL_ CGW_CCU SG_ 1068 RLPSU_RLHrestSlidPos 1500;
BA_ "Version" SG_ 1068 RLPSU_RLHrestSlidPos "21.07.06";
BA_ "Description" SG_ 1068 RLPSU_RLHrestHeightPos "2¿­ ÁÂÃø ½ÃÆ® Çìµå·¹½ºÆ® ÇÏÀÌÆ® À§Ä¡¿¡ µû¸¥ ¹öÆ° È°¼ºÈ­ / ºñÈ°¼ºÈ­";
BA_ "GenSigSendType" SG_ 1068 RLPSU_RLHrestHeightPos 4;
BA_ "UserSigValidity" SG_ 1068 RLPSU_RLHrestHeightPos 0;
BA_REL_ "GenSigTimeoutTime" BU_SG_REL_ CGW_CCU SG_ 1068 RLPSU_RLHrestHeightPos 1500;
BA_ "Version" SG_ 1068 RLPSU_RLHrestHeightPos "21.07.06";
BA_ "Description" SG_ 1068 RLPSU_Opt "PWR_HVU Option";
BA_ "GenSigSendType" SG_ 1068 RLPSU_Opt 4;
BA_ "UserSigValidity" SG_ 1068 RLPSU_Opt 0;
BA_REL_ "GenSigTimeoutTime" BU_SG_REL_ CGW_CCU SG_ 1068 RLPSU_Opt 1500;
BA_ "Version" SG_ 1068 RLPSU_Opt "19.03.05";
BA_ "Description" SG_ 1068 RLPSU_Opt_Captain "PWR_HVU Option_Captain";
BA_ "GenSigSendType" SG_ 1068 RLPSU_Opt_Captain 4;
BA_ "UserSigValidity" SG_ 1068 RLPSU_Opt_Captain 0;
BA_REL_ "GenSigTimeoutTime" BU_SG_REL_ CGW_CCU SG_ 1068 RLPSU_Opt_Captain 1500;
BA_ "Version" SG_ 1068 RLPSU_Opt_Captain "20.10.02";
BA_ "Description" SG_ 1068 RL_AutoRlxSta "ÈÄ¼® LH ½ÃÆ® ¿ÀÅä ¸±·º¼Ç µ¿ÀÛ »óÅÂ Á¤º¸";
BA_ "GenSigSendType" SG_ 1068 RL_AutoRlxSta 4;
BA_ "UserSigValidity" SG_ 1068 RL_AutoRlxSta 0;
BA_REL_ "GenSigTimeoutTime" BU_SG_REL_ APSU SG_ 1068 RL_AutoRlxSta 1500;
BA_REL_ "GenSigTimeoutTime" BU_SG_REL_ DPSU SG_ 1068 RL_AutoRlxSta 1500;
BA_ "NetworkRequest" SG_ 1068 RL_AutoRlxSta 0;
BA_ "NetworkRequestHoldingTime" SG_ 1068 RL_AutoRlxSta 5000;
BA_ "Version" SG_ 1068 RL_AutoRlxSta "21.06.10";
BA_ "Description" SG_ 1068 RL_FLStAutoRlxEnable "ÈÄ¼® LH ½ÃÆ® À§Ä¡¿¡ µû¸¥ Àü¼® LH ¿ÀÅä ¸±·º¼Ç µ¿ÀÛ ÆÇ´Ü";
BA_ "GenSigSendType" SG_ 1068 RL_FLStAutoRlxEnable 4;
BA_ "UserSigValidity" SG_ 1068 RL_FLStAutoRlxEnable 0;
BA_REL_ "GenSigTimeoutTime" BU_SG_REL_ APSU SG_ 1068 RL_FLStAutoRlxEnable 1500;
BA_REL_ "GenSigTimeoutTime" BU_SG_REL_ DPSU SG_ 1068 RL_FLStAutoRlxEnable 1500;
BA_ "NetworkRequest" SG_ 1068 RL_FLStAutoRlxEnable 0;
BA_ "NetworkRequestHoldingTime" SG_ 1068 RL_FLStAutoRlxEnable 5000;
BA_ "Version" SG_ 1068 RL_FLStAutoRlxEnable "21.06.10";
BA_ "Description" SG_ 1068 RLHVU_Opt_Captain "MNL_HVU Option_Captain";
BA_ "GenSigSendType" SG_ 1068 RLHVU_Opt_Captain 4;
BA_ "UserSigValidity" SG_ 1068 RLHVU_Opt_Captain 0;
BA_REL_ "GenSigTimeoutTime" BU_SG_REL_ CGW_CCU SG_ 1068 RLHVU_Opt_Captain 1500;
BA_ "Version" SG_ 1068 RLHVU_Opt_Captain "21.07.06";
BA_ "Description" SG_ 1068 RLPSU_PwrSeatOpt "2¿­ ÁÂÃø ¸®Å¬¶óÀÌ³Ê ½ÃÆ® ¿É¼Ç Á¤º¸";
BA_ "GenSigSendType" SG_ 1068 RLPSU_PwrSeatOpt 4;
BA_ "UserSigValidity" SG_ 1068 RLPSU_PwrSeatOpt 0;
BA_REL_ "GenSigTimeoutTime" BU_SG_REL_ CGW_CCU SG_ 1068 RLPSU_PwrSeatOpt 1500;
BA_ "Version" SG_ 1068 RLPSU_PwrSeatOpt "19.08.05";
BA_ "Description" SG_ 1068 RLPSU_PwrSeatPos "2¿­ ÁÂÃø ½ÃÆ® ¹é À§Ä¡¿¡ µû¸¥ ¹öÆ° È°¼ºÈ­ / ºñÈ°¼ºÈ­";
BA_ "GenSigSendType" SG_ 1068 RLPSU_PwrSeatPos 4;
BA_ "UserSigValidity" SG_ 1068 RLPSU_PwrSeatPos 0;
BA_REL_ "GenSigTimeoutTime" BU_SG_REL_ CGW_CCU SG_ 1068 RLPSU_PwrSeatPos 1500;
BA_ "Version" SG_ 1068 RLPSU_PwrSeatPos "21.07.06";
BA_ "GenMsgSendType" BO_ 1080 0;
BA_ "Description" SG_ 1080 RL_SHVU_SeatOptSta "ÈÄ¼® LH ½ÃÆ®¿¡ Àû¿ëµÈ È÷ÅÍ/ÅëÇ³ ¿É¼Ç »ç¾ç";
BA_ "GenSigSendType" SG_ 1080 RL_SHVU_SeatOptSta 4;
BA_ "UserSigValidity" SG_ 1080 RL_SHVU_SeatOptSta 3;
BA_REL_ "GenSigTimeoutTime" BU_SG_REL_ ATS SG_ 1080 RL_SHVU_SeatOptSta 1500;
BA_REL_ "GenSigTimeoutTime" BU_SG_REL_ CGW_CCU SG_ 1080 RL_SHVU_SeatOptSta 1500;
BA_ "NetworkRequest" SG_ 1080 RL_SHVU_SeatOptSta 0;
BA_ "NetworkRequestHoldingTime" SG_ 1080 RL_SHVU_SeatOptSta 5000;
BA_ "Version" SG_ 1080 RL_SHVU_SeatOptSta "17.12.03";
BA_ "Description" SG_ 1080 RL_SHVU_SeatHtOperSta "ÈÄ¼® LH ½ÃÆ® ÇöÀç ÀÛµ¿ ÁßÀÎ È÷ÅÍ/ÅëÇ³ ´Ü¼ö »óÅÂ";
BA_ "GenSigSendType" SG_ 1080 RL_SHVU_SeatHtOperSta 4;
BA_ "UserSigValidity" SG_ 1080 RL_SHVU_SeatHtOperSta 3;
BA_REL_ "GenSigTimeoutTime" BU_SG_REL_ ATS SG_ 1080 RL_SHVU_SeatHtOperSta 1500;
BA_REL_ "GenSigTimeoutTime" BU_SG_REL_ CGW_CCU SG_ 1080 RL_SHVU_SeatHtOperSta 1500;
BA_ "NetworkRequest" SG_ 1080 RL_SHVU_SeatHtOperSta 0;
BA_ "NetworkRequestHoldingTime" SG_ 1080 RL_SHVU_SeatHtOperSta 5000;
BA_ "Version" SG_ 1080 RL_SHVU_SeatHtOperSta "21.07.06";
BA_ "Description" SG_ 1080 RL_SHVU_HtSwHiIndSta_RHD "RL ½ÃÆ® ¿­¼± ½ºÀ§Ä¡ High Indicator Á¤º¸ (RHD)

-2nd LH Seat heater high Information";
BA_ "GenSigSendType" SG_ 1080 RL_SHVU_HtSwHiIndSta_RHD 4;
BA_ "UserSigValidity" SG_ 1080 RL_SHVU_HtSwHiIndSta_RHD 3;
BA_REL_ "GenSigTimeoutTime" BU_SG_REL_ ATS SG_ 1080 RL_SHVU_HtSwHiIndSta_RHD 1500;
BA_REL_ "GenSigTimeoutTime" BU_SG_REL_ CGW_CCU SG_ 1080 RL_SHVU_HtSwHiIndSta_RHD 1500;
BA_REL_ "GenSigTimeoutTime" BU_SG_REL_ CGW_CCU SG_ 1080 RL_SHVU_HtSwHiIndSta_RHD 1500;
BA_ "NetworkRequest" SG_ 1080 RL_SHVU_HtSwHiIndSta_RHD 0;
BA_ "NetworkRequestHoldingTime" SG_ 1080 RL_SHVU_HtSwHiIndSta_RHD 5000;
BA_ "Version" SG_ 1080 RL_SHVU_HtSwHiIndSta_RHD "19.08.05";
BA_ "Description" SG_ 1080 RL_SHVU_HtSwMidIndSta_RHD "RL ½ÃÆ® ¿­¼± ½ºÀ§Ä¡ Mid Indicator Á¤º¸ (RHD)

-2nd LH Seat heater mid Information";
BA_ "GenSigSendType" SG_ 1080 RL_SHVU_HtSwMidIndSta_RHD 4;
BA_ "UserSigValidity" SG_ 1080 RL_SHVU_HtSwMidIndSta_RHD 3;
BA_REL_ "GenSigTimeoutTime" BU_SG_REL_ ATS SG_ 1080 RL_SHVU_HtSwMidIndSta_RHD 1500;
BA_REL_ "GenSigTimeoutTime" BU_SG_REL_ CGW_CCU SG_ 1080 RL_SHVU_HtSwMidIndSta_RHD 1500;
BA_ "NetworkRequest" SG_ 1080 RL_SHVU_HtSwMidIndSta_RHD 0;
BA_ "NetworkRequestHoldingTime" SG_ 1080 RL_SHVU_HtSwMidIndSta_RHD 5000;
BA_ "Version" SG_ 1080 RL_SHVU_HtSwMidIndSta_RHD "19.08.05";
BA_ "Description" SG_ 1080 RL_SHVU_HtSwLowIndSta_RHD "RL ½ÃÆ® ¿­¼± ½ºÀ§Ä¡ Low Indicator Á¤º¸ (RHD)

-2nd LH Seat heater low Information";
BA_ "GenSigSendType" SG_ 1080 RL_SHVU_HtSwLowIndSta_RHD 4;
BA_ "UserSigValidity" SG_ 1080 RL_SHVU_HtSwLowIndSta_RHD 3;
BA_REL_ "GenSigTimeoutTime" BU_SG_REL_ ATS SG_ 1080 RL_SHVU_HtSwLowIndSta_RHD 1500;
BA_REL_ "GenSigTimeoutTime" BU_SG_REL_ CGW_CCU SG_ 1080 RL_SHVU_HtSwLowIndSta_RHD 1500;
BA_ "NetworkRequest" SG_ 1080 RL_SHVU_HtSwLowIndSta_RHD 0;
BA_ "NetworkRequestHoldingTime" SG_ 1080 RL_SHVU_HtSwLowIndSta_RHD 5000;
BA_ "Version" SG_ 1080 RL_SHVU_HtSwLowIndSta_RHD "19.08.05";
BA_ "Description" SG_ 1080 RL_SHVU_VntSwHiIndSta_RHD "RL ½ÃÆ® ÅëÇ³ ½ºÀ§Ä¡ High Indicator Á¤º¸ (RHD)

-2nd LH Seat vent high Information";
BA_ "GenSigSendType" SG_ 1080 RL_SHVU_VntSwHiIndSta_RHD 4;
BA_ "UserSigValidity" SG_ 1080 RL_SHVU_VntSwHiIndSta_RHD 3;
BA_REL_ "GenSigTimeoutTime" BU_SG_REL_ ATS SG_ 1080 RL_SHVU_VntSwHiIndSta_RHD 1500;
BA_REL_ "GenSigTimeoutTime" BU_SG_REL_ CGW_CCU SG_ 1080 RL_SHVU_VntSwHiIndSta_RHD 1500;
BA_ "NetworkRequest" SG_ 1080 RL_SHVU_VntSwHiIndSta_RHD 0;
BA_ "NetworkRequestHoldingTime" SG_ 1080 RL_SHVU_VntSwHiIndSta_RHD 5000;
BA_ "Version" SG_ 1080 RL_SHVU_VntSwHiIndSta_RHD "19.08.05";
BA_ "Description" SG_ 1080 RL_SHVU_VntSwMidIndSta_RHD "RL ½ÃÆ® ÅëÇ³ ½ºÀ§Ä¡ Mid Indicator Á¤º¸ (RHD)

-2nd LH Seat vent mid Information";
BA_ "GenSigSendType" SG_ 1080 RL_SHVU_VntSwMidIndSta_RHD 4;
BA_ "UserSigValidity" SG_ 1080 RL_SHVU_VntSwMidIndSta_RHD 3;
BA_REL_ "GenSigTimeoutTime" BU_SG_REL_ ATS SG_ 1080 RL_SHVU_VntSwMidIndSta_RHD 1500;
BA_REL_ "GenSigTimeoutTime" BU_SG_REL_ CGW_CCU SG_ 1080 RL_SHVU_VntSwMidIndSta_RHD 1500;
BA_ "NetworkRequest" SG_ 1080 RL_SHVU_VntSwMidIndSta_RHD 0;
BA_ "NetworkRequestHoldingTime" SG_ 1080 RL_SHVU_VntSwMidIndSta_RHD 5000;
BA_ "Version" SG_ 1080 RL_SHVU_VntSwMidIndSta_RHD "19.08.05";
BA_ "Description" SG_ 1080 RL_SHVU_VntSwLowIndSta_RHD "RL ½ÃÆ® ÅëÇ³ ½ºÀ§Ä¡ Low Indicator Á¤º¸ (RHD)

-2nd LH Seat vent low Information";
BA_ "GenSigSendType" SG_ 1080 RL_SHVU_VntSwLowIndSta_RHD 4;
BA_ "UserSigValidity" SG_ 1080 RL_SHVU_VntSwLowIndSta_RHD 3;
BA_REL_ "GenSigTimeoutTime" BU_SG_REL_ ATS SG_ 1080 RL_SHVU_VntSwLowIndSta_RHD 1500;
BA_REL_ "GenSigTimeoutTime" BU_SG_REL_ CGW_CCU SG_ 1080 RL_SHVU_VntSwLowIndSta_RHD 1500;
BA_ "NetworkRequest" SG_ 1080 RL_SHVU_VntSwLowIndSta_RHD 0;
BA_ "NetworkRequestHoldingTime" SG_ 1080 RL_SHVU_VntSwLowIndSta_RHD 5000;
BA_ "Version" SG_ 1080 RL_SHVU_VntSwLowIndSta_RHD "19.08.05";
BA_ "Description" SG_ 1080 RL_SHVU_HtBlcUsmSta_RHD "RL Seat Heater Balance Status(RHD)";
BA_ "GenSigSendType" SG_ 1080 RL_SHVU_HtBlcUsmSta_RHD 4;
BA_ "UserSigValidity" SG_ 1080 RL_SHVU_HtBlcUsmSta_RHD 3;
BA_REL_ "GenSigTimeoutTime" BU_SG_REL_ ATS SG_ 1080 RL_SHVU_HtBlcUsmSta_RHD 1500;
BA_REL_ "GenSigTimeoutTime" BU_SG_REL_ CGW_CCU SG_ 1080 RL_SHVU_HtBlcUsmSta_RHD 1500;
BA_ "NetworkRequest" SG_ 1080 RL_SHVU_HtBlcUsmSta_RHD 0;
BA_ "NetworkRequestHoldingTime" SG_ 1080 RL_SHVU_HtBlcUsmSta_RHD 5000;
BA_ "Version" SG_ 1080 RL_SHVU_HtBlcUsmSta_RHD "20.01.02";
BA_ "GenMsgSendType" BO_ 1070 0;
BA_ "Description" SG_ 1070 RL_SHVU_HtSwHiIndSta "RL ½ÃÆ® ¿­¼± ½ºÀ§Ä¡ High Indicator Á¤º¸

-2nd LH Seat heater high Information";
BA_ "GenSigSendType" SG_ 1070 RL_SHVU_HtSwHiIndSta 4;
BA_ "UserSigValidity" SG_ 1070 RL_SHVU_HtSwHiIndSta 3;
BA_REL_ "GenSigTimeoutTime" BU_SG_REL_ ATS SG_ 1070 RL_SHVU_HtSwHiIndSta 1500;
BA_REL_ "GenSigTimeoutTime" BU_SG_REL_ CGW_CCU SG_ 1070 RL_SHVU_HtSwHiIndSta 1500;
BA_ "NetworkRequest" SG_ 1070 RL_SHVU_HtSwHiIndSta 0;
BA_ "NetworkRequestHoldingTime" SG_ 1070 RL_SHVU_HtSwHiIndSta 5000;
BA_ "Version" SG_ 1070 RL_SHVU_HtSwHiIndSta "21.07.06";
BA_ "Description" SG_ 1070 RL_SHVU_HtSwMidIndSta "RL ½ÃÆ® ¿­¼± ½ºÀ§Ä¡ Mid Indicator Á¤º¸

-2nd LH Seat heater mid Information";
BA_ "GenSigSendType" SG_ 1070 RL_SHVU_HtSwMidIndSta 4;
BA_ "UserSigValidity" SG_ 1070 RL_SHVU_HtSwMidIndSta 3;
BA_REL_ "GenSigTimeoutTime" BU_SG_REL_ ATS SG_ 1070 RL_SHVU_HtSwMidIndSta 1500;
BA_REL_ "GenSigTimeoutTime" BU_SG_REL_ CGW_CCU SG_ 1070 RL_SHVU_HtSwMidIndSta 1500;
BA_ "NetworkRequest" SG_ 1070 RL_SHVU_HtSwMidIndSta 0;
BA_ "NetworkRequestHoldingTime" SG_ 1070 RL_SHVU_HtSwMidIndSta 5000;
BA_ "Version" SG_ 1070 RL_SHVU_HtSwMidIndSta "21.07.06";
BA_ "Description" SG_ 1070 RL_SHVU_HtSwLowIndSta "RL ½ÃÆ® ¿­¼± ½ºÀ§Ä¡ Low Indicator Á¤º¸

-2nd LH Seat heater low Information";
BA_ "GenSigSendType" SG_ 1070 RL_SHVU_HtSwLowIndSta 4;
BA_ "UserSigValidity" SG_ 1070 RL_SHVU_HtSwLowIndSta 3;
BA_REL_ "GenSigTimeoutTime" BU_SG_REL_ ATS SG_ 1070 RL_SHVU_HtSwLowIndSta 1500;
BA_REL_ "GenSigTimeoutTime" BU_SG_REL_ CGW_CCU SG_ 1070 RL_SHVU_HtSwLowIndSta 1500;
BA_ "NetworkRequest" SG_ 1070 RL_SHVU_HtSwLowIndSta 0;
BA_ "NetworkRequestHoldingTime" SG_ 1070 RL_SHVU_HtSwLowIndSta 5000;
BA_ "Version" SG_ 1070 RL_SHVU_HtSwLowIndSta "21.07.06";
BA_ "Description" SG_ 1070 RL_SHVU_VntSwHiIndSta "RL ½ÃÆ® ÅëÇ³ ½ºÀ§Ä¡ High Indicator Á¤º¸

-2nd LH Seat vent high Information";
BA_ "GenSigSendType" SG_ 1070 RL_SHVU_VntSwHiIndSta 4;
BA_ "UserSigValidity" SG_ 1070 RL_SHVU_VntSwHiIndSta 3;
BA_REL_ "GenSigTimeoutTime" BU_SG_REL_ ATS SG_ 1070 RL_SHVU_VntSwHiIndSta 1500;
BA_REL_ "GenSigTimeoutTime" BU_SG_REL_ CGW_CCU SG_ 1070 RL_SHVU_VntSwHiIndSta 1500;
BA_ "NetworkRequest" SG_ 1070 RL_SHVU_VntSwHiIndSta 0;
BA_ "NetworkRequestHoldingTime" SG_ 1070 RL_SHVU_VntSwHiIndSta 5000;
BA_ "Version" SG_ 1070 RL_SHVU_VntSwHiIndSta "21.07.06";
BA_ "Description" SG_ 1070 RL_SHVU_VntSwMidIndSta "RL ½ÃÆ® ÅëÇ³ ½ºÀ§Ä¡ Mid Indicator Á¤º¸

-2nd LH Seat vent mid Information";
BA_ "GenSigSendType" SG_ 1070 RL_SHVU_VntSwMidIndSta 4;
BA_ "UserSigValidity" SG_ 1070 RL_SHVU_VntSwMidIndSta 3;
BA_REL_ "GenSigTimeoutTime" BU_SG_REL_ ATS SG_ 1070 RL_SHVU_VntSwMidIndSta 1500;
BA_REL_ "GenSigTimeoutTime" BU_SG_REL_ CGW_CCU SG_ 1070 RL_SHVU_VntSwMidIndSta 1500;
BA_ "NetworkRequest" SG_ 1070 RL_SHVU_VntSwMidIndSta 0;
BA_ "NetworkRequestHoldingTime" SG_ 1070 RL_SHVU_VntSwMidIndSta 5000;
BA_ "Version" SG_ 1070 RL_SHVU_VntSwMidIndSta "21.07.06";
BA_ "Description" SG_ 1070 RL_SHVU_VntSwLowIndSta "RL ½ÃÆ® ÅëÇ³ ½ºÀ§Ä¡ Low Indicator Á¤º¸

-2nd LH Seat vent low Information";
BA_ "GenSigSendType" SG_ 1070 RL_SHVU_VntSwLowIndSta 4;
BA_ "UserSigValidity" SG_ 1070 RL_SHVU_VntSwLowIndSta 3;
BA_REL_ "GenSigTimeoutTime" BU_SG_REL_ ATS SG_ 1070 RL_SHVU_VntSwLowIndSta 1500;
BA_REL_ "GenSigTimeoutTime" BU_SG_REL_ CGW_CCU SG_ 1070 RL_SHVU_VntSwLowIndSta 1500;
BA_ "NetworkRequest" SG_ 1070 RL_SHVU_VntSwLowIndSta 0;
BA_ "NetworkRequestHoldingTime" SG_ 1070 RL_SHVU_VntSwLowIndSta 5000;
BA_ "Version" SG_ 1070 RL_SHVU_VntSwLowIndSta "21.07.06";
BA_ "Description" SG_ 1070 RL_SHVU_HtBlcUsmSta "RL Seat Heater Balance Status";
BA_ "GenSigSendType" SG_ 1070 RL_SHVU_HtBlcUsmSta 4;
BA_ "UserSigValidity" SG_ 1070 RL_SHVU_HtBlcUsmSta 3;
BA_REL_ "GenSigTimeoutTime" BU_SG_REL_ ATS SG_ 1070 RL_SHVU_HtBlcUsmSta 1500;
BA_REL_ "GenSigTimeoutTime" BU_SG_REL_ CGW_CCU SG_ 1070 RL_SHVU_HtBlcUsmSta 1500;
BA_REL_ "GenSigTimeoutTime" BU_SG_REL_ CGW_CCU SG_ 1070 RL_SHVU_HtBlcUsmSta 1500;
BA_ "NetworkRequest" SG_ 1070 RL_SHVU_HtBlcUsmSta 0;
BA_ "NetworkRequestHoldingTime" SG_ 1070 RL_SHVU_HtBlcUsmSta 5000;
BA_ "Version" SG_ 1070 RL_SHVU_HtBlcUsmSta "21.07.06";
BA_ "GenMsgSendType" BO_ 1069 0;
BA_ "Description" SG_ 1069 RRPSU_ReclMtrPos "2¿­ RH ½ÃÆ® Recline ¸ðÅÍ À§Ä¡°ª ¼Û½Å

 - Seat Recline Position Information signal for 2nd RH seat";
BA_ "GenSigSendType" SG_ 1069 RRPSU_ReclMtrPos 4;
BA_ "UserSigValidity" SG_ 1069 RRPSU_ReclMtrPos 0;
BA_REL_ "GenSigTimeoutTime" BU_SG_REL_ PFSU SG_ 1069 RRPSU_ReclMtrPos 1500;
BA_REL_ "GenSigTimeoutTime" BU_SG_REL_ CGW_CCU SG_ 1069 RRPSU_ReclMtrPos 1500;
BA_ "NetworkRequest" SG_ 1069 RRPSU_ReclMtrPos 0;
BA_ "NetworkRequestHoldingTime" SG_ 1069 RRPSU_ReclMtrPos 5000;
BA_ "Version" SG_ 1069 RRPSU_ReclMtrPos "19.06.01";
BA_ "Description" SG_ 1069 RRPSU_PwrSeatOpt "2¿­ ¿ìÃø ¸®Å¬¶óÀÌ³Ê ½ÃÆ® ¿É¼Ç Á¤º¸";
BA_ "GenSigSendType" SG_ 1069 RRPSU_PwrSeatOpt 4;
BA_ "UserSigValidity" SG_ 1069 RRPSU_PwrSeatOpt 0;
BA_REL_ "GenSigTimeoutTime" BU_SG_REL_ CGW_CCU SG_ 1069 RRPSU_PwrSeatOpt 1500;
BA_ "Version" SG_ 1069 RRPSU_PwrSeatOpt "19.08.05";
BA_ "Description" SG_ 1069 RRPSU_PwrSeatPos "2¿­ ¿ìÃø ½ÃÆ® ¹é À§Ä¡¿¡ µû¸¥ ¹öÆ° È°¼ºÈ­ / ºñÈ°¼ºÈ­";
BA_ "GenSigSendType" SG_ 1069 RRPSU_PwrSeatPos 4;
BA_ "UserSigValidity" SG_ 1069 RRPSU_PwrSeatPos 0;
BA_REL_ "GenSigTimeoutTime" BU_SG_REL_ CGW_CCU SG_ 1069 RRPSU_PwrSeatPos 1500;
BA_ "Version" SG_ 1069 RRPSU_PwrSeatPos "19.10.07";
BA_ "Description" SG_ 1069 RRPSU_RRSlidPos "2¿­ ¿ìÃø ½ÃÆ® ½½¶óÀÌµå ¸ðÅÍ À§Ä¡¿¡ µû¸¥ ¹öÆ° È°¼ºÈ­ / ºñÈ°¼ºÈ­";
BA_ "GenSigSendType" SG_ 1069 RRPSU_RRSlidPos 4;
BA_ "UserSigValidity" SG_ 1069 RRPSU_RRSlidPos 0;
BA_REL_ "GenSigTimeoutTime" BU_SG_REL_ CGW_CCU SG_ 1069 RRPSU_RRSlidPos 1500;
BA_ "Version" SG_ 1069 RRPSU_RRSlidPos "20.05.03";
BA_ "Description" SG_ 1069 RRPSU_RRRclPos "2¿­ ¿ìÃø ½ÃÆ® ¸®Å¬¶óÀÌ³Ê ¸ðÅÍ À§Ä¡¿¡ µû¸¥ ¹öÆ° È°¼ºÈ­ / ºñÈ°¼ºÈ­";
BA_ "GenSigSendType" SG_ 1069 RRPSU_RRRclPos 4;
BA_ "UserSigValidity" SG_ 1069 RRPSU_RRRclPos 0;
BA_REL_ "GenSigTimeoutTime" BU_SG_REL_ CGW_CCU SG_ 1069 RRPSU_RRRclPos 1500;
BA_ "Version" SG_ 1069 RRPSU_RRRclPos "20.05.03";
BA_ "Description" SG_ 1069 RRPSU_RRTiltPos "2¿­ ¿ìÃø ½ÃÆ® Äí¼Ç Æ¿Æ® ¸ðÅÍ À§Ä¡¿¡ µû¸¥ ¹öÆ° È°¼ºÈ­ / ºñÈ°¼ºÈ­";
BA_ "GenSigSendType" SG_ 1069 RRPSU_RRTiltPos 4;
BA_ "UserSigValidity" SG_ 1069 RRPSU_RRTiltPos 0;
BA_REL_ "GenSigTimeoutTime" BU_SG_REL_ CGW_CCU SG_ 1069 RRPSU_RRTiltPos 1500;
BA_ "Version" SG_ 1069 RRPSU_RRTiltPos "20.05.03";
BA_ "Description" SG_ 1069 RRPSU_RRLegExtPos "2¿­ ¿ìÃø ½ÃÆ® ·¹±× ÀÍ½ºÅÙ¼Ç (ÀüÈÄ¹æ) ¸ðÅÍ À§Ä¡¿¡ µû¸¥ ¹öÆ° È°¼ºÈ­ / ºñÈ°¼ºÈ­";
BA_ "GenSigSendType" SG_ 1069 RRPSU_RRLegExtPos 4;
BA_ "UserSigValidity" SG_ 1069 RRPSU_RRLegExtPos 0;
BA_REL_ "GenSigTimeoutTime" BU_SG_REL_ CGW_CCU SG_ 1069 RRPSU_RRLegExtPos 1500;
BA_ "Version" SG_ 1069 RRPSU_RRLegExtPos "20.05.03";
BA_ "Description" SG_ 1069 RRPSU_RRLegSupPos "2¿­ ¿ìÃø ½ÃÆ® ·¹±×ÀÍ½ºÅÙ¼Ç (»óÇÏ¹æ) ¸ðÅÍ À§Ä¡¿¡ µû¸¥ ¹öÆ° È°¼ºÈ­ / ºñÈ°¼ºÈ­";
BA_ "GenSigSendType" SG_ 1069 RRPSU_RRLegSupPos 4;
BA_ "UserSigValidity" SG_ 1069 RRPSU_RRLegSupPos 0;
BA_REL_ "GenSigTimeoutTime" BU_SG_REL_ CGW_CCU SG_ 1069 RRPSU_RRLegSupPos 1500;
BA_ "Version" SG_ 1069 RRPSU_RRLegSupPos "20.05.03";
BA_ "Description" SG_ 1069 RRPSU_RRStEsyAcsUSMSta "Rear RH Seat EasyAccess USM Setting";
BA_ "GenSigSendType" SG_ 1069 RRPSU_RRStEsyAcsUSMSta 4;
BA_ "UserSigValidity" SG_ 1069 RRPSU_RRStEsyAcsUSMSta 0;
BA_REL_ "GenSigTimeoutTime" BU_SG_REL_ CGW_CCU SG_ 1069 RRPSU_RRStEsyAcsUSMSta 1500;
BA_ "Version" SG_ 1069 RRPSU_RRStEsyAcsUSMSta "18.07.01";
BA_ "Description" SG_ 1069 RRPSU_RRHrestSlidPos "2¿­ ¿ìÃø ½ÃÆ® Çìµå·¹½ºÆ® ½½¶óÀÌµå À§Ä¡¿¡ µû¸¥ ¹öÆ° È°¼ºÈ­ / ºñÈ°¼ºÈ­";
BA_ "GenSigSendType" SG_ 1069 RRPSU_RRHrestSlidPos 4;
BA_ "UserSigValidity" SG_ 1069 RRPSU_RRHrestSlidPos 0;
BA_REL_ "GenSigTimeoutTime" BU_SG_REL_ CGW_CCU SG_ 1069 RRPSU_RRHrestSlidPos 1500;
BA_ "Version" SG_ 1069 RRPSU_RRHrestSlidPos "20.05.03";
BA_ "Description" SG_ 1069 RRPSU_RRHrestHeightPos "2¿­ ¿ìÃø ½ÃÆ® Çìµå·¹½ºÆ® ÇÏÀÌÆ® ¸ðÅÍ À§Ä¡¿¡ µû¸¥ ¹öÆ° È°¼ºÈ­ / ºñÈ°¼ºÈ­";
BA_ "GenSigSendType" SG_ 1069 RRPSU_RRHrestHeightPos 4;
BA_ "UserSigValidity" SG_ 1069 RRPSU_RRHrestHeightPos 0;
BA_REL_ "GenSigTimeoutTime" BU_SG_REL_ CGW_CCU SG_ 1069 RRPSU_RRHrestHeightPos 1500;
BA_ "Version" SG_ 1069 RRPSU_RRHrestHeightPos "20.05.03";
BA_ "Description" SG_ 1069 RRPSU_Opt_Captain "PWR_HVU Option_Captain";
BA_ "GenSigSendType" SG_ 1069 RRPSU_Opt_Captain 4;
BA_ "UserSigValidity" SG_ 1069 RRPSU_Opt_Captain 0;
BA_REL_ "GenSigTimeoutTime" BU_SG_REL_ CGW_CCU SG_ 1069 RRPSU_Opt_Captain 1500;
BA_ "Version" SG_ 1069 RRPSU_Opt_Captain "20.10.02";
BA_ "Description" SG_ 1069 RR_AutoRlxSta "ÈÄ¼® RH ½ÃÆ® ¿ÀÅä ¸±·º¼Ç µ¿ÀÛ »óÅÂ Á¤º¸";
BA_ "GenSigSendType" SG_ 1069 RR_AutoRlxSta 4;
BA_ "UserSigValidity" SG_ 1069 RR_AutoRlxSta 0;
BA_REL_ "GenSigTimeoutTime" BU_SG_REL_ APSU SG_ 1069 RR_AutoRlxSta 1500;
BA_REL_ "GenSigTimeoutTime" BU_SG_REL_ DPSU SG_ 1069 RR_AutoRlxSta 1500;
BA_ "NetworkRequest" SG_ 1069 RR_AutoRlxSta 0;
BA_ "NetworkRequestHoldingTime" SG_ 1069 RR_AutoRlxSta 5000;
BA_ "Version" SG_ 1069 RR_AutoRlxSta "21.06.10";
BA_ "Description" SG_ 1069 RR_FRStAutoRlxEnable "ÈÄ¼® RH ½ÃÆ® À§Ä¡¿¡ µû¸¥ Àü¼® RH ¿ÀÅä ¸±·º¼Ç µ¿ÀÛ ÆÇ´Ü ½ÅÈ£";
BA_ "GenSigSendType" SG_ 1069 RR_FRStAutoRlxEnable 4;
BA_ "UserSigValidity" SG_ 1069 RR_FRStAutoRlxEnable 0;
BA_REL_ "GenSigTimeoutTime" BU_SG_REL_ APSU SG_ 1069 RR_FRStAutoRlxEnable 1500;
BA_REL_ "GenSigTimeoutTime" BU_SG_REL_ DPSU SG_ 1069 RR_FRStAutoRlxEnable 1500;
BA_ "NetworkRequest" SG_ 1069 RR_FRStAutoRlxEnable 0;
BA_ "NetworkRequestHoldingTime" SG_ 1069 RR_FRStAutoRlxEnable 5000;
BA_ "Version" SG_ 1069 RR_FRStAutoRlxEnable "21.06.10";
BA_ "Description" SG_ 1069 RRHVU_Opt_Captain "MNL_HVU Option_Captain";
BA_ "GenSigSendType" SG_ 1069 RRHVU_Opt_Captain 4;
BA_ "UserSigValidity" SG_ 1069 RRHVU_Opt_Captain 0;
BA_REL_ "GenSigTimeoutTime" BU_SG_REL_ CGW_CCU SG_ 1069 RRHVU_Opt_Captain 1500;
BA_ "Version" SG_ 1069 RRHVU_Opt_Captain "21.07.06";
BA_ "Description" SG_ 1069 RRPSU_RLStEsyAcsUSMSta "Rear LH Seat EasyAccess USM Setting";
BA_ "GenSigSendType" SG_ 1069 RRPSU_RLStEsyAcsUSMSta 4;
BA_ "UserSigValidity" SG_ 1069 RRPSU_RLStEsyAcsUSMSta 0;
BA_REL_ "GenSigTimeoutTime" BU_SG_REL_ CGW_CCU SG_ 1069 RRPSU_RLStEsyAcsUSMSta 1500;
BA_ "Version" SG_ 1069 RRPSU_RLStEsyAcsUSMSta "18.07.01";
BA_ "Description" SG_ 1069 RRPSU_Opt "PWR_HVU Option";
BA_ "GenSigSendType" SG_ 1069 RRPSU_Opt 4;
BA_ "UserSigValidity" SG_ 1069 RRPSU_Opt 0;
BA_REL_ "GenSigTimeoutTime" BU_SG_REL_ CGW_CCU SG_ 1069 RRPSU_Opt 1500;
BA_ "Version" SG_ 1069 RRPSU_Opt "19.03.05";
BA_ "GenMsgSendType" BO_ 1071 0;
BA_ "Description" SG_ 1071 RR_SHVU_HtSwHiIndSta "RR ½ÃÆ® ¿­¼± ½ºÀ§Ä¡ High Indicator Á¤º¸

-2nd RH Seat heater high Information";
BA_ "GenSigSendType" SG_ 1071 RR_SHVU_HtSwHiIndSta 4;
BA_ "UserSigValidity" SG_ 1071 RR_SHVU_HtSwHiIndSta 3;
BA_REL_ "GenSigTimeoutTime" BU_SG_REL_ ATS SG_ 1071 RR_SHVU_HtSwHiIndSta 1500;
BA_REL_ "GenSigTimeoutTime" BU_SG_REL_ CGW_CCU SG_ 1071 RR_SHVU_HtSwHiIndSta 1500;
BA_ "NetworkRequest" SG_ 1071 RR_SHVU_HtSwHiIndSta 0;
BA_ "NetworkRequestHoldingTime" SG_ 1071 RR_SHVU_HtSwHiIndSta 5000;
BA_ "Version" SG_ 1071 RR_SHVU_HtSwHiIndSta "21.07.06";
BA_ "Description" SG_ 1071 RR_SHVU_HtSwMidIndSta "RL ½ÃÆ® ¿­¼± ½ºÀ§Ä¡ Mid Indicator Á¤º¸

-2nd LH Seat heater mid Information";
BA_ "GenSigSendType" SG_ 1071 RR_SHVU_HtSwMidIndSta 4;
BA_ "UserSigValidity" SG_ 1071 RR_SHVU_HtSwMidIndSta 3;
BA_REL_ "GenSigTimeoutTime" BU_SG_REL_ ATS SG_ 1071 RR_SHVU_HtSwMidIndSta 1500;
BA_REL_ "GenSigTimeoutTime" BU_SG_REL_ CGW_CCU SG_ 1071 RR_SHVU_HtSwMidIndSta 1500;
BA_ "NetworkRequest" SG_ 1071 RR_SHVU_HtSwMidIndSta 0;
BA_ "NetworkRequestHoldingTime" SG_ 1071 RR_SHVU_HtSwMidIndSta 5000;
BA_ "Version" SG_ 1071 RR_SHVU_HtSwMidIndSta "21.07.06";
BA_ "Description" SG_ 1071 RR_SHVU_HtSwLowIndSta "RR ½ÃÆ® ¿­¼± ½ºÀ§Ä¡ Low Indicator Á¤º¸

-2nd RH Seat heater low Information";
BA_ "GenSigSendType" SG_ 1071 RR_SHVU_HtSwLowIndSta 4;
BA_ "UserSigValidity" SG_ 1071 RR_SHVU_HtSwLowIndSta 3;
BA_REL_ "GenSigTimeoutTime" BU_SG_REL_ ATS SG_ 1071 RR_SHVU_HtSwLowIndSta 1500;
BA_REL_ "GenSigTimeoutTime" BU_SG_REL_ CGW_CCU SG_ 1071 RR_SHVU_HtSwLowIndSta 1500;
BA_ "NetworkRequest" SG_ 1071 RR_SHVU_HtSwLowIndSta 0;
BA_ "NetworkRequestHoldingTime" SG_ 1071 RR_SHVU_HtSwLowIndSta 5000;
BA_ "Version" SG_ 1071 RR_SHVU_HtSwLowIndSta "21.07.06";
BA_ "Description" SG_ 1071 RR_SHVU_VntSwHiIndSta "RR ½ÃÆ® ÅëÇ³ ½ºÀ§Ä¡ High Indicator Á¤º¸

-2nd RH Seat vent high Information";
BA_ "GenSigSendType" SG_ 1071 RR_SHVU_VntSwHiIndSta 4;
BA_ "UserSigValidity" SG_ 1071 RR_SHVU_VntSwHiIndSta 3;
BA_REL_ "GenSigTimeoutTime" BU_SG_REL_ ATS SG_ 1071 RR_SHVU_VntSwHiIndSta 1500;
BA_REL_ "GenSigTimeoutTime" BU_SG_REL_ CGW_CCU SG_ 1071 RR_SHVU_VntSwHiIndSta 1500;
BA_ "NetworkRequest" SG_ 1071 RR_SHVU_VntSwHiIndSta 0;
BA_ "NetworkRequestHoldingTime" SG_ 1071 RR_SHVU_VntSwHiIndSta 5000;
BA_ "Version" SG_ 1071 RR_SHVU_VntSwHiIndSta "21.07.06";
BA_ "Description" SG_ 1071 RR_SHVU_VntSwMidIndSta "RR ½ÃÆ® ÅëÇ³ ½ºÀ§Ä¡ Mid Indicator Á¤º¸

-2nd RH Seat vent mid Information";
BA_ "GenSigSendType" SG_ 1071 RR_SHVU_VntSwMidIndSta 4;
BA_ "UserSigValidity" SG_ 1071 RR_SHVU_VntSwMidIndSta 3;
BA_REL_ "GenSigTimeoutTime" BU_SG_REL_ ATS SG_ 1071 RR_SHVU_VntSwMidIndSta 1500;
BA_REL_ "GenSigTimeoutTime" BU_SG_REL_ CGW_CCU SG_ 1071 RR_SHVU_VntSwMidIndSta 1500;
BA_ "NetworkRequest" SG_ 1071 RR_SHVU_VntSwMidIndSta 0;
BA_ "NetworkRequestHoldingTime" SG_ 1071 RR_SHVU_VntSwMidIndSta 5000;
BA_ "Version" SG_ 1071 RR_SHVU_VntSwMidIndSta "21.07.06";
BA_ "Description" SG_ 1071 RR_SHVU_VntSwLowIndSta "RR ½ÃÆ® ÅëÇ³ ½ºÀ§Ä¡ Low Indicator Á¤º¸

-2nd RH Seat vent low Information";
BA_ "GenSigSendType" SG_ 1071 RR_SHVU_VntSwLowIndSta 4;
BA_ "UserSigValidity" SG_ 1071 RR_SHVU_VntSwLowIndSta 3;
BA_REL_ "GenSigTimeoutTime" BU_SG_REL_ ATS SG_ 1071 RR_SHVU_VntSwLowIndSta 1500;
BA_REL_ "GenSigTimeoutTime" BU_SG_REL_ CGW_CCU SG_ 1071 RR_SHVU_VntSwLowIndSta 1500;
BA_ "NetworkRequest" SG_ 1071 RR_SHVU_VntSwLowIndSta 0;
BA_ "NetworkRequestHoldingTime" SG_ 1071 RR_SHVU_VntSwLowIndSta 5000;
BA_ "Version" SG_ 1071 RR_SHVU_VntSwLowIndSta "21.07.06";
BA_ "Description" SG_ 1071 RR_SHVU_HtBlcUsmSta "RR Seat Heater Balance Status";
BA_ "GenSigSendType" SG_ 1071 RR_SHVU_HtBlcUsmSta 4;
BA_ "UserSigValidity" SG_ 1071 RR_SHVU_HtBlcUsmSta 3;
BA_REL_ "GenSigTimeoutTime" BU_SG_REL_ ATS SG_ 1071 RR_SHVU_HtBlcUsmSta 1500;
BA_REL_ "GenSigTimeoutTime" BU_SG_REL_ CGW_CCU SG_ 1071 RR_SHVU_HtBlcUsmSta 1500;
BA_REL_ "GenSigTimeoutTime" BU_SG_REL_ CGW_CCU SG_ 1071 RR_SHVU_HtBlcUsmSta 1500;
BA_ "NetworkRequest" SG_ 1071 RR_SHVU_HtBlcUsmSta 0;
BA_ "NetworkRequestHoldingTime" SG_ 1071 RR_SHVU_HtBlcUsmSta 5000;
BA_ "Version" SG_ 1071 RR_SHVU_HtBlcUsmSta "21.07.06";
BA_ "GenMsgSendType" BO_ 1073 0;
BA_ "Description" SG_ 1073 USM_ValCmdSta "USM request value of RWPC";
BA_ "GenSigSendType" SG_ 1073 USM_ValCmdSta 4;
BA_ "UserSigValidity" SG_ 1073 USM_ValCmdSta 0;
BA_REL_ "GenSigTimeoutTime" BU_SG_REL_ ATS SG_ 1073 USM_ValCmdSta 1500;
BA_REL_ "GenSigTimeoutTime" BU_SG_REL_ CGW_CCU SG_ 1073 USM_ValCmdSta 1500;
BA_ "NetworkRequest" SG_ 1073 USM_ValCmdSta 0;
BA_ "NetworkRequestHoldingTime" SG_ 1073 USM_ValCmdSta 5000;
BA_ "Version" SG_ 1073 USM_ValCmdSta "17.11.00";
BA_ "Description" SG_ 1073 RWPC_SWVerMinor1 "Indicate the RWPC software version as follows:

- The software version is displayed in three digits.

- The Major and Minor digits are separated by '.'

- Signal values are transmitted to ASCII codes.



¡Ø Example

RWPC_SWVerMajor1 : 0x41 (HEX) -> ASCII CODE : 'A' 

RWPC_SWVerMinor1 : 0x30 (HEX) -> ASCII CODE : '0'

RWPC_SWVerMinor2 : 0x33 (HEX) -> ASCII CODE : '3'

=> RWPC S/W Ver is displayed 'A.03'";
BA_ "GenSigSendType" SG_ 1073 RWPC_SWVerMinor1 4;
BA_ "UserSigValidity" SG_ 1073 RWPC_SWVerMinor1 0;
BA_REL_ "GenSigTimeoutTime" BU_SG_REL_ CGW_CCU SG_ 1073 RWPC_SWVerMinor1 1500;
BA_ "Version" SG_ 1073 RWPC_SWVerMinor1 "18.10.06";
BA_ "Description" SG_ 1073 WPC_PhnLftWrngRWPCSta "Warning by RWPC for User (Phone left in vehicle)";
BA_ "GenSigSendType" SG_ 1073 WPC_PhnLftWrngRWPCSta 4;
BA_ "UserSigValidity" SG_ 1073 WPC_PhnLftWrngRWPCSta 0;
BA_REL_ "GenSigTimeoutTime" BU_SG_REL_ ATS SG_ 1073 WPC_PhnLftWrngRWPCSta 1500;
BA_REL_ "GenSigTimeoutTime" BU_SG_REL_ CGW_CCU SG_ 1073 WPC_PhnLftWrngRWPCSta 1500;
BA_ "NetworkRequest" SG_ 1073 WPC_PhnLftWrngRWPCSta 0;
BA_ "NetworkRequestHoldingTime" SG_ 1073 WPC_PhnLftWrngRWPCSta 5000;
BA_ "Version" SG_ 1073 WPC_PhnLftWrngRWPCSta "19.10.02";
BA_ "Description" SG_ 1073 RWPC_SWVerMinor2 "Indicate the RWPC software version as follows:

- The software version is displayed in three digits.

- The Major and Minor digits are separated by '.'

- Signal values are transmitted to ASCII codes.



¡Ø Example

RWPC_SWVerMajor1 : 0x41 (HEX) -> ASCII CODE : 'A' 

RWPC_SWVerMinor1 : 0x30 (HEX) -> ASCII CODE : '0'

RWPC_SWVerMinor2 : 0x33 (HEX) -> ASCII CODE : '3'

=> RWPC S/W Ver is displayed 'A.03'";
BA_ "GenSigSendType" SG_ 1073 RWPC_SWVerMinor2 4;
BA_ "UserSigValidity" SG_ 1073 RWPC_SWVerMinor2 0;
BA_REL_ "GenSigTimeoutTime" BU_SG_REL_ CGW_CCU SG_ 1073 RWPC_SWVerMinor2 1500;
BA_ "Version" SG_ 1073 RWPC_SWVerMinor2 "18.10.06";
BA_ "Description" SG_ 1073 USM_ValCmdStaforATS "USM request value of RWPC for ATS";
BA_ "GenSigSendType" SG_ 1073 USM_ValCmdStaforATS 4;
BA_ "UserSigValidity" SG_ 1073 USM_ValCmdStaforATS 0;
BA_REL_ "GenSigTimeoutTime" BU_SG_REL_ ATS SG_ 1073 USM_ValCmdStaforATS 1500;
BA_ "NetworkRequest" SG_ 1073 USM_ValCmdStaforATS 0;
BA_ "NetworkRequestHoldingTime" SG_ 1073 USM_ValCmdStaforATS 5000;
BA_ "Version" SG_ 1073 USM_ValCmdStaforATS "20.07.05";
BA_ "Description" SG_ 1073 RWPC_SWVerMajor1 "Indicate the RWPC software version as follows:

- The software version is displayed in three digits.

- The Major and Minor digits are separated by '.'

- Signal values are transmitted to ASCII codes.



¡Ø Example

RWPC_SWVerMajor1 : 0x41 (HEX) -> ASCII CODE : 'A' 

RWPC_SWVerMinor1 : 0x30 (HEX) -> ASCII CODE : '0'

RWPC_SWVerMinor2 : 0x33 (HEX) -> ASCII CODE : '3'

=> RWPC S/W Ver is displayed 'A.03'";
BA_ "GenSigSendType" SG_ 1073 RWPC_SWVerMajor1 4;
BA_ "UserSigValidity" SG_ 1073 RWPC_SWVerMajor1 0;
BA_REL_ "GenSigTimeoutTime" BU_SG_REL_ CGW_CCU SG_ 1073 RWPC_SWVerMajor1 1500;
BA_ "Version" SG_ 1073 RWPC_SWVerMajor1 "18.10.06";
BA_ "GenMsgCycleTime" BO_ 1567 0;
BA_ "GenMsgCycleTimeFast" BO_ 1567 0;
BA_ "GenMsgNrOfRepetition" BO_ 1567 0;
BA_ "GenMsgILSupport" BO_ 1567 0;
BA_ "TpMessage" BO_ 1567 1;
BA_ "TpTxIndex" BO_ 1567 41;
BA_ "Description" SG_ 1567 TP_BLTN_CAM_NAVI_HU_Byte0 "TP Index : 41";
BA_ "UsrSigPurpose" SG_ 1567 TP_BLTN_CAM_NAVI_HU_Byte0 10;
BA_ "UserSigValidity" SG_ 1567 TP_BLTN_CAM_NAVI_HU_Byte0 0;
BA_REL_ "GenSigTimeoutTime" BU_SG_REL_ CGW_CCU SG_ 1567 TP_BLTN_CAM_NAVI_HU_Byte0 0;
BA_ "NetworkRequest" SG_ 1567 TP_BLTN_CAM_NAVI_HU_Byte0 0;
BA_ "NetworkRequestHoldingTime" SG_ 1567 TP_BLTN_CAM_NAVI_HU_Byte0 5000;
BA_ "Version" SG_ 1567 TP_BLTN_CAM_NAVI_HU_Byte0 "21.05.04";
BA_ "Description" SG_ 1567 TP_BLTN_CAM_NAVI_HU_Byte2 "TP Index : 41";
BA_ "UsrSigPurpose" SG_ 1567 TP_BLTN_CAM_NAVI_HU_Byte2 10;
BA_ "UserSigValidity" SG_ 1567 TP_BLTN_CAM_NAVI_HU_Byte2 0;
BA_REL_ "GenSigTimeoutTime" BU_SG_REL_ CGW_CCU SG_ 1567 TP_BLTN_CAM_NAVI_HU_Byte2 0;
BA_ "NetworkRequest" SG_ 1567 TP_BLTN_CAM_NAVI_HU_Byte2 0;
BA_ "NetworkRequestHoldingTime" SG_ 1567 TP_BLTN_CAM_NAVI_HU_Byte2 5000;
BA_ "Version" SG_ 1567 TP_BLTN_CAM_NAVI_HU_Byte2 "21.05.04";
BA_ "Description" SG_ 1567 TP_BLTN_CAM_NAVI_HU_Byte3 "TP Index : 41";
BA_ "UsrSigPurpose" SG_ 1567 TP_BLTN_CAM_NAVI_HU_Byte3 10;
BA_ "UserSigValidity" SG_ 1567 TP_BLTN_CAM_NAVI_HU_Byte3 0;
BA_REL_ "GenSigTimeoutTime" BU_SG_REL_ CGW_CCU SG_ 1567 TP_BLTN_CAM_NAVI_HU_Byte3 0;
BA_ "NetworkRequest" SG_ 1567 TP_BLTN_CAM_NAVI_HU_Byte3 0;
BA_ "NetworkRequestHoldingTime" SG_ 1567 TP_BLTN_CAM_NAVI_HU_Byte3 5000;
BA_ "Version" SG_ 1567 TP_BLTN_CAM_NAVI_HU_Byte3 "21.05.04";
BA_ "Description" SG_ 1567 TP_BLTN_CAM_NAVI_HU_Byte4 "TP Index : 41";
BA_ "UsrSigPurpose" SG_ 1567 TP_BLTN_CAM_NAVI_HU_Byte4 10;
BA_ "UserSigValidity" SG_ 1567 TP_BLTN_CAM_NAVI_HU_Byte4 0;
BA_REL_ "GenSigTimeoutTime" BU_SG_REL_ CGW_CCU SG_ 1567 TP_BLTN_CAM_NAVI_HU_Byte4 0;
BA_ "NetworkRequest" SG_ 1567 TP_BLTN_CAM_NAVI_HU_Byte4 0;
BA_ "NetworkRequestHoldingTime" SG_ 1567 TP_BLTN_CAM_NAVI_HU_Byte4 5000;
BA_ "Version" SG_ 1567 TP_BLTN_CAM_NAVI_HU_Byte4 "21.05.04";
BA_ "Description" SG_ 1567 TP_BLTN_CAM_NAVI_HU_Byte5 "TP Index : 41";
BA_ "UsrSigPurpose" SG_ 1567 TP_BLTN_CAM_NAVI_HU_Byte5 10;
BA_ "UserSigValidity" SG_ 1567 TP_BLTN_CAM_NAVI_HU_Byte5 0;
BA_REL_ "GenSigTimeoutTime" BU_SG_REL_ CGW_CCU SG_ 1567 TP_BLTN_CAM_NAVI_HU_Byte5 0;
BA_ "NetworkRequest" SG_ 1567 TP_BLTN_CAM_NAVI_HU_Byte5 0;
BA_ "NetworkRequestHoldingTime" SG_ 1567 TP_BLTN_CAM_NAVI_HU_Byte5 5000;
BA_ "Version" SG_ 1567 TP_BLTN_CAM_NAVI_HU_Byte5 "21.05.04";
BA_ "Description" SG_ 1567 TP_BLTN_CAM_NAVI_HU_Byte6 "TP Index : 41";
BA_ "UsrSigPurpose" SG_ 1567 TP_BLTN_CAM_NAVI_HU_Byte6 10;
BA_ "UserSigValidity" SG_ 1567 TP_BLTN_CAM_NAVI_HU_Byte6 0;
BA_REL_ "GenSigTimeoutTime" BU_SG_REL_ CGW_CCU SG_ 1567 TP_BLTN_CAM_NAVI_HU_Byte6 0;
BA_ "NetworkRequest" SG_ 1567 TP_BLTN_CAM_NAVI_HU_Byte6 0;
BA_ "NetworkRequestHoldingTime" SG_ 1567 TP_BLTN_CAM_NAVI_HU_Byte6 5000;
BA_ "Version" SG_ 1567 TP_BLTN_CAM_NAVI_HU_Byte6 "21.05.04";
BA_ "Description" SG_ 1567 TP_BLTN_CAM_NAVI_HU_Byte7 "TP Index : 41";
BA_ "UsrSigPurpose" SG_ 1567 TP_BLTN_CAM_NAVI_HU_Byte7 10;
BA_ "UserSigValidity" SG_ 1567 TP_BLTN_CAM_NAVI_HU_Byte7 0;
BA_REL_ "GenSigTimeoutTime" BU_SG_REL_ CGW_CCU SG_ 1567 TP_BLTN_CAM_NAVI_HU_Byte7 0;
BA_ "NetworkRequest" SG_ 1567 TP_BLTN_CAM_NAVI_HU_Byte7 0;
BA_ "NetworkRequestHoldingTime" SG_ 1567 TP_BLTN_CAM_NAVI_HU_Byte7 5000;
BA_ "Version" SG_ 1567 TP_BLTN_CAM_NAVI_HU_Byte7 "21.05.04";
BA_ "Description" SG_ 1567 TP_BLTN_CAM_NAVI_HU_Byte1 "TP Index : 41";
BA_ "UsrSigPurpose" SG_ 1567 TP_BLTN_CAM_NAVI_HU_Byte1 10;
BA_ "UserSigValidity" SG_ 1567 TP_BLTN_CAM_NAVI_HU_Byte1 0;
BA_REL_ "GenSigTimeoutTime" BU_SG_REL_ CGW_CCU SG_ 1567 TP_BLTN_CAM_NAVI_HU_Byte1 0;
BA_ "NetworkRequest" SG_ 1567 TP_BLTN_CAM_NAVI_HU_Byte1 0;
BA_ "NetworkRequestHoldingTime" SG_ 1567 TP_BLTN_CAM_NAVI_HU_Byte1 5000;
BA_ "Version" SG_ 1567 TP_BLTN_CAM_NAVI_HU_Byte1 "21.05.04";
BA_ "GenMsgCycleTime" BO_ 1566 0;
BA_ "GenMsgCycleTimeFast" BO_ 1566 0;
BA_ "GenMsgNrOfRepetition" BO_ 1566 0;
BA_ "GenMsgILSupport" BO_ 1566 0;
BA_ "TpMessage" BO_ 1566 1;
BA_ "TpTxIndex" BO_ 1566 41;
BA_ "Description" SG_ 1566 TP_HU_NAVI_BLTN_CAM_Byte0 "TP Index : 41";
BA_ "UsrSigPurpose" SG_ 1566 TP_HU_NAVI_BLTN_CAM_Byte0 10;
BA_ "UserSigValidity" SG_ 1566 TP_HU_NAVI_BLTN_CAM_Byte0 0;
BA_REL_ "GenSigTimeoutTime" BU_SG_REL_ BLTN_CAM SG_ 1566 TP_HU_NAVI_BLTN_CAM_Byte0 0;
BA_ "NetworkRequest" SG_ 1566 TP_HU_NAVI_BLTN_CAM_Byte0 0;
BA_ "NetworkRequestHoldingTime" SG_ 1566 TP_HU_NAVI_BLTN_CAM_Byte0 5000;
BA_ "Version" SG_ 1566 TP_HU_NAVI_BLTN_CAM_Byte0 "21.05.04";
BA_ "Description" SG_ 1566 TP_HU_NAVI_BLTN_CAM_Byte2 "TP Index : 41";
BA_ "UsrSigPurpose" SG_ 1566 TP_HU_NAVI_BLTN_CAM_Byte2 10;
BA_ "UserSigValidity" SG_ 1566 TP_HU_NAVI_BLTN_CAM_Byte2 0;
BA_REL_ "GenSigTimeoutTime" BU_SG_REL_ BLTN_CAM SG_ 1566 TP_HU_NAVI_BLTN_CAM_Byte2 0;
BA_ "NetworkRequest" SG_ 1566 TP_HU_NAVI_BLTN_CAM_Byte2 0;
BA_ "NetworkRequestHoldingTime" SG_ 1566 TP_HU_NAVI_BLTN_CAM_Byte2 5000;
BA_ "Version" SG_ 1566 TP_HU_NAVI_BLTN_CAM_Byte2 "21.05.04";
BA_ "Description" SG_ 1566 TP_HU_NAVI_BLTN_CAM_Byte3 "TP Index : 41";
BA_ "UsrSigPurpose" SG_ 1566 TP_HU_NAVI_BLTN_CAM_Byte3 10;
BA_ "UserSigValidity" SG_ 1566 TP_HU_NAVI_BLTN_CAM_Byte3 0;
BA_REL_ "GenSigTimeoutTime" BU_SG_REL_ BLTN_CAM SG_ 1566 TP_HU_NAVI_BLTN_CAM_Byte3 0;
BA_ "NetworkRequest" SG_ 1566 TP_HU_NAVI_BLTN_CAM_Byte3 0;
BA_ "NetworkRequestHoldingTime" SG_ 1566 TP_HU_NAVI_BLTN_CAM_Byte3 5000;
BA_ "Version" SG_ 1566 TP_HU_NAVI_BLTN_CAM_Byte3 "21.05.04";
BA_ "Description" SG_ 1566 TP_HU_NAVI_BLTN_CAM_Byte4 "TP Index : 41";
BA_ "UsrSigPurpose" SG_ 1566 TP_HU_NAVI_BLTN_CAM_Byte4 10;
BA_ "UserSigValidity" SG_ 1566 TP_HU_NAVI_BLTN_CAM_Byte4 0;
BA_REL_ "GenSigTimeoutTime" BU_SG_REL_ BLTN_CAM SG_ 1566 TP_HU_NAVI_BLTN_CAM_Byte4 0;
BA_ "NetworkRequest" SG_ 1566 TP_HU_NAVI_BLTN_CAM_Byte4 0;
BA_ "NetworkRequestHoldingTime" SG_ 1566 TP_HU_NAVI_BLTN_CAM_Byte4 5000;
BA_ "Version" SG_ 1566 TP_HU_NAVI_BLTN_CAM_Byte4 "21.05.04";
BA_ "Description" SG_ 1566 TP_HU_NAVI_BLTN_CAM_Byte5 "TP Index : 41";
BA_ "UsrSigPurpose" SG_ 1566 TP_HU_NAVI_BLTN_CAM_Byte5 10;
BA_ "UserSigValidity" SG_ 1566 TP_HU_NAVI_BLTN_CAM_Byte5 0;
BA_REL_ "GenSigTimeoutTime" BU_SG_REL_ BLTN_CAM SG_ 1566 TP_HU_NAVI_BLTN_CAM_Byte5 0;
BA_ "NetworkRequest" SG_ 1566 TP_HU_NAVI_BLTN_CAM_Byte5 0;
BA_ "NetworkRequestHoldingTime" SG_ 1566 TP_HU_NAVI_BLTN_CAM_Byte5 5000;
BA_ "Version" SG_ 1566 TP_HU_NAVI_BLTN_CAM_Byte5 "21.05.04";
BA_ "Description" SG_ 1566 TP_HU_NAVI_BLTN_CAM_Byte6 "TP Index : 41";
BA_ "UsrSigPurpose" SG_ 1566 TP_HU_NAVI_BLTN_CAM_Byte6 10;
BA_ "UserSigValidity" SG_ 1566 TP_HU_NAVI_BLTN_CAM_Byte6 0;
BA_REL_ "GenSigTimeoutTime" BU_SG_REL_ BLTN_CAM SG_ 1566 TP_HU_NAVI_BLTN_CAM_Byte6 0;
BA_ "NetworkRequest" SG_ 1566 TP_HU_NAVI_BLTN_CAM_Byte6 0;
BA_ "NetworkRequestHoldingTime" SG_ 1566 TP_HU_NAVI_BLTN_CAM_Byte6 5000;
BA_ "Version" SG_ 1566 TP_HU_NAVI_BLTN_CAM_Byte6 "21.05.04";
BA_ "Description" SG_ 1566 TP_HU_NAVI_BLTN_CAM_Byte7 "TP Index : 41";
BA_ "UsrSigPurpose" SG_ 1566 TP_HU_NAVI_BLTN_CAM_Byte7 10;
BA_ "UserSigValidity" SG_ 1566 TP_HU_NAVI_BLTN_CAM_Byte7 0;
BA_REL_ "GenSigTimeoutTime" BU_SG_REL_ BLTN_CAM SG_ 1566 TP_HU_NAVI_BLTN_CAM_Byte7 0;
BA_ "NetworkRequest" SG_ 1566 TP_HU_NAVI_BLTN_CAM_Byte7 0;
BA_ "NetworkRequestHoldingTime" SG_ 1566 TP_HU_NAVI_BLTN_CAM_Byte7 5000;
BA_ "Version" SG_ 1566 TP_HU_NAVI_BLTN_CAM_Byte7 "21.05.04";
BA_ "Description" SG_ 1566 TP_HU_NAVI_BLTN_CAM_Byte1 "TP Index : 41";
BA_ "UsrSigPurpose" SG_ 1566 TP_HU_NAVI_BLTN_CAM_Byte1 10;
BA_ "UserSigValidity" SG_ 1566 TP_HU_NAVI_BLTN_CAM_Byte1 0;
BA_REL_ "GenSigTimeoutTime" BU_SG_REL_ BLTN_CAM SG_ 1566 TP_HU_NAVI_BLTN_CAM_Byte1 0;
BA_ "NetworkRequest" SG_ 1566 TP_HU_NAVI_BLTN_CAM_Byte1 0;
BA_ "NetworkRequestHoldingTime" SG_ 1566 TP_HU_NAVI_BLTN_CAM_Byte1 5000;
BA_ "Version" SG_ 1566 TP_HU_NAVI_BLTN_CAM_Byte1 "21.05.04";
BA_ "GenMsgSendType" BO_ 2160080129 0;
BA_ "GenMsgCycleTime" BO_ 2160080129 50;
BA_ "GenMsgCycleTimeFast" BO_ 2160080129 0;
BA_ "GenMsgNrOfRepetition" BO_ 2160080129 0;
BA_ "VFrameFormat" BO_ 2160080129 1;
BA_ "Description" SG_ 2160080129 VCU_Crc1Val "The data area for CRC calculation is based on the data length (DLC) of the message DB.

The CRC shall be calculated over the entire data block (excluding the CRC bytes) including the user data, alive counter and Data ID

 

- CRC Polynomial (0x1021) , Initial Value : 0xFFFF, XOR value : 0x0000, Data ID : Message ID + 0xF800 

- The initial value is for CRC calculation and the message should be sent with the calculated result value. 

- The mathematical expression to 16 bit CRC polynomial is given here. G(x) = x16 + x12 + x5 + 1";
BA_ "GenSigStartValue" SG_ 2160080129 VCU_Crc1Val 65535;
BA_ "UserSigValidity" SG_ 2160080129 VCU_Crc1Val 7;
BA_ "RoutingFactor" SG_ 2160080129 VCU_Crc1Val 5;
BA_ "Version" SG_ 2160080129 VCU_Crc1Val "20.07.05";
BA_ "Description" SG_ 2160080129 VCU_AlvCnt1Val "For the first transmission request for a data element the counter shall be initialized with 0 and shall be incremented by 1 for every subsequent send request. 

When the counter reaches the maximum value(0xFF), then it shall restart with 0 for the next send request";
BA_ "UserSigValidity" SG_ 2160080129 VCU_AlvCnt1Val 7;
BA_ "RoutingFactor" SG_ 2160080129 VCU_AlvCnt1Val 5;
BA_ "Version" SG_ 2160080129 VCU_AlvCnt1Val "20.07.05";
BA_ "Description" SG_ 2160080129 VCU_RdySta "VCU Ready";
BA_ "UserSigValidity" SG_ 2160080129 VCU_RdySta 7;
BA_ "RoutingFactor" SG_ 2160080129 VCU_RdySta 5;
BA_ "Version" SG_ 2160080129 VCU_RdySta "20.04.05";
BA_ "Description" SG_ 2160080129 VCU_StartKeyHoldSta "Start Key Hold Signal";
BA_ "UserSigValidity" SG_ 2160080129 VCU_StartKeyHoldSta 7;
BA_ "RoutingFactor" SG_ 2160080129 VCU_StartKeyHoldSta 5;
BA_ "Version" SG_ 2160080129 VCU_StartKeyHoldSta "20.04.05";
BA_ "Description" SG_ 2160080129 VCU_EvDrvRdySta "EV Ready";
BA_ "UserSigValidity" SG_ 2160080129 VCU_EvDrvRdySta 7;
BA_ "RoutingFactor" SG_ 2160080129 VCU_EvDrvRdySta 5;
BA_ "Version" SG_ 2160080129 VCU_EvDrvRdySta "20.04.05";
BA_ "Description" SG_ 2160080129 VCU_MotPwrEnReq "Motor Power Enable";
BA_ "UserSigValidity" SG_ 2160080129 VCU_MotPwrEnReq 7;
BA_ "RoutingFactor" SG_ 2160080129 VCU_MotPwrEnReq 5;
BA_ "Version" SG_ 2160080129 VCU_MotPwrEnReq "20.04.05";
BA_ "Description" SG_ 2160080129 VCU_GearPosSta "Gear Position Status";
BA_ "GenSigStartValue" SG_ 2160080129 VCU_GearPosSta 9;
BA_ "UserSigValidity" SG_ 2160080129 VCU_GearPosSta 7;
BA_ "RoutingFactor" SG_ 2160080129 VCU_GearPosSta 5;
BA_ "Version" SG_ 2160080129 VCU_GearPosSta "21.05.01";
BA_ "Description" SG_ 2160080129 VCU_LdcInhReq "LDC Output Inhibit Request";
BA_ "GenSigStartValue" SG_ 2160080129 VCU_LdcInhReq 1;
BA_ "UserSigValidity" SG_ 2160080129 VCU_LdcInhReq 7;
BA_ "RoutingFactor" SG_ 2160080129 VCU_LdcInhReq 5;
BA_ "Version" SG_ 2160080129 VCU_LdcInhReq "20.04.05";
BA_ "Description" SG_ 2160080129 VCU_MainRlyOffReq "Main Relay Cut off Request";
BA_ "UserSigValidity" SG_ 2160080129 VCU_MainRlyOffReq 7;
BA_ "RoutingFactor" SG_ 2160080129 VCU_MainRlyOffReq 5;
BA_ "Version" SG_ 2160080129 VCU_MainRlyOffReq "20.04.05";
BA_ "Description" SG_ 2160080129 VCU_AccPedDepVal "Accelerator Pedal Depth Value";
BA_ "UserSigValidity" SG_ 2160080129 VCU_AccPedDepVal 7;
BA_ "RoutingFactor" SG_ 2160080129 VCU_AccPedDepVal 5;
BA_ "Version" SG_ 2160080129 VCU_AccPedDepVal "20.04.05";
BA_ "Description" SG_ 2160080129 VCU_FatcOperPermSta "Climate Operating Permission";
BA_ "UserSigValidity" SG_ 2160080129 VCU_FatcOperPermSta 7;
BA_ "RoutingFactor" SG_ 2160080129 VCU_FatcOperPermSta 5;
BA_ "Version" SG_ 2160080129 VCU_FatcOperPermSta "20.04.05";
BA_ "Description" SG_ 2160080129 VCU_DrvCycSta "Driving Cycle Status";
BA_ "UserSigValidity" SG_ 2160080129 VCU_DrvCycSta 7;
BA_ "RoutingFactor" SG_ 2160080129 VCU_DrvCycSta 5;
BA_ "Version" SG_ 2160080129 VCU_DrvCycSta "20.04.05";
BA_ "Description" SG_ 2160080129 VCU_CltActOpSta "Clutch Actuator Operating Status";
BA_ "UserSigValidity" SG_ 2160080129 VCU_CltActOpSta 7;
BA_ "RoutingFactor" SG_ 2160080129 VCU_CltActOpSta 5;
BA_ "Version" SG_ 2160080129 VCU_CltActOpSta "20.04.05";
BA_ "Description" SG_ 2160080129 VCU_WhlSpdSnsrAlvReq "Alive Request for Wheel Speed Sensors";
BA_ "UserSigValidity" SG_ 2160080129 VCU_WhlSpdSnsrAlvReq 7;
BA_ "RoutingFactor" SG_ 2160080129 VCU_WhlSpdSnsrAlvReq 5;
BA_ "Version" SG_ 2160080129 VCU_WhlSpdSnsrAlvReq "20.04.05";
BA_ "Description" SG_ 2160080129 VCU_DrvModOpSta "VCU's operating drive mode according to CLU and DMIC signals";
BA_ "UserSigValidity" SG_ 2160080129 VCU_DrvModOpSta 7;
BA_ "RoutingFactor" SG_ 2160080129 VCU_DrvModOpSta 5;
BA_ "Version" SG_ 2160080129 VCU_DrvModOpSta "20.08.07";
BA_ "Description" SG_ 2160080129 VCU_IgOffGearPosStaDispReq "Gear position display request @ Ig Off (to CLU )";
BA_ "UserSigValidity" SG_ 2160080129 VCU_IgOffGearPosStaDispReq 7;
BA_ "RoutingFactor" SG_ 2160080129 VCU_IgOffGearPosStaDispReq 5;
BA_ "Version" SG_ 2160080129 VCU_IgOffGearPosStaDispReq "20.12.04";
BA_ "GenMsgSendType" BO_ 2160080131 0;
BA_ "GenMsgCycleTime" BO_ 2160080131 50;
BA_ "GenMsgCycleTimeFast" BO_ 2160080131 0;
BA_ "GenMsgNrOfRepetition" BO_ 2160080131 0;
BA_ "VFrameFormat" BO_ 2160080131 1;
BA_ "Description" SG_ 2160080131 VCU_EcmSeqSta "This signal is VCU System Status Information.";
BA_ "UserSigValidity" SG_ 2160080131 VCU_EcmSeqSta 7;
BA_ "RoutingFactor" SG_ 2160080131 VCU_EcmSeqSta 5;
BA_ "Version" SG_ 2160080131 VCU_EcmSeqSta "20.04.05";
BA_ "Description" SG_ 2160080131 VCU_CltActDiagSta "Clutch Actuator Diag Code";
BA_ "UserSigValidity" SG_ 2160080131 VCU_CltActDiagSta 7;
BA_ "RoutingFactor" SG_ 2160080131 VCU_CltActDiagSta 5;
BA_ "Version" SG_ 2160080131 VCU_CltActDiagSta "20.04.05";
BA_ "Description" SG_ 2160080131 VCU_CltActDrvCrntVal "Clutch Actuator Drive Current";
BA_ "UserSigValidity" SG_ 2160080131 VCU_CltActDrvCrntVal 7;
BA_ "RoutingFactor" SG_ 2160080131 VCU_CltActDrvCrntVal 5;
BA_ "Version" SG_ 2160080131 VCU_CltActDrvCrntVal "20.04.05";
BA_ "Description" SG_ 2160080131 VCU_CltActPosStrokeVal "Clutch Actuator Position Stroke";
BA_ "UserSigValidity" SG_ 2160080131 VCU_CltActPosStrokeVal 7;
BA_ "RoutingFactor" SG_ 2160080131 VCU_CltActPosStrokeVal 5;
BA_ "Version" SG_ 2160080131 VCU_CltActPosStrokeVal "20.04.05";
BA_ "Description" SG_ 2160080131 VCU_MainBattTypeSta "Main Battery Type";
BA_ "UserSigValidity" SG_ 2160080131 VCU_MainBattTypeSta 7;
BA_ "RoutingFactor" SG_ 2160080131 VCU_MainBattTypeSta 5;
BA_ "Version" SG_ 2160080131 VCU_MainBattTypeSta "20.08.07";
BA_ "Description" SG_ 2160080131 VCU_MainBattTypeLrnSta "Learn Status of Main Batt. Type";
BA_ "UserSigValidity" SG_ 2160080131 VCU_MainBattTypeLrnSta 7;
BA_ "RoutingFactor" SG_ 2160080131 VCU_MainBattTypeLrnSta 5;
BA_ "Version" SG_ 2160080131 VCU_MainBattTypeLrnSta "20.04.05";
BA_ "Description" SG_ 2160080131 VCU_WarmupCycSta "Warm-up Cycle Status Flag for FRF output to other ECU's";
BA_ "UserSigValidity" SG_ 2160080131 VCU_WarmupCycSta 7;
BA_ "RoutingFactor" SG_ 2160080131 VCU_WarmupCycSta 5;
BA_ "Version" SG_ 2160080131 VCU_WarmupCycSta "20.04.05";
BA_ "Description" SG_ 2160080131 VCU_FatcPermPwrVal "Climate Permission Power";
BA_ "UserSigValidity" SG_ 2160080131 VCU_FatcPermPwrVal 7;
BA_ "RoutingFactor" SG_ 2160080131 VCU_FatcPermPwrVal 5;
BA_ "Version" SG_ 2160080131 VCU_FatcPermPwrVal "20.04.05";
BA_ "UserSigValidity" SG_ 2160080131 VCU_EcmDiagSta 7;
BA_ "RoutingFactor" SG_ 2160080131 VCU_EcmDiagSta 5;
BA_ "Version" SG_ 2160080131 VCU_EcmDiagSta "20.04.05";
BA_ "GenMsgSendType" BO_ 2160080132 0;
BA_ "GenMsgCycleTime" BO_ 2160080132 50;
BA_ "GenMsgCycleTimeFast" BO_ 2160080132 0;
BA_ "GenMsgNrOfRepetition" BO_ 2160080132 0;
BA_ "VFrameFormat" BO_ 2160080132 1;
BA_ "Description" SG_ 2160080132 VCU_GearPosStaDisp "Gear Position Status for CLU display";
BA_ "GenSigStartValue" SG_ 2160080132 VCU_GearPosStaDisp 9;
BA_ "UserSigValidity" SG_ 2160080132 VCU_GearPosStaDisp 7;
BA_ "RoutingFactor" SG_ 2160080132 VCU_GearPosStaDisp 5;
BA_ "Version" SG_ 2160080132 VCU_GearPosStaDisp "20.12.04";
BA_ "UserSigValidity" SG_ 2160080132 VCU_PdwLmtOperSta 7;
BA_ "RoutingFactor" SG_ 2160080132 VCU_PdwLmtOperSta 5;
BA_ "Version" SG_ 2160080132 VCU_PdwLmtOperSta "21.12.00";
BA_ "UserSigValidity" SG_ 2160080132 VCU_PdwLmtBrkRequest 7;
BA_ "RoutingFactor" SG_ 2160080132 VCU_PdwLmtBrkRequest 5;
BA_ "Version" SG_ 2160080132 VCU_PdwLmtBrkRequest "21.12.00";
BA_ "Description" SG_ 2160080132 VCU_VgsVirSoundBackFireIndex "Virtual sound back fire noise index for VGS mode";
BA_ "UserSigValidity" SG_ 2160080132 VCU_VgsVirSoundBackFireIndex 7;
BA_ "RoutingFactor" SG_ 2160080132 VCU_VgsVirSoundBackFireIndex 5;
BA_ "Version" SG_ 2160080132 VCU_VgsVirSoundBackFireIndex "21.12.02";
BA_ "Description" SG_ 2160080132 VCU_VgsVirEngSpdRpmVal "Virtual engine speed for VGS mode";
BA_ "UserSigValidity" SG_ 2160080132 VCU_VgsVirEngSpdRpmVal 7;
BA_ "RoutingFactor" SG_ 2160080132 VCU_VgsVirEngSpdRpmVal 5;
BA_ "Version" SG_ 2160080132 VCU_VgsVirEngSpdRpmVal "21.12.02";
BA_ "Description" SG_ 2160080132 VCU_PdlStopCtrlSta "Cooperative control state of VCU for stop assist control with IEB";
BA_ "UserSigValidity" SG_ 2160080132 VCU_PdlStopCtrlSta 7;
BA_ "RoutingFactor" SG_ 2160080132 VCU_PdlStopCtrlSta 5;
BA_ "Version" SG_ 2160080132 VCU_PdlStopCtrlSta "21.08.08";
BA_ "Description" SG_ 2160080132 VCU_VgsVirSoundVolume "Virtual engine sound volume for VGS mode[%]";
BA_ "UserSigValidity" SG_ 2160080132 VCU_VgsVirSoundVolume 7;
BA_ "RoutingFactor" SG_ 2160080132 VCU_VgsVirSoundVolume 5;
BA_ "Version" SG_ 2160080132 VCU_VgsVirSoundVolume "21.12.02";
BA_ "Description" SG_ 2160080132 VCU_VgsVirGearStep "Shift gear when entering VGS mode";
BA_ "UserSigValidity" SG_ 2160080132 VCU_VgsVirGearStep 7;
BA_ "RoutingFactor" SG_ 2160080132 VCU_VgsVirGearStep 5;
BA_ "Version" SG_ 2160080132 VCU_VgsVirGearStep "21.12.02";
BA_ "Description" SG_ 2160080132 VCU_PdlStopReqTqNmVal "Requested brake torque for cooperative stop assist control";
BA_ "UserSigValidity" SG_ 2160080132 VCU_PdlStopReqTqNmVal 7;
BA_ "RoutingFactor" SG_ 2160080132 VCU_PdlStopReqTqNmVal 5;
BA_ "Version" SG_ 2160080132 VCU_PdlStopReqTqNmVal "21.08.08";
VAL_ 1546 AMP_SupportBeepVolumeControl 0 "Null" 1 "False" 2 "True" 3 "Invalid" ;
VAL_ 1546 AMP_SupportESEVMode 0 "Null" 1 "False" 2 "True" 3 "Invalid" ;
VAL_ 1546 AMP_SupportDSC 0 "Null" 1 "False" 2 "True" 3 "Invalid" ;
VAL_ 1546 AMP_SupportANCMode 0 "Null" 1 "False" 2 "True" 3 "Invalid" ;
VAL_ 1546 AMP_MakerID 0 "Initial Value" 1 "Mobis" 2 "Beats by Dr.Dre" 3 "Harman_Becker" 4 "BOSE" 5 "Bang&Olufsen" 6 "Meridian" 7 "0x07~0xFF:Invalid" 255 "0x07~0xFF:Invalid" ;
VAL_ 1546 AMP_SupportQLS 0 "Null" 1 "False" 2 "True" 3 "Invalid" ;
VAL_ 1546 AMP_SupportQLS_2step 0 "Null" 1 "False" 2 "True" 3 "Invalid" ;
VAL_ 1546 AMP_SupportHorizon 0 "Null" 1 "False" 2 "True" 3 "Invalid" ;
VAL_ 1546 AMP_SupportASDMode 0 "Null" 1 "False" 2 "True" 3 "Invalid" ;
VAL_ 1546 AMP_SupportIntelliQ 0 "Null" 1 "False" 2 "True" 3 "Invalid" ;
VAL_ 1546 AMP_SupportCenterpoint 0 "Null" 1 "False" 2 "True" 3 "Invalid" ;
VAL_ 1546 AMP_SupportSignalDoctor 0 "Null" 1 "False" 2 "True" 3 "Invalid" ;
VAL_ 1546 AMP_SupportLiveDynamicMode 0 "Null" 1 "False" 2 "True(Off On)" 3 "True(Off Natural Concert)" 4 "Reserved" 5 "Reserved" 6 "Reserved" 7 "Invalid" ;
VAL_ 1546 AMP_Support_ElecSound 0 "Null" 1 "False" 2 "True" 3 "Invalid" ;
VAL_ 591 ATS_RLStSldFwdBtn 0 "Default" 1 "Off" 2 "On" 3 "Reserved" ;
VAL_ 591 ATS_RLStSldBwdBtn 0 "Default" 1 "Off" 2 "On" 3 "Reserved" ;
VAL_ 591 ATS_RLStRclFwdBtn 0 "Default" 1 "Off" 2 "On" 3 "Reserved" ;
VAL_ 591 ATS_RLStRclBwdBtn 0 "Default" 1 "Off" 2 "On" 3 "Reserved" ;
VAL_ 591 ATS_RLStTltUpBtn 0 "Default" 1 "Off" 2 "On" 3 "Reserved" ;
VAL_ 591 ATS_RLStTltDnBtn 0 "Default" 1 "Off" 2 "On" 3 "Reserved" ;
VAL_ 591 ATS_RLStHRestUpBtn 0 "Default" 1 "Off" 2 "On" 3 "Reserved" ;
VAL_ 591 ATS_RLStHRestDnBtn 0 "Default" 1 "Off" 2 "On" 3 "Reserved" ;
VAL_ 591 ATS_RLStHRestFwdBtn 0 "Default" 1 "Off" 2 "On" 3 "Reserved" ;
VAL_ 591 ATS_RLStHRestBwdBtn 0 "Default" 1 "Off" 2 "On" 3 "Reserved" ;
VAL_ 591 ATS_RLStLegRestUpBtn 0 "Default" 1 "Off" 2 "On" 3 "Reserved" ;
VAL_ 591 ATS_RStLegRestDnBtn 0 "Default" 1 "Off" 2 "On" 3 "Reserved" ;
VAL_ 591 ATS_RLStLegRestExtUpBtn 0 "Default" 1 "Off" 2 "On" 3 "Reserved" ;
VAL_ 591 ATS_RLStLegRestExtDnBtn 0 "Default" 1 "Off" 2 "On" 3 "Reserved" ;
VAL_ 591 ATS_RLStShoulderADJFwdBtn 0 "Default" 1 "Off" 2 "On" 3 "Reserved" ;
VAL_ 591 ATS_RLStShoulderADJBwdBtn 0 "Default" 1 "Off" 2 "On" 3 "Reserved" ;
VAL_ 1058 Wiper_PrkngPosSta 0 "else" 1 "Parking Position" 2 "Not Used" 3 "Error Indicator" ;
VAL_ 1058 Wiper_RainSnsrOptionTyp 0 "Non Rain Sensor Option" 1 "Rain Sensor Option" 2 "Not Used" 3 "Error Indicator" ;
VAL_ 1058 Wiper_RainSnsrSta 0 "OFF" 1 "Rain Detected" 2 "Low" 3 "High" 4 "Fault 1" 5 "Reserved" 6 "Reserved" 7 "Reserved" 8 "Reserved" 9 "Reserved" 10 "Reserved" 11 "Reserved" 12 "Reserved" 13 "Reserved" 14 "Not Used" 15 "Error Indicator" ;
VAL_ 1058 Wiper_HtWshNzzlCmd 0 "Off" 1 "On" 2 "Not Used" 3 "Error Indicator" ;
VAL_ 1058 BCM_GearPosPSta 0 "Off" 1 "P" 2 "Not Used" 3 "Error Indicator" ;
VAL_ 1058 BCM_SunRoofOpnSta 0 "Close" 1 "Open" 2 "Not Used" 3 "Error Indicator" ;
VAL_ 1058 SunRoof_RrBlindErrSta 0 "No error" 1 "Thermal Protection Active" 2 "Initialized Status" 3 "Undefined ECU Error" 4 "Switch Error" 5 "Voltage error" 6 "Complex Error" 7 "Invalid" ;
VAL_ 1058 Wiper_AutoWashModeSta 0 "Auto Wash Mode Off" 1 "Auto Wash Mode On" 2 "Not Used" 3 "Error Indicator" ;
VAL_ 2357404929 BMS_Crc6Val 65535 "Signal Invalid (Message with unused CRC. CRC signal is transmitted fixed value)" ;
VAL_ 2357404929 BMS_AlvCnt6Val 255 "Signal Invalid (Message with unused Alive counter. Alive counter signal is transmitted fixed value)" ;
VAL_ 2357404929 CHRG_StndChrgConnSta_120V 0 "Not Connected" 1 "Connected" 2 "Not used" 3 "Error indicator" ;
VAL_ 2357404929 CHRG_StndChrgSta 0 "None" 1 "Standard Charging" 2 "Not used" 3 "Error indicator" ;
VAL_ 2357404929 CHRG_ChrgCycStrtSta 0 "Charging Cycle Start Disable" 1 "Charging Cycle Start Enable" 2 "Not used" 3 "Error indicator" ;
VAL_ 2357404929 CHRG_FulChrgSta 0 "None" 1 "Fully Charged" 2 "Not used" 3 "Error indicator" ;
VAL_ 2357404929 CHRG_ChrgSta 0 "None" 1 "Charging" 2 "Not used" 3 "Error indicator" ;
VAL_ 2357404929 CHRG_SpplmntChrgSta 0 "Not operating" 1 "operation" 2 "complete" 3 "fail" ;
VAL_ 2357404929 CHRG_LdcInhbtReq 0 "Noraml" 1 "LDC Inhibit" 2 "Not used" 3 "Error indicator" ;
VAL_ 2357404929 CHRG_NorChgFnshSta 0 "normal" 1 "abnormal finish by OBC" 2 "abnormal finish by BMS" 3 "abnormal finish by others" ;
VAL_ 2357404929 CHRG_ChrgFnshSta 0 "Normal" 1 "Charge finished" 2 "Not used" 3 "Error indicator" ;
VAL_ 2357404929 CHRG_Ig3RlyOffReq 0 "Not Request" 1 "Request" 2 "Not used" 3 "Error indicator" ;
VAL_ 2357404929 CHRG_PShftChgSta 0 "Normal" 1 "P Shift For Charging" 2 "Not used" 3 "Error indicator" ;
VAL_ 2357404929 CHRG_PilotFlSta 0 "Normal" 1 "Notify Pilotline Fail" 2 "Not used" 3 "Error indicator" ;
VAL_ 2357404930 CHRG_ObcRlyOnSta 0 "Off" 1 "On" 2 "Not used" 3 "Error indicator" ;
VAL_ 2357404930 CHRG_NrmlOpSta 0 "Normal(repetitive change), Abnormal(fixed)" 1 "Normal(repetitive change), Abnormal(fixed)" ;
VAL_ 2357404930 CHRG_ChgLamp_1EA 0 "no connection" 1 "charging" 2 "charge completion" 3 "charging fail" 4 "reservation mode" ;
VAL_ 2357404932 CHRG_ChrgLmp_3EA 0 "Normal" 1 "Main Rly On Status On" 2 "SOC 0~35%" 3 "SOC 35~65%" 4 "SOC 65%~" 5 "Chargnig Complete" 6 "Charging Fail" 7 "Reservation Charging,OBC standby mode" ;
VAL_ 1079 CTM_TrailerAct 0 "Not Connected" 1 "Connected" 2 "Reserved" 3 "Invaild" ;
VAL_ 1079 CTM_ExtTailLmpLftOpnSta 0 "Normal" 1 "Open Status" 2 "Not Used" 3 "Error Indicator" ;
VAL_ 1079 CTM_ExtTailLmpRtOpnSta 0 "Normal" 1 "Open Status" 2 "Not Used" 3 "Error Indicator" ;
VAL_ 1079 CTM_Exra_EbrakSta 0 "Off" 1 "On" 2 "Not Used" 3 "Error Indicator" ;
VAL_ 1079 CTM_RearfogAct 0 "Off" 1 "On" 2 "Reserved" 3 "Invaild" ;
VAL_ 1079 CTM_StpLmpOpnSta 0 "Normal" 1 "Open Status" 2 "Not Used" 3 "Error Indicator" ;
VAL_ 1079 CTM_TrnSigLmpLftOpnSta 0 "Normal" 1 "Open Status" 2 "Not Used" 3 "Error Indicator" ;
VAL_ 1079 CTM_TrnSigLmpRtOpnSta 0 "Normal" 1 "Open Status" 2 "Not Used" 3 "Error Indicator" ;
VAL_ 2424579841 DATC_TnnlClimtUSMSta 0 "Default" 1 "OFF" 2 "ON" 3 "Error Indicator" ;
VAL_ 2424579841 DATC_ProximitySnsrSta 0 "Default(Not Apply)" 1 "OFF" 2 "ON" 3 "Error Indicator" ;
VAL_ 2424579841 DATC_TunnelFuncOff4AutoDfgReq 0 "Default" 1 "Tunnel Turn off" 2 "Not Used" 3 "Error Indicator" ;
VAL_ 2424579841 DATC_RrCtlLckSta 0 "Default" 1 "Rear Lock OFF" 2 "Rear Lock ON" 3 "Error Indicator" ;
VAL_ 2424579841 DATC_DrvrStHtrUSMSta 0 "NOT APPLY" 1 "OFF" 2 "ON" 3 "Error Indicator" ;
VAL_ 2424579841 DATC_InDrctVntUSMSta 0 "Default" 1 "InDirectVent USM OFF" 2 "InDirectVent USM ON" 3 "Invalid" ;
VAL_ 2424579841 DATC_WshFldUSMSta 0 "Default" 1 "OFF" 2 "ON" 3 "Invalid" ;
VAL_ 2424579841 DATC_DfgLgcUSMSta 0 "Default" 1 "OFF" 2 "ON" 3 "Invalid" ;
VAL_ 2424579841 DATC_AutoFrshUSMSta 0 "Default" 1 "OFF" 2 "ON" 3 "Invalid" ;
VAL_ 2424579841 DATC_HptIntnstySta 0 "Default" 1 "Haptic OFF" 2 "Haptic Intensity Level 1" 3 "Haptic Intensity Level 2" 4 "Haptic Intensity Level 3" 5 "Haptic Intensity Level 4" 6 "Haptic Intensity Level 5" 7 "Reserved" 8 "Reserved" 9 "Reserved" 10 "Reserved" 11 "Reserved" 12 "Reserved" 13 "Reserved" 14 "Reserved" 15 "Invalid" ;
VAL_ 1085 DLBCU_ActiveDis 0 "Default" 1 "Off" 2 "Mode1" 3 "Mode2" 4 "Mode3" 5 "Reserved" 6 "Reserved" 7 "Invalid" ;
VAL_ 1085 DLBCU_CushSoftSta 0 "Default" 1 "High(Soft)" 2 "Middle(Mid)" 3 "Low(Hard)" 4 "Reserved" 5 "Reserved" 6 "Off" 7 "Invalid" ;
VAL_ 1085 DLBCU_CellOpt 0 "Default" 1 "3Cell" 2 "5Cell" 3 "7Cell" 4 "Invalid" 5 "Invalid" 6 "Invalid" 7 "Invalid" ;
VAL_ 1085 DLBCU_BodySpprtSta 0 "Default" 1 "Off" 2 "On" 3 "Invalid" ;
VAL_ 1085 DLBCU_BodySpprtDis 0 "Default" 1 "Off" 2 "On" 3 "Invalid" ;
VAL_ 1085 DLBCU_SmartCtrl_Set_Rvalue 0 "Init" 1 "Off" 2 "10min" 3 "20min" 4 "30min" 5 "40min" 6 "50min" 7 "60min" 8 "Unused" 9 "Unused" 10 "Unused" 11 "Unused" 12 "Unused" 13 "Unused" 14 "Unused" 15 "Invalid" ;
VAL_ 1085 DLBCU_DrvModUSMSta 0 "Default" 1 "Off" 2 "On" 3 "Invalid" ;
VAL_ 1085 DLBCU_ActiveStrSta 0 "Default" 1 "Normal" 2 "Intensity" 3 "Invalid" ;
VAL_ 1085 DLBCU_ActiveTimeSta 0 "Default" 1 "10min" 2 "15min" 3 "20min" 4 "Reserved" 5 "Reserved" 6 "Reserved" 7 "Invalid" ;
VAL_ 2164278529 HTCU_TrgtGearSta 0 "If N or P are detected(No frictional conncetion)" 1 "1st speed" 2 "2nd speed" 3 "3rd speed" 4 "4th speed" 5 "5th speed" 6 "6th speed" 7 "Reverse" 15 "--" ;
VAL_ 2164278529 HTCU_RdySta 0 "Not ready" 1 "Ready" 2 "Not used" 3 "Error Indicator" ;
VAL_ 2164278529 HTCU_GearChgSta 0 "Inactive" 1 "Active" 2 "Not used" 3 "Error Indicator" ;
VAL_ 2164278529 HTCU_FltSta 0 "No fault" 1 "TCU Diagnostic failure" 2 "Not used" 3 "TCU Diagnostic failure & Limphome activated" 4 "OPU/EOP Diagnostic failure" 5 "TCU & OPU/EOP Diagnostic failure" 6 "Not used" 7 "TCU/OPU Diagnostic failure & Limphome activated" ;
VAL_ 2164278529 HTCU_GearSlctrDis 0 "P" 1 "L" 2 "2" 3 "3" 4 "DS Mode" 5 "D" 6 "N" 7 "R" 8 "Sports mode / Manual Shift" 9 "Not display at Cluster" 10 "Sub-Rom Communication" 11 "Sub-Rom Communication Error" 12 "Paddle shift (D-Position)" 13 "Not used" 14 "Intermediate Position" 15 "Fault" ;
VAL_ 2164278529 HTCU_FanCtrlReq 0 "Not Request" 1 "Request" 2 "Not Used" 3 "Error Indicator" ;
VAL_ 2164278530 HTCU_TrgtShftClsCCanSta 0 "NO SHIFT" 1 "PON UP" 2 "POF UP" 3 "PON DN@HIGH SPEED(Not Used)" 4 "PON DN@LOW SPEED" 5 "POF DN" 6 "NSTP TO 5/4/3/2" 7 "NSTP TO 1" 8 "LOW_VSP SFT12" 9 "N-D 12" 10 "N-D 3456" 11 "N-D5(NOT USED)" 12 "N-R" 13 "N-N" 14 "PON DN WOT SHIFT (NOT USED)" 15 "PON DN SEMI SHIFT" 16 "D-N/R-N" 17 "RESERVED" 18 "RESERVED" 19 "RESERVED" 20 "FAILSAFE 2-3-4 SHIFT" 21 "RESERVED" 22 "RESERVED" 23 "RESERVED" 24 "RESERVED" 25 "RESERVED" 26 "RESERVED" 27 "RESERVED" 28 "RESERVED" 29 "RESERVED" 30 "RESERVED" 31 "RESERVED" ;
VAL_ 2164278530 HTCU_CtrlablSta 0 "Not ready" 1 "TCU Controllable" 2 "Not Used" 3 "Error Indicator" ;
VAL_ 2164278530 HTCU_PrgrmSta 0 "PR_NML" 1 "PR_MED" 2 "PR_SPTY" 3 "PR_LD1" 4 "PR_LD2" 5 "PR_LD3" 6 "PR_DLD" 7 "PR_LD1_H" 8 "PR_LD2_H" 9 "PR_LD3_H" 10 "PR_PRT" 11 "PR_WRM_UP" 12 "PR_BLUE" 13 "PR_ECO_ATC" 14 "PR_LD_ATC" 15 "PR_LD_ATC_H" 16 "PR_HWY" 17 "PR_SOL_L" 18 "PR_SOL_M" 19 "PR_SOL_H" 20 "PR_REGEN" 21 "PR_TF_LO" 22 "PR_TCS" 23 "PR_LD_TCS" 24 "PR_DS" 25 "PR_EV_BLUE" 26 "PR_EV_NML" 27 "PR_EV_SOC_H" 28 "PR_EV_SOC_L" 29 "PR_EV_HWY" 30 "PR_SOS" 31 "PR_ECO_ATC_EV" 32 "PR_LD_ATC_EV" 33 "PR_LD_ATC_HI_EV" 34 "PR_LD2_ATC" 35 "PR_LD3_ATC" 36 "PR_LD2_ATC_H" 37 "PR_LD3_ATC_H" 38 "PR_EC_PRT" ;
VAL_ 2164278530 HTCU_FsCltchLmphmActvSta 0 "Inactive" 1 "Active" 2 "Not used" 3 "Error Indicator" ;
VAL_ 2164278531 HTCU_RapidKDReq 0 "Inactive" 1 "Active" 2 "Not used" 3 "Error Indicator" ;
VAL_ 2164278531 HTCU_CurrGearSta 0 "If N or P are detected(No frictional conncetion)" 1 "1st speed" 2 "2nd speed" 3 "3rd speed" 4 "4th speed" 5 "5th speed" 6 "6th speed" 7 "Reverse" 8 "--" 15 "--" ;
VAL_ 2164278531 HTCU_GearShftUpDisGSI 0 "Gear Shiftup Display Off" 1 "Gear Shiftup Display On" 2 "Not used" 3 "Error Indicator" ;
VAL_ 2164278531 HTCU_GearShftDnDisGSI 0 "Gear Shiftdown Display Off" 1 "Gear Shiftdown Display On" 2 "Not used" 3 "Error Indicator" ;
VAL_ 2164278531 HTCU_TrgtGearStaGSI 0 "--" 1 "1st speed" 2 "2nd speed" 3 "3rd speed" 4 "4th speed" 5 "5th speed" 6 "6th speed" 7 "--" 8 "--" 9 "--" ;
VAL_ 2164278531 HTCU_SolBSta 0 "OFF" 1 "ON" 2 "Not used" 3 "Error Indicator" ;
VAL_ 2281833730 DMIC_EcsModSta 0 "0FF" 1 "ON" 2 "Comfort(Normal)" 3 "Comfort+(Comfort)" 4 "ECO" 5 "Sport" 6 "Sport+" 7 "Smart" 8 "VIP" 9 "Baby" 10 "Snow" 11 "Retro" 12 "Not used" 13 "Not used" 14 "Not used" 15 "Error Indicator" ;
VAL_ 2281833730 DMIC_IndAwdModSta 0 "0FF" 1 "ON" 2 "Comfort(Normal)" 3 "Comfort+(Comfort)" 4 "ECO" 5 "Sport" 6 "Sport+" 7 "Smart" 8 "Not used" 9 "Not used" 10 "Not used" 11 "Not used" 12 "Not used" 13 "Not used" 14 "Not used" 15 "Error Indicator" ;
VAL_ 2281833730 DMIC_RevModSta 0 "0FF" 1 "ON" 2 "Comfort(Normal)" 3 "Comfort+(Comfort)" 4 "ECO" 5 "Sport" 6 "Sport+" 7 "Smart" 8 "VIP" 9 "Baby" 10 "Snow" 11 "Retro" 12 "Not used" 13 "Not used" 14 "Not used" 15 "Error Indicator" ;
VAL_ 2281833730 DMIC_IndRevModSta 0 "0FF" 1 "ON" 2 "Comfort(Normal)" 3 "Comfort+(Comfort)" 4 "ECO" 5 "Sport" 6 "Sport+" 7 "Smart" 8 "Not used" 9 "Not used" 10 "Not used" 11 "Not used" 12 "Not used" 13 "Not used" 14 "Not used" 15 "Error Indicator" ;
VAL_ 2281833730 DMIC_PrflModSta 0 "ON-OFF" 1 "ON-ON" 2 "OFF-OFF" 3 "OFF-ON" 4 "Not used" 5 "Not used" 6 "Not used" 7 "Not used" 8 "Not used" 9 "Not used" 10 "Not used" 11 "Not used" 12 "Not used" 13 "Not used" 14 "Not used" 15 "Error Indicator" ;
VAL_ 2281833730 DMIC_IndPrflModSta 0 "OFF" 1 "ON" 2 "Not used" 3 "Not used" 4 "Not used" 5 "Not used" 6 "Not used" 7 "Not used" 8 "Not used" 9 "Not used" 10 "Not used" 11 "Not used" 12 "Not used" 13 "Not used" 14 "Not used" 15 "Error Indicator" ;
VAL_ 2281833730 DMIC_ElsdModSta 0 "0FF" 1 "ON" 2 "Comfort(Normal)" 3 "Comfort+(Comfort)" 4 "ECO" 5 "Sport" 6 "Sport+" 7 "Smart" 8 "VIP" 9 "Baby" 10 "Snow" 11 "Retro" 12 "Not used" 13 "Not used" 14 "Not used" 15 "Error Indicator" ;
VAL_ 2281833730 DMIC_IndElsdModSta 0 "0FF" 1 "ON" 2 "Comfort(Normal)" 3 "Comfort+(Comfort)" 4 "ECO" 5 "Sport" 6 "Sport+" 7 "Smart" 8 "Not used" 9 "Not used" 10 "Not used" 11 "Not used" 12 "Not used" 13 "Not used" 14 "Not used" 15 "Error Indicator" ;
VAL_ 2281833730 DMIC_IndEcsModSta 0 "0FF" 1 "ON" 2 "Comfort(Normal)" 3 "Comfort+(Comfort)" 4 "ECO" 5 "Sport" 6 "Sport+" 7 "Smart" 8 "VIP" 9 "Not used" 10 "Not used" 11 "Not used" 12 "Not used" 13 "Not used" 14 "Not used" 15 "Error Indicator" ;
VAL_ 2281833730 DMIC_EsndModSta 0 "0FF" 1 "ON" 2 "Comfort(Normal)" 3 "Comfort+(Comfort)" 4 "ECO" 5 "Sport" 6 "Sport+" 7 "Smart" 8 "VIP" 9 "Baby" 10 "Snow" 11 "Retro" 12 "Not used" 13 "Not used" 14 "Not used" 15 "Error Indicator" ;
VAL_ 2281833730 DMIC_IndEsndModSta 0 "0FF" 1 "ON" 2 "Comfort(Normal)" 3 "Comfort+(Comfort)" 4 "ECO" 5 "Sport" 6 "Sport+" 7 "Smart" 8 "Not used" 9 "Not used" 10 "Not used" 11 "Not used" 12 "Not used" 13 "Not used" 14 "Not used" 15 "Error Indicator" ;
VAL_ 2281833730 DMIC_RwsModSta 0 "0FF" 1 "ON" 2 "Comfort(Normal)" 3 "Comfort+(Comfort)" 4 "ECO" 5 "Sport" 6 "Sport+" 7 "Smart" 8 "VIP" 9 "Baby" 10 "Snow" 11 "Retro" 12 "Not used" 13 "Not used" 14 "Not used" 15 "Error Indicator" ;
VAL_ 2281833730 DMIC_IndRwsModSta 0 "0FF" 1 "ON" 2 "Comfort(Normal)" 3 "Comfort+(Comfort)" 4 "ECO" 5 "Sport" 6 "Sport+" 7 "Smart" 8 "Not used" 9 "Not used" 10 "Not used" 11 "Not used" 12 "Not used" 13 "Not used" 14 "Not used" 15 "Error Indicator" ;
VAL_ 2281833730 DMIC_AwdModSta 0 "0FF" 1 "ON" 2 "Comfort(Normal)" 3 "Comfort+(Comfort)" 4 "ECO" 5 "Sport" 6 "Sport+" 7 "Smart" 8 "VIP" 9 "Baby" 10 "Snow" 11 "Retro" 12 "Not used" 13 "Not used" 14 "Not used" 15 "Error Indicator" ;
VAL_ 579 OHCL_Opt 0 "None option" 1 "Enable" ;
VAL_ 579 OHCL_Sys_sta 0 "Normal" 1 "Not Used" 2 "Not Used" 3 "System Fail" ;
VAL_ 579 OHCL_DoorOn_Sta 0 "Off" 1 "On" 2 "Not Used" 3 "System Fail" ;
VAL_ 579 OHCL_RrMapLftOn_Sta 0 "Off" 1 "On" 2 "Not Used" 3 "System Fail" ;
VAL_ 579 OHCL_RrMapRtOn_Sta 0 "Off" 1 "On" 2 "Not Used" 3 "System Fail" ;
VAL_ 579 OHCL_RrRoomOn_Sta 0 "Off" 1 "On" 2 "Not Used" 3 "System Fail" ;
VAL_ 579 OHCL_RrMoodOn_Sta 0 "Off" 1 "On" 2 "Not Used" 3 "System Fail" ;
VAL_ 579 OHCL_LEDClr_Sta 0 "Color 1Step" 1 "Color 2Step" 2 "Color 3Step" 3 "Not Used" 4 "Not Used" 5 "Not Used" 6 "Not Used" 7 "System Fail" ;
VAL_ 579 OHCL_LEDBgtns_Sta 0 "Brightness 1Step" 1 "Brightness 2Step" 2 "Brightness 3Step" 3 "Not Used" 4 "Not Used" 5 "Not Used" 6 "Not Used" 7 "System Fail" ;
VAL_ 579 OHCL_TllTlLmpSta 0 "ON Lamp off OFF Lamp off" 1 "ON Lamp off OFF Lamp on" 2 "ON Lamp on OFF Lamp off" 3 "ON Lamp on OFF Lamp on" 4 "ACU message error" 5 "Not Supported" 6 "Reserved" 7 "Lamp circuit failure" ;
VAL_ 579 OHCL_FrMapLftOn_Sta 0 "Off" 1 "On" 2 "Not Used" 3 "System Fail" ;
VAL_ 579 OHCL_RrCurtainReq 0 "Off" 1 "On" 2 "NotUsed" 3 "ErrorIndicator" ;
VAL_ 579 OHCL_FrMapRtOn_Sta 0 "Off" 1 "On" 2 "Not Used" 3 "System Fail" ;
VAL_ 579 OHCL_FrRoomOn_Sta 0 "Off" 1 "On" 2 "Not Used" 3 "System Fail" ;
VAL_ 579 OHCL_FrMoodOn_Sta 0 "Off" 1 "On" 2 "Not Used" 3 "System Fail" ;
VAL_ 1059 PSU_DiagSta 0 "Stop Diag" 1 "Start Diag" 2 "RESERVED" 3 "Error Indicator" ;
VAL_ 1059 Ast_2ndAutoRlxEnable 0 "Default" 1 "Enable" 2 "Disable" 3 "Invalid" ;
VAL_ 1059 Ast_AutoRlxSta 0 "Default" 1 "Auto Relaxion Moving" 2 "RESERVED" 3 "Invalid" ;
VAL_ 1059 PSU_EsyAcsGetOnSta 0 "off" 1 "on" 2 "RESERVED" 3 "Error Indicator" ;
VAL_ 1059 PSU_EsyAcsGetOffSta 0 "off" 1 "on" 2 "RESERVED" 3 "Error Indicator" ;
VAL_ 1059 PSU_EsyAcsStpSta 0 "off" 1 "on" 2 "RESERVED" 3 "Error Indicator" ;
VAL_ 1059 PSU_RVal 0 "Default Value" 1 "Off(Disable)" 2 "Enable" 3 "RESERVED" 4 "RESERVED" 5 "RESERVED" 6 "RESERVED" 7 "Invalid" ;
VAL_ 1086 RL_CURTAIN_POSITION 0 "Bottom" 1 "Middle" 2 "Top" 3 "Unknown(Curtain not Initialized)" ;
VAL_ 1086 RDC_SWVerMinor1 0 "0x0x0~0x7F:ASCII Code Value (HEX)" 127 "0x0x0~0x7F:ASCII Code Value (HEX)" ;
VAL_ 1086 RDC_SWVerMinor2 0 "0x0x0~0x7F:ASCII Code Value (HEX)" 127 "0x0x0~0x7F:ASCII Code Value (HEX)" ;
VAL_ 1086 RR_CURTAIN_POSITION 0 "Bottom" 1 "Middle" 2 "Top" 3 "Unknown(Curtain not Initialized)" ;
VAL_ 1086 RDC_RLDNInitFlag 0 "Off" 1 "On" 2 "Not Used" 3 "Error Indicator" ;
VAL_ 1086 RDC_RRDNInitFlag 0 "Off" 1 "On" 2 "Not Used" 3 "Error Indicator" ;
VAL_ 1086 RDC_RLOpState 0 "Off" 1 "On" 2 "Not Used" 3 "Error Indicator" ;
VAL_ 1086 RDC_RROpState 0 "Off" 1 "On" 2 "Not Used" 3 "Error Indicator" ;
VAL_ 1086 RDC_OptTyp 0 "Default" 1 "RDC Option" 2 "Not Used" 3 "Error Indicator" ;
VAL_ 1086 RDC_SWVerMajor1 0 "ASCII Code Value (HEX)" 1 "ASCII Code Value (HEX)" 2 "ASCII Code Value (HEX)" 3 "ASCII Code Value (HEX)" 4 "ASCII Code Value (HEX)" 5 "ASCII Code Value (HEX)" 6 "ASCII Code Value (HEX)" 7 "ASCII Code Value (HEX)" 8 "ASCII Code Value (HEX)" 9 "ASCII Code Value (HEX)" 10 "ASCII Code Value (HEX)" 11 "ASCII Code Value (HEX)" 12 "ASCII Code Value (HEX)" 13 "ASCII Code Value (HEX)" 14 "ASCII Code Value (HEX)" 15 "ASCII Code Value (HEX)" ;
VAL_ 1068 RLPSU_ReclMtrPos 0 "Default" 1 "Zone1" 2 "Zone2" 3 "Zone3" 4 "Zone4" 5 "PE" 6 "RESERVED" 7 "Invalid" ;
VAL_ 1068 RLPSU_RLSlidPos 0 "Default" 1 "Front Ended Position" 2 "Operating Enable" 3 "Rear Ended Position" 4 "RESERVED" 5 "RESERVED" 6 "RESERVED" 7 "Invalid" ;
VAL_ 1068 RLPSU_RLRclPos 0 "Default" 1 "Front Ended Position" 2 "Operating Enable" 3 "Rear Ended Position" 4 "RESERVED" 5 "RESERVED" 6 "RESERVED" 7 "Invalid" ;
VAL_ 1068 RLPSU_RLTiltPos 0 "Default" 1 "Upper Ended Position" 2 "Operating Enable" 3 "Lower Ended Position" 4 "RESERVED" 5 "RESERVED" 6 "RESERVED" 7 "Invalid" ;
VAL_ 1068 RLPSU_RLLegExtPos 0 "Default" 1 "Front Ended Position" 2 "Operating Enable" 3 "Rear Ended Position" 4 "RESERVED" 5 "RESERVED" 6 "RESERVED" 7 "Invalid" ;
VAL_ 1068 RLPSU_RLLegSupPos 0 "Default" 1 "Upper Ended Position" 2 "Operating Enable" 3 "Lower Ended Position" 4 "RESERVED" 5 "RESERVED" 6 "RESERVED" 7 "Invalid" ;
VAL_ 1068 RLPSU_RLHrestSlidPos 0 "Default" 1 "Front Ended Position" 2 "Operating Enable" 3 "RearEndedPosition" 4 "RESERVED" 5 "RESERVED" 6 "RESERVED" 7 "Invalid" ;
VAL_ 1068 RLPSU_RLHrestHeightPos 0 "Default" 1 "Upper Ended Position" 2 "Operating Enable" 3 "Lower  Ended Position" 4 "RESERVED" 5 "RESERVED" 6 "RESERVED" 7 "Invalid" ;
VAL_ 1068 RLPSU_Opt 0 "Default" 1 "PWR&HVU(5P Slide)" 2 "PWR&HVU(7P Walkin)" 3 "Invalid" ;
VAL_ 1068 RLPSU_Opt_Captain 0 "Default" 1 "PWR&HVU(4P Slide)" 2 "PWR&HVU(6P Walkin)" 3 "Invalid" ;
VAL_ 1068 RL_AutoRlxSta 0 "Default" 1 "Auto Relaxion Moving" 2 "Reserved" 3 "Invalid" ;
VAL_ 1068 RL_FLStAutoRlxEnable 0 "Default" 1 "Enable" 2 "Disable" 3 "Invalid" ;
VAL_ 1068 RLHVU_Opt_Captain 0 "Default" 1 "MNL&HU(4P Slide)" 2 "MNL&HU(6P Walkin)" 3 "MNL&HVU(4P Slide)" 4 "MNL&HVU(6P Walkin)" 5 "RESERVED" 6 "RESERVED" 7 "Invalid" ;
VAL_ 1068 RLPSU_PwrSeatOpt 0 "Default" 1 "5P" 2 "5P + SHVU" 3 "7P" 4 "7P + SHVU" 5 "9P" 6 "9P + SHVU" 7 "Invalid" ;
VAL_ 1068 RLPSU_PwrSeatPos 0 "Default" 1 "Front Ended Position" 2 "Moving Forward" 3 "Moving Backward" 4 "Rear Ended Position" 5 "RESERVED" 6 "RESERVED" 7 "Invalid" ;
VAL_ 1080 RL_SHVU_SeatOptSta 0 "Init" 1 "Heater only 2step" 2 "Heater only 3step" 3 "Vent only 2step" 4 "Vent only 3step" 5 "Heater and Vent 2step" 6 "Heater and Vent 3step" 7 "Invalid" ;
VAL_ 1080 RL_SHVU_SeatHtOperSta 0 "Init" 1 "RESERVED" 2 "Heater & Vent OFF" 3 "Vent Low" 4 "Vent Mid" 5 "Vent High" 6 "Heater Low" 7 "Heater Mid" 8 "Heater High" 9 "RESERVED" 10 "RESERVED" 11 "RESERVED" 12 "RESERVED" 13 "RESERVED" 14 "RESERVED" 15 "Invalid" ;
VAL_ 1080 RL_SHVU_HtSwHiIndSta_RHD 0 "OFF" 1 "ON" 2 "Not used" 3 "Error Indicator" ;
VAL_ 1080 RL_SHVU_HtSwMidIndSta_RHD 0 "OFF" 1 "ON" 2 "Not used" 3 "Error Indicator" ;
VAL_ 1080 RL_SHVU_HtSwLowIndSta_RHD 0 "OFF" 1 "ON" 2 "Not used" 3 "Error Indicator" ;
VAL_ 1080 RL_SHVU_VntSwHiIndSta_RHD 0 "OFF" 1 "ON" 2 "Not used" 3 "Error Indicator" ;
VAL_ 1080 RL_SHVU_VntSwMidIndSta_RHD 0 "OFF" 1 "ON" 2 "Not used" 3 "Error Indicator" ;
VAL_ 1080 RL_SHVU_VntSwLowIndSta_RHD 0 "OFF" 1 "ON" 2 "Not used" 3 "Error Indicator" ;
VAL_ 1080 RL_SHVU_HtBlcUsmSta_RHD 0 "Default" 1 "Normal" 2 "Back 1" 3 "Back 2" 4 "Back 3" 5 "Cush 1" 6 "Cush 2" 7 "Cush 3" 8 "Reserved" 9 "Reserved" 10 "Reserved" 11 "Reserved" 12 "Reserved" 13 "Reserved" 14 "Reserved" 15 "Invaild" ;
VAL_ 1070 RL_SHVU_HtSwHiIndSta 0 "OFF" 1 "ON" 2 "RESERVED" 3 "Error Indicator" ;
VAL_ 1070 RL_SHVU_HtSwMidIndSta 0 "OFF" 1 "ON" 2 "RESERVED" 3 "Error Indicator" ;
VAL_ 1070 RL_SHVU_HtSwLowIndSta 0 "OFF" 1 "ON" 2 "RESERVED" 3 "Error Indicator" ;
VAL_ 1070 RL_SHVU_VntSwHiIndSta 0 "OFF" 1 "ON" 2 "RESERVED" 3 "Error Indicator" ;
VAL_ 1070 RL_SHVU_VntSwMidIndSta 0 "OFF" 1 "ON" 2 "RESERVED" 3 "Error Indicator" ;
VAL_ 1070 RL_SHVU_VntSwLowIndSta 0 "OFF" 1 "ON" 2 "RESERVED" 3 "Error Indicator" ;
VAL_ 1070 RL_SHVU_HtBlcUsmSta 0 "Default" 1 "Normal" 2 "Back 1" 3 "Back 2" 4 "Back 3" 5 "Cush 1" 6 "Cush 2" 7 "Cush 3" 8 "RESERVED" 9 "RESERVED" 10 "RESERVED" 11 "RESERVED" 12 "RESERVED" 13 "RESERVED" 14 "RESERVED" 15 "Invalid" ;
VAL_ 1069 RRPSU_ReclMtrPos 0 "Default" 1 "Zone1" 2 "Zone2" 3 "Zone3" 4 "Zone4" 5 "PE" 6 "Unused" 7 "Invalid" ;
VAL_ 1069 RRPSU_PwrSeatOpt 0 "Default" 1 "5P" 2 "5P + SHVU" 3 "7P" 4 "7P + SHVU" 5 "9P" 6 "9P + SHVU" 7 "Invalid" ;
VAL_ 1069 RRPSU_PwrSeatPos 0 "Default" 1 "Front Ended Position" 2 "Moving Forward" 3 "Moving Backward" 4 "Rear Ended Position" 5 "Unused" 6 "Unused" 7 "Invalid" ;
VAL_ 1069 RRPSU_RRSlidPos 0 "Default" 1 "Front Ended Position" 2 "Operating Enable" 3 "Rear Ended Position" 4 "Unused" 5 "Unused" 6 "Unused" 7 "Invalid" ;
VAL_ 1069 RRPSU_RRRclPos 0 "Default" 1 "Front Ended Position" 2 "Operating Enable" 3 "Rear Ended Position" 4 "Unused" 5 "Unused" 6 "Unused" 7 "Invalid" ;
VAL_ 1069 RRPSU_RRTiltPos 0 "Default" 1 "Upper Ended Position" 2 "Operating Enable" 3 "Lower Ended Position" 4 "Unused" 5 "Unused" 6 "Unused" 7 "Invalid" ;
VAL_ 1069 RRPSU_RRLegExtPos 0 "Default" 1 "Front Ended Position" 2 "Operating Enable" 3 "Rear Ended Position" 4 "Unused" 5 "Unused" 6 "Unused" 7 "Invalid" ;
VAL_ 1069 RRPSU_RRLegSupPos 0 "Default" 1 "Upper Ended Position" 2 "Operating Enable" 3 "Lower Ended Position" 4 "Unused" 5 "Unused" 6 "Unused" 7 "Invalid" ;
VAL_ 1069 RRPSU_RRStEsyAcsUSMSta 0 "Default" 1 "Off(Disable)" 2 "On(Enable)" 3 "Reserved" 4 "Reserved" 5 "Reserved" 6 "Reserved" 7 "Invalid" ;
VAL_ 1069 RRPSU_RRHrestSlidPos 0 "Default" 1 "Front Ended Position" 2 "Operating Enable" 3 "Rear Ended Position" 4 "Unused" 5 "Unused" 6 "Unused" 7 "Invalid" ;
VAL_ 1069 RRPSU_RRHrestHeightPos 0 "Default" 1 "Up Ended Position" 2 "Operating Enable" 3 "Down Ended Position" 4 "" 5 "" 6 "" 7 "Invalid" ;
VAL_ 1069 RRPSU_Opt_Captain 0 "Default" 1 "PWR&HVU(4P Slide)" 2 "PWR&HVU(6P Walkin)" 3 "Invalid" ;
VAL_ 1069 RR_AutoRlxSta 0 "Default" 1 "Auto Relaxtion Moving" 2 "Reserved" 3 "Invalid" ;
VAL_ 1069 RR_FRStAutoRlxEnable 0 "Default" 1 "Enable" 2 "Disable" 3 "Invalid" ;
VAL_ 1069 RRHVU_Opt_Captain 0 "Default" 1 "MNL&HU(4P Slide)" 2 "MNL&HU(6P Walkin)" 3 "MNL&HVU(4P Slide)" 4 "MNL&HVU(6P Walkin)" 5 "RESERVED" 6 "RESERVED" 7 "Invalid" ;
VAL_ 1069 RRPSU_RLStEsyAcsUSMSta 0 "Default" 1 "Off(Disable)" 2 "On(Enable)" 3 "Reserved" 4 "Reserved" 5 "Reserved" 6 "Reserved" 7 "Invalid" ;
VAL_ 1069 RRPSU_Opt 0 "Default" 1 "PWR&HVU(5P Slide)" 2 "PWR&HVU(7P Walkin)" 3 "Invalid" ;
VAL_ 1071 RR_SHVU_HtSwHiIndSta 0 "OFF" 1 "ON" 2 "RESERVED" 3 "Error indicator" ;
VAL_ 1071 RR_SHVU_HtSwMidIndSta 0 "OFF" 1 "ON" 2 "RESERVED" 3 "Error Indicator" ;
VAL_ 1071 RR_SHVU_HtSwLowIndSta 0 "OFF" 1 "ON" 2 "RESERVED" 3 "Error Indicator" ;
VAL_ 1071 RR_SHVU_VntSwHiIndSta 0 "OFF" 1 "ON" 2 "RESERVED" 3 "Error Indictor" ;
VAL_ 1071 RR_SHVU_VntSwMidIndSta 0 "OFF" 1 "ON" 2 "RESERVED" 3 "Error Indicator" ;
VAL_ 1071 RR_SHVU_VntSwLowIndSta 0 "OFF" 1 "ON" 2 "RESERVED" 3 "Error Indicator" ;
VAL_ 1071 RR_SHVU_HtBlcUsmSta 0 "Default" 1 "Normal" 2 "Back 1" 3 "Back 2" 4 "Back 3" 5 "Cush 1" 6 "Cush 2" 7 "Cush 3" 8 "RESERVED" 9 "RESERVED" 10 "RESERVED" 11 "RESERVED" 12 "RESERVED" 13 "RESERVED" 14 "RESERVED" 15 "Invalid" ;
VAL_ 1073 USM_ValCmdSta 0 "Default" 1 "Off(Disable)" 2 "On(Enable)" 3 "Invalid" ;
VAL_ 1073 RWPC_SWVerMinor1 0 "0x0x0~0x7F:ASCII Code Value (HEX)" 127 "0x0x0~0x7F:ASCII Code Value (HEX)" ;
VAL_ 1073 WPC_PhnLftWrngRWPCSta 0 "Off" 1 "Cellphone on the pad" 2 "Charging" 3 "Charging complete" 4 "Cellphone reminder" 5 "Error" 6 "Reserved" 7 "Invalid" ;
VAL_ 1073 RWPC_SWVerMinor2 0 "0x0x0~0x7F:ASCII Code Value (HEX)" 127 "0x0x0~0x7F:ASCII Code Value (HEX)" ;
VAL_ 1073 USM_ValCmdStaforATS 0 "Default" 1 "Off(Disable)" 2 "On(Enable)" 3 "Invalid" ;
VAL_ 1073 RWPC_SWVerMajor1 0 "ASCII Code Value (HEX)" 1 "ASCII Code Value (HEX)" 2 "ASCII Code Value (HEX)" 3 "ASCII Code Value (HEX)" 4 "ASCII Code Value (HEX)" 5 "ASCII Code Value (HEX)" 6 "ASCII Code Value (HEX)" 7 "ASCII Code Value (HEX)" 8 "ASCII Code Value (HEX)" 9 "ASCII Code Value (HEX)" 10 "ASCII Code Value (HEX)" 11 "ASCII Code Value (HEX)" 12 "ASCII Code Value (HEX)" 13 "ASCII Code Value (HEX)" 14 "ASCII Code Value (HEX)" 15 "ASCII Code Value (HEX)" ;
VAL_ 2160080129 VCU_RdySta 0 "None" 1 "VCU Control Board Ready" 2 "Not used" 3 "Error Indicator" ;
VAL_ 2160080129 VCU_StartKeyHoldSta 0 "None" 1 "Start" 2 "Not used" 3 "Error Indicator" ;
VAL_ 2160080129 VCU_EvDrvRdySta 0 "None" 1 "EV Drivable" 2 "Not used" 3 "Error Indicator" ;
VAL_ 2160080129 VCU_MotPwrEnReq 0 "None" 1 "Allow Motor System to Control" 2 "Not used" 3 "Error Indicator" ;
VAL_ 2160080129 VCU_GearPosSta 0 "P" 1 "B" 2 "Not Used" 3 "Not Used" 4 "Not Used" 5 "D" 6 "N" 7 "R" 8 "Not Used" 9 "Not Display at Cluster" 10 "Reserved" 11 "Reserved" 12 "Reserved" 13 "Reserved" 14 "Intermediate Position" 15 "Fault" ;
VAL_ 2160080129 VCU_LdcInhReq 0 "None" 1 "LDC Off Request" 2 "Not used" 3 "Error Indicator" ;
VAL_ 2160080129 VCU_MainRlyOffReq 0 "None" 1 "Relay Cut Off" 2 "Not used" 3 "Error Indicator" ;
VAL_ 2160080129 VCU_AccPedDepVal 255 "Error Indicator" ;
VAL_ 2160080129 VCU_FatcOperPermSta 0 "Not Permiited" 1 "Permitted" 2 "Not used" 3 "Error Indicator" ;
VAL_ 2160080129 VCU_DrvCycSta 0 "No Driving Cycle Active" 1 "Driving Cycle Active" 2 "Not used" 3 "Error Indicator" ;
VAL_ 2160080129 VCU_CltActOpSta 0 "Neutral" 1 "Actuating" 2 "In Gear" 3 "Referencing" 4 "Fault" ;
VAL_ 2160080129 VCU_WhlSpdSnsrAlvReq 0 "No Request" 1 "Alive Request" 2 "Not used" 3 "Error Indicator" ;
VAL_ 2160080129 VCU_DrvModOpSta 0 "Eco" 1 "Normal" 2 "Sport" 3 "Reserved" 4 "Reserved" 5 "Snow" 6 "Sand" 7 "Mud" 8 "Reserved" 9 "Reserved" 10 "Reserved" 11 "Reserved" 12 "Reserved" 13 "Reserved" 14 "Reserved" 15 "Reserved" ;
VAL_ 2160080129 VCU_IgOffGearPosStaDispReq 0 "No Request" 1 "Request" 2 "Not used" 3 "Error indicator" ;
VAL_ 2160080131 VCU_EcmSeqSta 0 "IG Off" 1 "IG On_PowerLatch" 2 "IG On Init" 3 "IG On_Rdy" 4 "IG On_Drivalble" 5 "IG On_PD" 6 "IGON_NonDrivable" ;
VAL_ 2160080131 VCU_MainBattTypeSta 0 "Short Range Type" 1 "Standard Range Type" 2 "Long Range Type" 3 "Not Used" ;
VAL_ 2160080131 VCU_MainBattTypeLrnSta 0 "Unlearnt" 1 "Learnt" 2 "Not used" 3 "Error Indicator" ;
VAL_ 2160080131 VCU_WarmupCycSta 0 "None" 1 "Warm-up Cycle Completed" 2 "Not used" 3 "Error Indicator" ;
VAL_ 2160080132 VCU_GearPosStaDisp 0 "P" 1 "B" 2 "Not Used" 3 "Not Used" 4 "Not Used" 5 "D" 6 "N" 7 "R" 8 "Not Used" 9 "Not Display at Cluster" 10 "Reserved" 11 "Reserved" 12 "Manual Shift Mode on Retromode" 13 "Reserved" 14 "Intermediate Position" 15 "Fault" ;
VAL_ 2160080132 VCU_PdwLmtOperSta 0 "Off" 1 "On" 2 "Reserved" 3 "Reserved" ;
VAL_ 2160080132 VCU_PdwLmtBrkRequest 0 "Off" 1 "On" 2 "Reserved" 3 "Reserved" ;
VAL_ 2160080132 VCU_VgsVirSoundBackFireIndex 0 "No Action Status" 1 "Tip-Out Back Fire Lv1 ~ Lv8" 2 "Tip-Out Back Fire Lv1 ~ Lv8" 3 "Tip-Out Back Fire Lv1 ~ Lv8" 4 "Tip-Out Back Fire Lv1 ~ Lv8" 5 "Tip-Out Back Fire Lv1 ~ Lv8" 6 "Tip-Out Back Fire Lv1 ~ Lv8" 7 "Tip-Out Back Fire Lv1 ~ Lv8" 8 "Tip-Out Back Fire Lv1 ~ Lv8" 17 "Bubbling Sound Lv1 ~ Lv8" 18 "Bubbling Sound Lv1 ~ Lv8" 19 "Bubbling Sound Lv1 ~ Lv8" 20 "Bubbling Sound Lv1 ~ Lv8" 21 "Bubbling Sound Lv1 ~ Lv8" 22 "Bubbling Sound Lv1 ~ Lv8" 23 "Bubbling Sound Lv1 ~ Lv8" 24 "Bubbling Sound Lv1 ~ Lv8" 9 "Upshift BANG Sound Lv1 ~ Lv8" 10 "Upshift BANG Sound Lv1 ~ Lv8" 11 "Upshift BANG Sound Lv1 ~ Lv8" 12 "Upshift BANG Sound Lv1 ~ Lv8" 13 "Upshift BANG Sound Lv1 ~ Lv8" 14 "Upshift BANG Sound Lv1 ~ Lv8" 15 "Upshift BANG Sound Lv1 ~ Lv8" 16 "Upshift BANG Sound Lv1 ~ Lv8" ;
VAL_ 2160080132 VCU_VgsVirEngSpdRpmVal 0 "0x0x0~0x7FFE:RPM" 32766 "0x0x0~0x7FFE:RPM" 32767 "Error Indicator" ;
VAL_ 2160080132 VCU_PdlStopCtrlSta 0 "No Request" 1 "Target brake torque control request" 2 "AVH request" 3 "AVH working" ;
VAL_ 2160080132 VCU_VgsVirSoundVolume 0 "0x0x0~0xFE:0~100%" 254 "0x0x0~0xFE:0~100%" 0 "0x0~0xFF:Invalid Error" 255 "0x0~0xFF:Invalid Error" ;
VAL_ 2160080132 VCU_VgsVirGearStep 0 "Not Used" 1 "1gear" 2 "2gear" 3 "3gear" 4 "4gear" 5 "5gear" 6 "6gear" 7 "7gear" 8 "8gear" 9 "Reserved" 10 "Reserved" 11 "Reserved" 12 "Reserved" 13 "Reserved" 14 "Reserved" 15 "Reserved" ;
VAL_ 2160080132 VCU_PdlStopReqTqNmVal 0 "0x0x0~0xFFFF:Request brake torque for stop assist control" 65535 "0x0x0~0xFFFF:Request brake torque for stop assist control" ;
